VERSION ""

NS_ :

BS_:

BU_: BCMB_AUXM FCIM MRCMA_RSCM SCMJ BCMB_ALCM SCMB_PSM SCMD SCMC HVAC_RCCM MRCMB MRCMA DASM GFM_FTRM BCMB_CAPM DCMH SFMB SFMA SOBDMD_AHCM_FOH TRM GWM _delete BCMB_ABM SODL SCMF RTM RHVAC PDM DCMG DCMF DCME SCMH SCMG HSWM RSM SODR DDM RBM RGTM DSM SCME GENERIC TSTR
VAL_TABLE_ PersCtaSplitView_D_Rq 3 "EnabledFull" 2 "Enabled_180SwitchOnly" 1 "Disabled" 0 "Null" ;
VAL_TABLE_ HvacMde_D_ET 7 "NotUsed_4" 6 "NotUsed_3" 5 "NotUsed_2" 4 "NotUsed_1" 3 "Auto" 2 "MaxDefrost" 1 "MaxAc" 0 "Null" ;
VAL_TABLE_ SeatTe_D_ET 15 "NotUsed_7" 14 "NotUsed_6" 13 "NotUsed_5" 12 "NotUsed_4" 11 "NotUsed_3" 10 "NotUsed_2" 9 "NotUsed_1" 8 "Auto" 7 "Cooled3" 6 "Cooled2" 5 "Cooled1" 4 "Heated3" 3 "Heated2" 2 "Heated1" 1 "Off" 0 "Null" ;
VAL_TABLE_ Null_Off_On_Auto 3 "Auto" 2 "On" 1 "Off" 0 "Null" ;
VAL_TABLE_ NotDetClosedAjarDisabled 5 "NotUsed_2" 4 "NotUsed_1" 3 "Disabled" 2 "Ajar" 1 "Closed" 0 "NotDetermined" 7 "Faulty" 6 "NotUsed_3" ;
VAL_TABLE_ TwoStatePressedNotPressed 3 "NotDetermined" 2 "SwitchState2" 1 "SwitchState1" 0 "NotPressed" ;
VAL_TABLE_ Rear_Temp 15 "NotUsed_6" 14 "NotUsed_5" 13 "NotUsed_4" 12 "NotUsed_3" 11 "NotUsed_2" 10 "NotUsed_1" 9 "Max_Heating" 8 "Level_3_Heating" 7 "Level_2_Heating" 6 "Level_1_Heating" 5 "No_Heating_Cooling" 4 "Level_1_Cooling" 3 "Level_2_Cooling" 2 "Level_3_Cooling" 1 "Max_Cooling" 0 "No_Request" ;
VAL_TABLE_ DrHandle_D_Stat 7 "NotUsed" 6 "Transition" 5 "FlushFault" 4 "DeployFault2" 3 "DeployFault1" 2 "Flush" 1 "Deploy" 0 "None" ;
VAL_TABLE_ HvacCmprLim_D_Stat 7 "NotUsed_2" 6 "NotUsed_1" 5 "CompressorHeadPressure" 4 "AvailableTorque" 3 "PedalPosition" 2 "RPM" 1 "ECT" 0 "NoLimit" ;
VAL_TABLE_ VehOnSrc_D_Stat 15 "NotUsed_11" 14 "NotUsed_10" 13 "NotUsed_9" 12 "NotUsed_8" 11 "NotUsed_7" 10 "NotUsed_6" 9 "EsclRssd" 8 "AutonomousVehicle" 7 "SecureIdle" 6 "FleetVehicleInhibit" 5 "StolenVehicleInhibit" 4 "OverTheAir" 3 "RemoteParkAssist" 2 "RemoteStart" 1 "Manual" 0 "Off" ;
VAL_TABLE_ NoMessage_Msg1_63 31 "Message31" 30 "Message30" 29 "Message29" 28 "Message28" 27 "Message27" 26 "Message26" 25 "Message25" 24 "Message24" 23 "Message23" 22 "Message22" 21 "Message21" 20 "Message20" 19 "Message19" 18 "Message18" 17 "Message17" 16 "Message16" 15 "Message15" 14 "Message14" 13 "Message13" 12 "Message12" 11 "Message11" 10 "Message10" 9 "Message9" 8 "Message8" 7 "Message7" 6 "Message6" 5 "Message5" 4 "Message4" 3 "Message3" 2 "Message2" 1 "Message1" 0 "NoMessage" 63 "Message63" 47 "Message47" ;
VAL_TABLE_ TrlrRvrseEnbl_D2_Stat 7 "NotUsed" 6 "TbaActiveExpertActive" 5 "TbaActiveExpertAvail" 4 "TbaOffTrgActive" 3 "TbaOffTrgSetup" 2 "TbaSetup" 1 "TbaActive" 0 "Inactive" ;
VAL_TABLE_ SwitchNotActive_Active 1 "Switch_Active" 0 "Switch_Not_Active" ;
VAL_TABLE_ LcwaLeft_D_Stat 7 "Faulty" 6 "NotUsed_3" 5 "NotUsed_2" 4 "NotUsed_1" 3 "Disabled" 2 "TemporaryUnavailable" 1 "SensorBlocked" 0 "Available" ;
VAL_TABLE_ SeatMasgDrvRr_D_Stat 15 "NotUsed_10" 14 "NotUsed_9" 13 "NotUsed_8" 12 "NotUsed_7" 11 "NotUsed_6" 10 "Pattern10" 9 "Pattern9" 8 "Pattern8" 7 "Pattern7" 6 "Pattern6" 5 "Pattern5" 4 "Pattern4" 3 "Pattern3" 2 "Pattern2" 1 "Pattern1" 0 "Null" ;
VAL_TABLE_ CamraRearOn_D2_Stat2 7 "Faulty" 6 "NotUsed_3" 5 "NotUsed_2" 4 "NotUsed_1" 3 "Decommission" 2 "Activate" 1 "Deactivate" 0 "Null" ;
VAL_TABLE_ OffNormalSoft 3 "NotUsed" 2 "Soft" 1 "Normal" 0 "Off" ;
VAL_TABLE_ OffOnDisabledInhibited 3 "Inhibited" 2 "Disabled" 1 "On" 0 "Off" ;
VAL_TABLE_ SldrrMsgTxt_D2_Rq 7 "NotUsed_3" 6 "NotUsed_2" 5 "NotUsed_1" 4 "SlidingDrCalibNeeded2" 3 "SlidingDrOpenCltchReleased" 2 "SlidingDrCalibNeeded" 1 "SlidingDrClutchReleased" 0 "Null" ;
VAL_TABLE_ SeatPsngrMem_D_Cmd 15 "NotUsed_7" 14 "NotUsed_6" 13 "NotUsed_5" 12 "NotUsed_4" 11 "NotUsed_3" 10 "NotUsed_2" 9 "NotUsed_1" 8 "RECALL_4" 7 "RECALL_3" 6 "RECALL_2" 5 "RECALL_1" 4 "STORE_4" 3 "STORE_3" 2 "STORE_2" 1 "STORE_1" 0 "Null" ;
VAL_TABLE_ Null_NoFault_Fault 3 "NotUsed" 2 "Fault" 1 "NoFault" 0 "Null" ;
VAL_TABLE_ PrkAsstSlotId_D_Stat 7 "Faulty" 6 "Slot6" 5 "Slot5" 4 "Slot4" 3 "Slot3" 2 "Slot2" 1 "Slot1" 0 "NoSlotFound" ;
VAL_TABLE_ SodSlotLeft_D_Stat 7 "Faulty" 6 "Slot6" 5 "Slot5" 4 "Slot4" 3 "Slot3" 2 "Slot2" 1 "Slot1" 0 "NoSlotFound" ;
VAL_TABLE_ PwStepLeft_D_Rq 1 "Deploy" 0 "Null" 3 "NotUsed" 2 "Stow" ;
VAL_TABLE_ SldrlUnlckSwtch_D_Stat 3 "InnerHandle" 2 "RearInteriorSwitch" 1 "IpSwitch" 0 "Null" ;
VAL_TABLE_ SldrlChime_D_Rq 7 "NotUsed3" 6 "NotUsed2" 5 "NotUsed1" 4 "Warning" 3 "WarningRepeated" 2 "Programming" 1 "Operation" 0 "Off" ;
VAL_TABLE_ Sldrl_D_Stat 3 "NotCalibrated" 2 "Closing" 1 "Opening" 0 "NotMoving" ;
VAL_TABLE_ BalrInnrLeft_D_Stat 3 "Reporting" 2 "NotReporting" 1 "SystemStandby" 0 "Initialization" ;
VAL_TABLE_ Zero_1_2_4 3 "Four" 2 "Two" 1 "One" 0 "Zero" ;
VAL_TABLE_ NoReq_AutoUp_Stop 3 "NotUsed" 2 "Stop" 1 "AutoUp" 0 "NoRequest" ;
VAL_TABLE_ BalrSnsLeft_D_Falt 3 "Invalid" 2 "SystemFailure" 1 "Blocked" 0 "Clear" ;
VAL_TABLE_ Null_Low_Med_High 3 "High" 2 "Medium" 1 "Low" 0 "Null" ;
VAL_TABLE_ Null_NotPressed_Pressed 3 "NotUsed" 2 "Pressed" 1 "NotPressed" 0 "Null" ;
VAL_TABLE_ Low_Med_High 3 "NotUsed" 2 "High" 1 "Medium" 0 "Low" ;
VAL_TABLE_ TailLghtLoadMde_D_Stat 7 "Faulty" 6 "NotUsed_2" 5 "NotUsed_1" 4 "TailLightModeOverride" 3 "FalrModeActive" 2 "HitchLoadModeActive" 1 "PayloadModeActive" 0 "NoTailLightActive" ;
VAL_TABLE_ Set_Temp_Dig2 15 "Blank2" 14 "Blank1" 13 "I" 12 "H" 11 "O" 10 "L" 9 "_9" 8 "_8" 7 "_7" 6 "_6" 5 "_5" 4 "_4" 3 "_3" 2 "_2" 1 "_1" 0 "_0" ;
VAL_TABLE_ Manual_Temp_Setting 31 "Full_Heat" 30 "Setting_30" 29 "Setting_29" 28 "Setting_28" 27 "Setting_27" 26 "Setting_26" 25 "Setting_25" 24 "Setting_24" 23 "Setting_23" 22 "Setting_22" 21 "Setting_21" 20 "Setting_20" 19 "Setting_19" 18 "Setting_18" 17 "Setting_17" 16 "Setting_16" 15 "Setting_15" 14 "Setting_14" 13 "Setting_13" 12 "Setting_12" 11 "Setting_11" 10 "Setting_10" 9 "Setting_9" 8 "Setting_8" 7 "Setting_7" 6 "Setting_6" 5 "Setting_5" 4 "Setting_4" 3 "Setting_3" 2 "Setting_2" 1 "Full_Cool" 0 "Off" ;
VAL_TABLE_ Low_Med_High_Faulty 3 "Faulty" 2 "High" 1 "Medium" 0 "Low" ;
VAL_TABLE_ PulledAtRest 1 "Pulled" 0 "AtRest" ;
VAL_TABLE_ TrlrAidMsgTxt_D2_Rq 63 "Message63" 62 "Message62" 61 "Message61" 60 "Message60" 55 "Message55" 50 "Message50" 45 "Message45" 40 "Message40" 35 "Message35" 31 "Message31" 30 "Message30" 29 "Message29" 28 "Message28" 27 "Message27" 26 "Message26" 25 "Message25" 24 "Message24" 23 "Message23" 22 "Message22" 21 "Message21" 20 "Message20" 19 "Message19" 18 "Message18" 17 "Message17" 16 "Message16" 15 "Message15" 14 "Message14" 13 "Message13" 12 "Message12" 11 "Message11" 10 "Message10" 9 "Message9" 8 "Message8" 7 "Message7" 6 "Message6" 5 "Message5" 4 "Message4" 3 "Message3" 2 "Message2" 1 "Message1" 0 "NoMessage" ;
VAL_TABLE_ TrlrAidEnbl_D2_Stat 7 "NotUsed_1" 6 "TbaActiveExpertActive" 5 "TbaActiveExpertAvail" 4 "TbaOffTrgActive" 3 "TbaOffTrgSetup" 2 "TbaSetup" 1 "TbaActive" 0 "Inactive" ;
VAL_TABLE_ RbaCta_D_Stat 7 "Faulty" 6 "NotUsed_2" 5 "NotUsed_1" 4 "Invalid" 3 "Disabled" 2 "On" 1 "Trailer_Tow_Off" 0 "Off" ;
VAL_TABLE_ SeatFnChng2 15 "Faulty" 14 "NotUsed9" 13 "NotUsed8" 12 "NotUsed7" 11 "NotUsed6" 10 "High_2" 9 "Med_2" 8 "Low_2" 7 "Off_2" 6 "High" 5 "Low" 4 "Off" 3 "Decrease" 2 "Increase" 1 "NotUsed1" 0 "Inactive" ;
VAL_TABLE_ OffOnDisabledNotUsed 3 "NotUsed" 2 "Disabled" 1 "On" 0 "Off" ;
VAL_TABLE_ Off_On_NotUsed 3 "NotUsed_2" 2 "NotUsed_1" 1 "On" 0 "Off" ;
VAL_TABLE_ RbaSys_D_Stat 3 "Faulty" 2 "Available" 1 "Suspended" 0 "Disabled" ;
VAL_TABLE_ SeatLmbr_D_Rq 15 "NotUsed_7" 14 "NotUsed_6" 13 "NotUsed_5" 12 "NotUsed_4" 11 "NotUsed_3" 10 "NotUsed_2" 9 "NotUsed_1" 8 "PassengerDown" 7 "PassengerUp" 6 "PassengerAft" 5 "PassengerFore" 4 "DriverDown" 3 "DriverUp" 2 "DriverAft" 1 "DriverFore" 0 "Null" ;
VAL_TABLE_ Inactive_Enable_Disable 0 "Inactive" 2 "Disable" 1 "Enable" ;
VAL_TABLE_ PmSnsCabn_D_Stat 7 "NotUsed_1" 6 "IntermittentInhibit" 5 "NoIssue" 4 "BlankField" 3 "ReplaceSensor" 2 "CleanSensor" 1 "Unsupported" 0 "Initializing" ;
VAL_TABLE_ Null_Off_LowMedHigh 7 "NotUsed_3" 6 "NotUsed_2" 5 "NotUsed_1" 4 "High" 3 "Medium" 2 "Low" 1 "Off" 0 "Null" ;
VAL_TABLE_ SeatMasgDrv_D_Stat 15 "NotUsed_10" 14 "NotUsed_9" 13 "NotUsed_8" 12 "NotUsed_7" 11 "NotUsed_6" 10 "Pattern10" 9 "Pattern9" 8 "Pattern8" 7 "Pattern7" 6 "Pattern6" 5 "Pattern5" 4 "Pattern4" 3 "Pattern3" 2 "Pattern2" 1 "Pattern1" 0 "Null" ;
VAL_TABLE_ ClimtSeat_D_Rq 128 "H3_High_Heat_MAX" 64 "H2_Medium_Heat" 32 "H1_Low_Heat" 16 "C3_High_Cool_MAX" 8 "C2_Medium_Cool" 4 "C1_Low_Cool" 2 "Off" ;
VAL_TABLE_ NoFault_Fault 1 "Fault" 0 "No_Fault" ;
VAL_TABLE_ ClimtRearView_D_Stat 3 "ThirdRow" 2 "SecondRow" 1 "Both" 0 "NotDisplayed" ;
VAL_TABLE_ NoInhibit_Inhibit 1 "Inhibit" 0 "NoInhibit" ;
VAL_TABLE_ PersRecallSrc_D_Actl 7 "NotUsed_3" 6 "NotUsed_2" 5 "NotUsed_1" 4 "MemorySwitch" 3 "RemoteStart" 2 "KeyFob" 1 "CenterStack" 0 "Null" ;
VAL_TABLE_ TrnkFrontRleas_D_Src 7 "NotUsed_3" 6 "NotUsed_2" 5 "NotUsed_1" 4 "Cpp" 3 "Sync" 2 "Keypad" 1 "Remote" 0 "Null" ;
VAL_TABLE_ Frt_Btn_Status_1st 4 "Floor_Ws_Pressed" 5 "AC_Pressed" 6 "Dual_Pressed" 7 "LHS_Temp_Inc_Pressed" 0 "None_Pressed" 1 "Panel_Pressed" 2 "Panel_Floor_Pressed" 3 "Floor_Pressed" 8 "LHS_Temp_Dec_Pressed" 9 "RHS_Temp_Inc_Pressed" 10 "RHS_Temp_Dec_Pressed" 11 "Blwr_Inc_Pressed" 12 "Blwr_Dec_Pressed" 13 "AUTO_Pressed" 14 "Max_AC_Pressed" 15 "Recirc_Pressed" 16 "Outside_Pressed" 17 "Auto_Recirc_Pressed" 18 "Htd_Frt_Wsh_Pressed" 19 "Windscreen_Pressed" 20 "Pnl_Ws_Pressed" 21 "Pnl_Flr_Ws_Pressed" 22 "Rear_Defrost_Pressed" 23 "Front_Power_Pressed" 24 "My_Temp_Pressed" 25 "Max_Defrost_Pressed" 26 "LHS_Htd_Seat_Pressed" 27 "RHS_Htd_Seat_Pressed" 28 "LHS_Cld_Seat_Pressed" 29 "RHS_Cld_Seat_Pressed" 30 "Htg_Strg_Whl_Pressed" 31 "Defrost_Pressed" 37 "DrvrFcsdMde_PRessed" 38 "LHS_Seat_Off_Pressed" 39 "LHS_Htd_Seat1_Pressed" 40 "LHS_Htd_Seat2_Pressed" 41 "LHS_Htd_Seat3_Pressed" 42 "LHS_Auto_Seat_Pressed" 43 "RHS_Seat_Off_Pressed" 44 "RHS_Htd_Seat1_Pressed" 45 "RHS_Htd_Seat2_Pressed" 46 "RHS_Htd_Seat3_Pressed" 47 "RHS_Auto_Seat_Pressed" 48 "LHS_Cld_Seat1_Pressed" 49 "LHS_Cld_Seat2_Pressed" 50 "LHS_Cld_Seat3_Pressed" 51 "RHS_Cld_Seat1_Pressed" 52 "RHS_Cld_Seat2_Pressed" 53 "RHS_Cld_Seat3_Pressed" 54 "AUTO_Lo_Pressed" 55 "AUTO_Med_Pressed" 56 "AUTO_Hi_Pressed" 57 "AUTO_Inc_Pressed" 58 "AUTO_Dec_Pressed" 59 "NotUsed_6" 60 "NotUsed_7" 61 "NotUsed_8" 62 "NotUsed_9" 63 "NotUsed_10" 32 "FrontMnu_Pressed" 33 "RearMnu_Pressed" 34 "Heat_Pressed" 35 "AAR_Pressed" 36 "MdeMnu_Pressed" ;
VAL_TABLE_ TrlrAlarmSpprt_D_Stat 3 "SupportedByBrakesAndLights" 2 "SupportedByLights" 1 "SupportedByBrakes" 0 "NotSupported" ;
VAL_TABLE_ Null_Extend_Retract 3 "NotUsed" 2 "Retract" 1 "Extend" 0 "Null" ;
VAL_TABLE_ SeatSlprPosPsngr_D_Stat 3 "Faulty" 2 "Sleeper" 1 "Upright" 0 "Null" ;
VAL_TABLE_ Psngr_Set_Temp 31 "HI" 30 "_29_5" 29 "_29_0" 28 "_28_5" 27 "_28_0" 26 "_27_5" 25 "_27_0" 24 "_26_5" 23 "_26_0" 22 "_25_5" 21 "_25_0" 20 "_24_5" 19 "_24_0" 18 "_23_5" 17 "_23_0" 16 "_22_5" 15 "_22_0" 14 "_21_5" 13 "_21_0" 12 "_20_5" 11 "_20_0" 10 "_19_5" 9 "_19_0" 8 "_18_5" 7 "_18_0" 6 "_17_5" 5 "_17_0" 4 "_16_5" 3 "_16_0" 2 "_15_5" 1 "LO" 0 "No_Request" ;
VAL_TABLE_ Frt_Blower_Speed2 15 "NotUsed_6" 14 "NotUsed_5" 13 "NotUsed_4" 12 "NotUsed_3" 11 "NotUsed_2" 10 "Zero_Blower" 9 "Max_Blower" 8 "Min_Blower" 7 "Blower_Speed_7" 6 "Blower_Speed_6" 5 "Blower_Speed_5" 4 "Blower_Speed_4" 3 "Blower_Speed_3" 2 "Blower_Speed_2" 1 "Blower_Speed_1" 0 "No_Request" ;
VAL_TABLE_ KeyPadCodeDgt1_D_Stat 15 "NotUsed_4" 14 "NotUsed_3" 13 "NotUsed_2" 12 "NotUsed_1" 11 "Button7_8and9_0" 10 "Button0" 9 "Button9_0or9" 8 "Button8" 7 "Button7_8or7" 6 "Button6" 5 "Button5_6or5" 4 "Button4" 3 "Button3_4or3" 2 "Button2" 1 "Button1_2or1" 0 "EndofString" ;
VAL_TABLE_ E_Frt_Btn_Status_1st 63 "NotUsed_10" 62 "NotUsed_9" 61 "NotUsed_8" 60 "NotUsed_7" 59 "NotUsed_6" 58 "NotUsed_5" 57 "NotUsed_4" 56 "NotUsed_3" 55 "NotUsed_2" 54 "NotUsed_1" 53 "RHS_Cld_Seat3_Pressed" 52 "RHS_Cld_Seat2_Pressed" 51 "RHS_Cld_Seat1_Pressed" 50 "LHS_Cld_Seat3_Pressed" 49 "LHS_Cld_Seat2_Pressed" 48 "LHS_Cld_Seat1_Pressed" 47 "RHS_Auto_Seat_Pressed" 46 "RHS_Htd_Seat3_Pressed" 45 "RHS_Htd_Seat2_Pressed" 44 "RHS_Htd_Seat1_Pressed" 43 "RHS_Seat_Off_Pressed" 42 "LHS_Auto_Seat_Pressed" 41 "LHS_Htd_Seat3_Pressed" 40 "LHS_Htd_Seat2_Pressed" 39 "LHS_Htd_Seat1_Pressed" 38 "LHS_Seat_Off_Pressed" 37 "DrvrFcsdMde_Pressed" 36 "MdeMnu_Pressed" 35 "AAR_Pressed" 34 "Heat_Pressed" 33 "RearMnu_Pressed" 32 "FrontMnu_Pressed" 31 "Defrost_Pressed" 30 "Htg_Strg_Whl_Pressed" 29 "RHS_Cld_Seat_Pressed" 28 "LHS_Cld_Seat_Pressed" 27 "RHS_Htd_Seat_Pressed" 26 "LHS_Htd_Seat_Pressed" 25 "Max_Defrost_Pressed" 24 "My_Temp_Pressed" 23 "Front_Power_Pressed" 22 "Rear_Defrost_Pressed" 21 "Pnl_Flr_Ws_Pressed" 20 "Pnl_Ws_Pressed" 19 "Windscreen_Pressed" 18 "Htd_Frt_Wsh_Pressed" 17 "Auto_Recirc_Pressed" 16 "Outside_Pressed" 15 "Recirc_Pressed" 14 "Max_AC_Pressed" 13 "Auto_Pressed" 12 "Blwr_Dec_Pressed" 11 "Blwr_Inc_Pressed" 10 "RHS_Temp_Dec_Pressed" 9 "RHS_Temp_Inc_Pressed" 8 "LHS_Temp_Dec_Pressed" 7 "LHS_Temp_Inc_Pressed" 6 "Dual_Pressed" 5 "AC_Pressed" 4 "Floor_Ws_Pressed" 3 "Floor_Pressed" 2 "Panel_Floor_Pressed" 1 "Panel_Pressed" 0 "None_Pressed" ;
VAL_TABLE_ Null_Restricted_NotRestricted 3 "NotUsed" 2 "NotRestricted" 1 "Restricted" 0 "Null" ;
VAL_TABLE_ UltraFreshCabn_D_Stat 7 "NotUsed_2" 6 "NotUsed_1" 5 "NotSupported" 4 "Interrupted" 3 "Complete" 2 "Active" 1 "Inactive" 0 "Null" ;
VAL_TABLE_ GearLvr_D_ActlDrv 15 "Fault" 14 "Unknown_Position" 13 "NotUsed_2" 12 "NotUsed_1" 11 "Range6" 10 "Range5" 9 "Range4" 8 "Range3_M3_L3" 7 "Range2_M2_L2" 6 "Range1_M1_L1" 5 "Low" 4 "Sport_DriveSport_Mposition" 3 "Drive" 2 "Neutral" 1 "Reverse" 0 "Park" ;
VAL_TABLE_ TrnPrkSys_D_Actl 15 "Faulty" 14 "NotUsed_5" 13 "NotUsed_4" 12 "NotUsed_3" 11 "NotUsed_2" 10 "NotUsed_1" 9 "FrequencyError" 8 "OutOfRangeHigh" 7 "OutOfRangeLow" 6 "Override" 5 "OutOfPark" 4 "TransitionCloseToOutOfPark" 3 "AtNoSpring" 2 "TransitionCloseToPark" 1 "Park" 0 "NotKnown" ;
VAL_TABLE_ OKLowUnknownInvalid 3 "Invalid" 2 "Unknown" 1 "Low" 0 "OK" ;
VAL_TABLE_ Dsp_RotAddrBtnEv_St 15 "NotUsed_1" 14 "Pos_7Steps" 13 "Pos_6Steps" 12 "Pos_5Steps" 11 "Pos_4Steps" 10 "Pos_3Steps" 9 "Pos_2Steps" 8 "Pos_1Step" 7 "NotPressed" 6 "Neg_1Steps" 5 "Neg_2Steps" 4 "Neg_3Steps" 3 "Neg_4Steps" 2 "Neg_5Steps" 1 "Neg_6Steps" 0 "Neg_7Steps" ;
VAL_TABLE_ Pers1Phone_D_Stat 7 "SevenPhoneAssociated" 6 "SixPhoneAssociated" 5 "FivePhoneAssociated" 4 "FourPhoneAssociated" 3 "ThreePhoneAssociated" 2 "TwoPhoneAssociated" 1 "OnePhoneAssociated" 0 "NoPhoneAssociated" ;
VAL_TABLE_ GasPrtc_D_RqDsply 7 "NotUsed_5" 6 "NotUsed_4" 5 "NotUsed_3" 4 "NotUsed_2" 3 "NotUsed_1" 2 "GpfOverLimit" 1 "GpfAtLimit" 0 "NormalOperation" ;
VAL_TABLE_ Memory_2_SwPsngr_Stat 1 "Pressed" 0 "Null" ;
VAL_TABLE_ Pers3Key_D_Stat 3 "NotUsed_1" 2 "KeyUnAssociated" 1 "KeyAssociated" 0 "Null" ;
VAL_TABLE_ WakeAlarm0_B_Typ 1 "CanAndEcuDriveCircuit" 0 "CanOnly" ;
VAL_TABLE_ EmPrflNo_D_Rq 7 "NotUsed_3" 6 "NotUsed_2" 5 "NotUsed_1" 4 "Pers4" 3 "Pers3" 2 "Pers2" 1 "Pers1" 0 "Null" ;
VAL_TABLE_ EmPrflKeyAssoc_D_Rq 7 "NotUsed_3" 6 "DisassociatePhone" 5 "EnterPhoneAssociation" 4 "OverwriteKey" 3 "DisassociateKey" 2 "ExitKeyAssociation" 1 "EnterKeyAssociation" 0 "Null" ;
VAL_TABLE_ EmButtn_D_Stat 7 "ButtonAssociationFailed" 6 "ButtonAssociationExited" 5 "ButtonAssociationEntered" 4 "Button4Pressed" 3 "Button3Pressed" 2 "Button2Pressed" 1 "Button1Pressed" 0 "Null" ;
VAL_TABLE_ EmPrflButtnAssoc_D_Rq 3 "NotUsed" 2 "ExitButtonAssociation" 1 "EnterButtonAssociation" 0 "Null" ;
VAL_TABLE_ EmPrflNo_D_Stat 7 "NotUsed_3" 6 "NotUsed_2" 5 "NotUsed_1" 4 "Pers4" 3 "Pers3" 2 "Pers2" 1 "Pers1" 0 "Null" ;
VAL_TABLE_ EmPrflKeyAssoc_D_Stat 7 "WrongDevice" 6 "KeyAssociateFailed" 5 "KeyAssociateSuccess" 4 "KeyAlreadyInUse" 3 "KeyDisassociated" 2 "KeyAssociationExited" 1 "KeyAssociationEntered" 0 "Null" ;
VAL_TABLE_ PersNo_D_Actl 7 "Unused_3" 6 "Unused_2" 5 "NotDetermined" 4 "Vehicle" 3 "PERS_4" 2 "PERS_3" 1 "PERS_2" 0 "PERS_1" ;
VAL_TABLE_ Closed_Open_Active_Denied 3 "Denied" 2 "Active" 1 "Open" 0 "Closed" ;
VAL_TABLE_ KeyOffMde_D_Actl 15 "NotUsed_11" 14 "NotUsed_10" 13 "NotUsed_9" 12 "NotUsed_8" 11 "NotUsed_7" 10 "NotUsed_6" 9 "NotUsed_5" 8 "NotUsed_4" 7 "NotUsed_3" 6 "NotUsed_2" 5 "NotUsed_1" 4 "CriticalBattery" 3 "Hibernate" 2 "Transport" 1 "Factory" 0 "Normal" ;
VAL_TABLE_ SelDrvMdeSwtch 3 "Faulty" 2 "SwitchState2" 1 "SwitchState1" 0 "NotPressed" ;
VAL_TABLE_ SelDrvMdePt_D_Rq 31 "Faulty" 30 "NotUsed15" 29 "NotUsed14" 28 "NotUsed13" 27 "NotUsed12" 26 "NotUsed11" 25 "NotUsed10" 24 "NotUsed9" 23 "NotUsed8" 22 "NotUsed7" 21 "CustomMode" 20 "TrackMode" 19 "OnePedalDrive" 18 "EvLaterChargerMode" 17 "EvNowMode" 16 "DragMode" 15 "HighSpeedDesertMode_Baja" 14 "SportAdaptiveMode" 13 "NotAvailable_13" 12 "NotAvailable_12" 11 "NotAvailable_11" 10 "NotAvailable_10" 9 "RockCrawlMode" 8 "MudRutsMode" 7 "SandMode" 6 "EconomyMode" 5 "GrassGravelSnow" 4 "NotAvailable_04" 3 "TowHaulMode" 2 "NotAvailable_02" 1 "SportMode" 0 "NormalMode" ;
VAL_TABLE_ OffLockUnlockFaulty 3 "Faulty" 2 "Unlock" 1 "Lock" 0 "Off" ;
VAL_TABLE_ PwStep_D_Stat 3 "PositionNotKnown" 2 "StepsNotStowed" 1 "StepsStowed" 0 "Off" ;
VAL_TABLE_ PwStep_D_DrvInhbt 3 "NotUsed" 2 "DriveInhibitMalfunction" 1 "DriveInhibited" 0 "DriveNotInhibited" ;
VAL_TABLE_ PwStepMsgTxt_D_Rq 1 "DriveInhibited" 0 "NoMessage" 3 "NotUsed" 2 "Malfunction" ;
VAL_TABLE_ OffLowMedHigh 3 "High" 2 "Medium" 1 "Low" 0 "Off" ;
VAL_TABLE_ ApaSteScanMde_D_Stat 3 "Steering" 2 "Scanning" 1 "NotScanning" 0 "Null" ;
VAL_TABLE_ Off_On_Unknown_Invalid 3 "Invalid" 2 "Unknown" 1 "On" 0 "Off" ;
VAL_TABLE_ HeadLghtOn_D_Rq 7 "NotUsed2" 6 "NotUsed1" 5 "DrlBoth" 4 "DrlRight" 3 "DrlLeft" 2 "High" 1 "Low" 0 "Off" ;
VAL_TABLE_ SeatPos_D_Stat 7 "NotUsed3" 6 "NotUsed2" 5 "Error" 4 "Drive" 3 "Moving" 2 "Pending" 1 "EasyEntry" 0 "Null" ;
VAL_TABLE_ CtaAlrt2_D_Stat 7 "NotUsed3" 6 "NotUsed2" 5 "NotUsed1" 4 "AlertZone4" 3 "AlertZone3" 2 "AlertZone2" 1 "AlertZone1" 0 "Off" ;
VAL_TABLE_ BttRightLeft_D_Stat 7 "NotUsed" 6 "Disabled" 5 "Off" 4 "OffTemp" 3 "NotConnected" 2 "Pending" 1 "Connected" 0 "NotDetermined" ;
VAL_TABLE_ Null_NoRequest_Request 3 "NotUsed" 2 "Request" 1 "NoRequest" 0 "Null" ;
VAL_TABLE_ LghtAmbIntns_D_Sns 3 "Faulty" 2 "High" 1 "Low" 0 "Null" ;
VAL_TABLE_ ACU_RadioSeekMode2_St 16 "ContAutoDown" 15 "ContAutoUp" 14 "PISeek" 13 "TpSeek" 12 "Autostore" 11 "PtySeekDown" 10 "PtySeekUp" 9 "ScanDown" 8 "ScanUp" 7 "ContManualDown" 6 "ContManualUp" 5 "ManSingleStepDown" 4 "ManSingleStepUp" 3 "AutoDown" 2 "AutoUp" 1 "SeekOff" 0 "Invalid" ;
VAL_TABLE_ ACU_CurrTUBand_St 10 "SAT2" 9 "SAT1" 8 "DAB2" 7 "DAB1" 6 "Fm3" 5 "AmAst" 4 "Am" 3 "FmAst" 2 "Fm2" 1 "Fm1" 0 "Invalid" 13 "reserved1" 15 "reserved_last" 12 "DAB3" 11 "SAT3" ;
VAL_TABLE_ SuspDrvMde_D_Rq 7 "Faulty" 6 "NotUsed2" 5 "NotUsed1" 4 "Drag" 3 "Track" 2 "Snow_Wet" 1 "Sport" 0 "Normal" ;
VAL_TABLE_ NotPressed_PressedNotUsed 3 "NotUsed2" 2 "NotUsed1" 1 "Pressed" 0 "Not_Pressed" ;
VAL_TABLE_ NotInstalled_Installed_Faulty 3 "Faulty" 2 "NotUsed" 1 "Installed" 0 "NotInstalled" ;
VAL_TABLE_ CnvtTopMsgTxt_D_Rq 3 "NotSecure" 2 "NotAvailable" 1 "RemoveCaps" 0 "NoWarning" ;
VAL_TABLE_ NoModeSelOffOnNotUsed 3 "NotUsed" 2 "On" 1 "Off" 0 "NoModeSelected" ;
VAL_TABLE_ LsmcBrkDecel_D_Stat 7 "NotUsed_3" 6 "NotUsed_2" 5 "NotUsed_1" 4 "Denied" 3 "FaultDegraded" 2 "FaultExt" 1 "On" 0 "Off" ;
VAL_TABLE_ OffOn_RampUpDown 3 "Ramp_Down" 2 "Ramp_Up" 1 "On" 0 "Off" ;
VAL_TABLE_ NoMessage_Msg1_7 7 "Message7" 6 "Message6" 5 "Message5" 4 "Message4" 3 "Message3" 2 "Message2" 1 "Message1" 0 "NoMessage" ;
VAL_TABLE_ LnchCtl 3 "NotUsed2" 2 "NotUsed1" 1 "LC_On" 0 "LC_Off" ;
VAL_TABLE_ LnchCtlSys_D_Stat 7 "NotUsed3" 6 "NotUsed2" 5 "NotUsed1" 4 "On_LC_Unavailable_TC_On" 3 "On_LC_Unavailable" 2 "On_LC_Available" 1 "On_LC_Active" 0 "LC_OFF" ;
VAL_TABLE_ NotPressed_Pressed_Faulty 3 "Faulty" 2 "NotUsed" 1 "Pressed" 0 "Not_Pressed" ;
VAL_TABLE_ IsaOffst_D_Stat 15 "Faulty" 14 "Null" 13 "Thirteen" 12 "Twelve" 11 "Eleven" 10 "Ten" 9 "Nine" 8 "Eight" 7 "Seven" 6 "Six" 5 "Five" 4 "Four" 3 "Three" 2 "Two" 1 "One" 0 "Zero" ;
VAL_TABLE_ SlMde_D_Rq 3 "IsaNotConfigured" 2 "Manual_Mode" 1 "Auto_Mode" 0 "Null" ;
VAL_TABLE_ OffOn_NotUsed_NoData 3 "No_Data_Present" 2 "NotUsed" 1 "On" 0 "Off" ;
VAL_TABLE_ Faulty_FF 255 "Faulty" ;
VAL_TABLE_ BrkDrvMde_D_Rq 7 "Faulty" 6 "RockCrawl" 5 "Baja" 4 "DragOrMudAndSand" 3 "Track" 2 "Snow_Wet" 1 "Sport" 0 "Normal" ;
VAL_TABLE_ Null_Off_On 3 "NotUsed" 2 "On" 1 "Off" 0 "Null" ;
VAL_TABLE_ Faulty_1FFF 8191 "Faulty" ;
VAL_TABLE_ VehStab_D_Stat 15 "Faulty" 14 "No_Data_Exists" 13 "NotUsed6" 12 "NotUsed5" 11 "NotUsed4" 10 "NotUsed3" 9 "NotUsed2" 8 "Combined_OS_and_US" 7 "High_SSRA_no_OS" 6 "Straight" 5 "Post_Oversteer" 4 "Post_Transition" 3 "Countersteer" 2 "Understeer" 1 "Oversteer" 0 "Linear" ;
VAL_TABLE_ CnvtTopTrgt_D_Rq 7 "NotUsed4" 6 "NotUsed3" 5 "NotUsed2" 4 "NotUsed1" 3 "OpenTarget" 2 "OpenPosition" 1 "ClosePosition" 0 "CloseTarget" ;
VAL_TABLE_ CnvtTopPos_D_Stat 15 "Faulty" 14 "NotUsed7" 13 "NotUsed6" 12 "NotUsed5" 11 "NotUsed4" 10 "NotUsed3" 9 "NotUsed2" 8 "NotUsed1" 7 "ShutdownComplete" 6 "NoNormalised" 5 "Moving" 4 "PositionIntermediate" 3 "PositionOpenTarget" 2 "PositionOpenPosition" 1 "PositionClosePosition" 0 "PositionCloseTarget" ;
VAL_TABLE_ CnvtTopPar_D_Rq 7 "NotUsed" 6 "ForceIncrease3" 5 "ForceIncrease2" 4 "ForceIncrease1" 3 "NoAdapt" 2 "Teach" 1 "NoPwmNoAp" 0 "Normal" ;
VAL_TABLE_ CnvtTopComplt_D_Stat 7 "DenormalizingReady" 6 "NormalizingReady" 5 "RunoutComplete" 4 "StopByPositioning" 3 "StopByFault" 2 "StopByPinch" 1 "StopByStall" 0 "StopByRequest" ;
VAL_TABLE_ Inactive_Active_NotUsed_Faulty 3 "Faulty" 2 "NotUsed" 1 "Active" 0 "Inactive" ;
VAL_TABLE_ CnvtTop_D_Rq 7 "NotUsed" 6 "ResetErrorFlags" 5 "DiscardNormalization" 4 "SetNormalization" 3 "DirectDriveClose" 2 "DirectDriveOpen" 1 "DirectPosition" 0 "Stop" ;
VAL_TABLE_ NoData_Faulty_1FF_1FE 511 "Faulty" 510 "NoDataExists" ;
VAL_TABLE_ FohEng_D_Rq 3 "AutoEnable_ParkEnable" 2 "AutoDisable_ParkEnable" 1 "AutoEnable_ParkDisable" 0 "Disable_Stop" ;
VAL_TABLE_ Null_Hi_NotUsed_Low 3 "Low" 2 "Not_Used" 1 "High" 0 "Null" ;
VAL_TABLE_ Current_Color 15 "NotUsed7" 14 "NotUsed6" 13 "NotUsed5" 12 "NotUsed4" 11 "NotUsed3" 10 "NotUsed2" 9 "NotUsed1" 8 "Null" 7 "Color7" 6 "Color6" 5 "Color5" 4 "Color4" 3 "Color3" 2 "Color2" 1 "Color1" 0 "Off" ;
VAL_TABLE_ Blended_Color 15 "NotUsed10" 14 "NotUsed9" 13 "NotUsed8" 12 "NotUsed7" 11 "NotUsed6" 10 "NotUsed5" 9 "NotUsed4" 8 "NotUsed3" 7 "NotUsed2" 6 "NotUsed1" 5 "_5" 4 "_4" 3 "_3" 2 "_2" 1 "_1" 0 "Null" ;
VAL_TABLE_ OffOn_Null_NotUsed 3 "NotUsed" 2 "Null" 1 "On" 0 "Off" ;
VAL_TABLE_ Null_Pers1_4_Vehicle 7 "Unused_2" 6 "Unused_1" 5 "Vehicle" 4 "PERS_4" 3 "PERS_3" 2 "PERS_2" 1 "PERS_1" 0 "Null" ;
VAL_TABLE_ VehKeyActv_D_Stat 15 "NotUsed7" 14 "NotUsed6" 13 "NotUsed5" 12 "NotUsed4" 11 "NotUsed3" 10 "NotUsed2" 9 "NotUsed1" 8 "Key8Active" 7 "Key7Active" 6 "Key6Active" 5 "Key5Active" 4 "Key4Active" 3 "Key3Active" 2 "Key2Active" 1 "Key1Active" 0 "NoKeyActive" ;
VAL_TABLE_ VehLckInd_D_Rq 3 "NotUsed" 2 "On_Day" 1 "On_Night" 0 "Off" ;
VAL_TABLE_ TowBarMsgTxt_D_Rq 7 "NotUsed3" 6 "NotUsed2" 5 "NotUsed1" 4 "TowBar_Ext_No_Trlr" 3 "Error_Dealer_Fix" 2 "Start_Engine_Swivel" 1 "Check_Tow_Bar" 0 "Null" ;
VAL_TABLE_ SeatFnChng 15 "Faulty" 14 "NotUsed9" 13 "NotUsed8" 12 "NotUsed7" 11 "NotUsed6" 10 "NotUsed5" 9 "NotUsed4" 8 "NotUsed3" 7 "NotUsed2" 6 "High" 5 "Low" 4 "Off" 3 "Decrease" 2 "Increase" 1 "NotUsed1" 0 "Inactive" ;
VAL_TABLE_ NoData_Faulty_3E_3F 63 "Faulty" 62 "NoDataExists" ;
VAL_TABLE_ InactiveIncrementDecrement 3 "NotUsed" 2 "Decrement" 1 "Increment" 0 "Inactive" ;
VAL_TABLE_ Faulty_1FF 511 "Faulty" ;
VAL_TABLE_ Null_Off_On_Faulty 3 "Faulty" 2 "On" 1 "Off" 0 "Null" ;
VAL_TABLE_ Faulty_3FF 1023 "Faulty" ;
VAL_TABLE_ DynoMde_B_Cmd 1 "DynomometerMode" 0 "NormalOperation" ;
VAL_TABLE_ HvacPrecondRecirc_D_Rq 3 "Last_User_Setting" 2 "Auto" 1 "Recirc" 0 "Outside" ;
VAL_TABLE_ HvacPrecondAC_D_Rq 3 "Last_User_Setting" 2 "Auto" 1 "On" 0 "Off" ;
VAL_TABLE_ HybMdeStat_D_Dsply 7 "NotUsed2" 6 "EV_Charge" 5 "EV_Override" 4 "Forced_EV_Mode" 3 "Forced_Charge_Sustain_Mode" 2 "Auto_Charge_Sustain_Mode" 1 "Auto_Charge_Deplete_Mode" 0 "Null_State" ;
VAL_TABLE_ NoData_Faulty_FFFE_FFFF 65535 "Faulty" 65534 "NoDataExists" ;
VAL_TABLE_ NoData_Faulty_FFE_FFF 4095 "Faulty" 4094 "NoDataExists" ;
VAL_TABLE_ PepsKeyActv_D_Stat 15 "NotUsed11" 14 "NotUsed10" 13 "NotUsed9" 12 "NotUsed8" 11 "NotUsed7" 10 "NotUsed6" 9 "NotUsed5" 8 "Key4Active" 7 "NotUsed4" 6 "NotUsed3" 5 "NotUsed2" 4 "Key3Active" 3 "NotUsed1" 2 "Key2Active" 1 "Key1Active" 0 "NoKeyActive" ;
VAL_TABLE_ CellLock_D_Rq_Rsm 7 "NotUsed3" 6 "NotUsed2" 5 "NotUsed1" 4 "TrunkRelPopGlassLgCargo" 3 "LockAllDoorsandTailgate" 2 "UnlockDriversDoor" 1 "UnlockAllDoorsandTailgate" 0 "NoRequest" ;
VAL_TABLE_ RmtCtl_D_Stat 15 "Faulty" 14 "NotUsed_5" 13 "NotUsed_4" 12 "NotUsed_3" 11 "NotUsed_2" 10 "NotUsed_1" 9 "Shutdown" 8 "ManeuverFinished" 7 "ReadyForResume" 6 "Pause" 5 "Maneuvering" 4 "ReadyForManeuvering" 3 "Activation" 2 "Initialize" 1 "Preparation" 0 "Disabled" ;
VAL_TABLE_ PwRnngBoardT_D_Rq 3 "NotUsed" 2 "Timer2" 1 "Timer1" 0 "Inactive" ;
VAL_TABLE_ PwRnngBoardT_D_Stat 3 "NotUsed" 2 "Timer2" 1 "Timer1" 0 "Inactive" ;
VAL_TABLE_ NotDeterminedNotPresentFaulty 3 "Faulty" 2 "Present" 1 "NotPresent" 0 "NotDetermined" ;
VAL_TABLE_ PwRnngBoardPoll_D_Stat 3 "NotUsed" 2 "PkPresent" 1 "PkNotPresent" 0 "NotPolling" ;
VAL_TABLE_ InactiveOffOutAuto 0 "Inactive" 1 "Off" 2 "Out" 3 "Auto" ;
VAL_TABLE_ PwRnngBoardSwtch_D_Rq 3 "NotUsed" 2 "DeployUnlocked" 1 "AlwaysActive" 0 "Inactive" ;
VAL_TABLE_ Null_NotAccepted_Accepted 3 "NotUsed" 2 "Accepted" 1 "NotAccepted" 0 "Null" ;
VAL_TABLE_ PoliceDmngLvl_D_Stat 7 "NotUsed" 6 "Off_Night" 5 "Off_Day" 4 "Low1Night" 3 "Low1Day" 2 "Inactive" 1 "Decommissioned" 0 "Null" ;
VAL_TABLE_ VehWlcmFrwl_D_Stat 3 "RunStart" 2 "Farewell" 1 "Welcome" 0 "Null" ;
VAL_TABLE_ VehWlcmFrwlMde_D_Stat 7 "IlluminatedExit" 6 "CourtesyLightingDelayExt" 5 "CourtesyLightingExtended" 4 "CourtesyLightingDelayAll" 3 "CourtesyLightingAll" 2 "IlluminatedEntry" 1 "Approach" 0 "Null" ;
VAL_TABLE_ MemStoreMsgTxt_D_Rq 10 "NotUsed_2" 9 "NotUsed_1" 8 "Mem4Saved_ShowLinkMsg" 7 "Mem3Saved_ShowLinkMsg" 6 "Mem2Saved_ShowLinkMsg" 5 "Mem1Saved_ShowLinkMsg" 4 "Mem4Saved_DoNotShowLinkMsg" 3 "Mem3Saved_DoNotShowLinkMsg" 2 "Mem2Saved_DoNotShowLinkMsg" 1 "Mem1Saved_DoNotShowLinkMsg" 0 "Null" ;
VAL_TABLE_ MemSetButtnMsgTxt_D_Rq 3 "NotUsed" 2 "Press1or2or3" 1 "Press1or2" 0 "Null" ;
VAL_TABLE_ DrTgateChime2_D_Rq 7 "NotUsed3" 6 "NotUsed2" 5 "NotUsed1" 4 "Long_Repeated" 3 "Fast" 2 "Short" 1 "Long" 0 "Off" ;
VAL_TABLE_ StopStrtDrvMde_D_Indic 3 "NotUsed" 2 "StartStop_IndirectDeselect" 1 "StopStart_Deselected" 0 "StopStart_Selected" ;
VAL_TABLE_ StopStrtStdby_D_Indic 6 "Telltale_On_Grey" 5 "Telltale_Struck_Out" 4 "Telltale_Flashing_Amber" 3 "Telltale_On_Amber" 2 "Telltale_Flashing_Green" 1 "Telltale_On_Green" 0 "Telltale_Off" 7 "NotUsed3" ;
VAL_TABLE_ Quality_Faulty 3 "OK" 2 "Degraded" 1 "No_Data_Exists" 0 "Faulty" ;
VAL_TABLE_ CtaInnr_D_Stat 3 "Reporting" 2 "Not_Reporting" 1 "System_Standby" 0 "Initialization" ;
VAL_TABLE_ FohMsgTxt_D_Rq 4 "BatteryNotFullyCharged" 3 "Exceed7DaysFromLastEngRun" 2 "AmbientTemperatureTooHigh" 1 "LowFuel" 0 "NoMessage" ;
VAL_TABLE_ FohStrtDay_T_Rq 7 "Sunday" 6 "Saturday" 5 "Friday" 4 "Thursday" 3 "Wednesday" 2 "Tuesday" 1 "Monday" 0 "NotUsed" ;
VAL_TABLE_ DisableEnableNotUsedUnknown 3 "Unknown" 2 "NotUsed" 1 "Enable" 0 "Disable" ;
VAL_TABLE_ NoRequest_Request 1 "Request" 0 "NoRequest" ;
VAL_TABLE_ Foh_D_Stat 7 "Unused3" 6 "Unused2" 5 "Unused1" 4 "Stopping" 3 "Running" 2 "Starting" 1 "Prestart" 0 "Off" ;
VAL_TABLE_ ActiveStoragePassenger 7 "Unused3" 6 "Unused2" 5 "Unused1" 4 "StoreDipMemoryButton4" 3 "StoreDipMemoryButton3" 2 "StoreDipMemoryButton2" 1 "StoreDipMemoryButton1" 0 "Off" ;
VAL_TABLE_ DipMirror 1 "Dipped" 0 "Off" ;
VAL_TABLE_ WindowCmd 7 "Unused2" 6 "Unused1" 5 "NotDefined" 4 "Audo_Down" 3 "Manual_Down" 2 "Auto_Up" 1 "Manual_Up" 0 "Idle" ;
VAL_TABLE_ MirrorCmd 7 "Unused" 6 "Unfold" 5 "Fold" 4 "Right" 3 "Left" 2 "Down" 1 "Up" 0 "Idle" ;
VAL_TABLE_ WindowPosition 7 "Unused2" 6 "Unused1" 5 "Fully_Open" 4 "Bet60Percent_FullyOpen" 3 "Bet10Percent_60Percent" 2 "BetFully_10PercentOpen" 1 "Fully_Closed" 0 "Undefined" ;
VAL_TABLE_ OffOnNoDataUnused 3 "Unused" 2 "NoDataExists" 1 "On" 0 "Off" ;
VAL_TABLE_ FohFalt_D_Stat 15 "NotUsed4" 14 "NotUsed3" 13 "NotUsed2" 12 "NotUsed1" 11 "FuelTypeDoesNotMatchFOH" 10 "Lifecycle_ModeNotSet" 9 "AuxElectricCoolantPumpInop" 8 "TimeDelayAvoidExcessCycl" 7 "Fuel_Level_OutofRange" 6 "External_Fault" 5 "Internal_Fault" 4 "Voltage_limitation" 3 "Impact_Event" 2 "CoolantTemp_OutofRange" 1 "AmbientTemp_OutofRange" 0 "No_Disable" ;
VAL_TABLE_ FohRqRun_B_Rq 1 "SubmitRequest_toRun" 0 "DoesNotSubmitRequest_toRun" ;
VAL_TABLE_ SteWhlHeat 15 "NotUsed6" 14 "NotUsed5" 13 "NotUsed4" 12 "NotUsed3" 11 "NotUsed2" 10 "NotUsed1" 9 "Reserved_3" 8 "Reserved_2" 7 "Reserved_1" 6 "Level_3_Heating" 5 "Level_3_Heating_LS" 4 "Level_2_Heating" 3 "Level_2_Heating_LS" 2 "Level_1_Heating" 1 "Level_1_Heating_LS" 0 "Off" ;
VAL_TABLE_ OffOnUnusedFault 3 "Fault" 2 "Unused" 1 "On" 0 "Off" ;
VAL_TABLE_ NoMessage_DisplayMessage 1 "DisplayMessage" 0 "NoMessage" ;
VAL_TABLE_ EngineBrakeOff_Active 1 "Engine_Braking_Activated" 0 "Engine_Braking_Off" ;
VAL_TABLE_ Allowed_Denied 1 "Denied" 0 "Allowed" ;
VAL_TABLE_ PrkAidSns_D_Stat 15 "Zone_15" 14 "Zone_14" 13 "Zone_13" 12 "Zone_12" 11 "Zone_11" 10 "Zone_10" 9 "Zone_9" 8 "Zone_8" 7 "Zone_7" 6 "Zone_6" 5 "Zone_5" 4 "Zone_4" 3 "Zone_3" 2 "Zone_2" 1 "Zone_1" 0 "Off" ;
VAL_TABLE_ PrkAid_D_Falt 7 "NotUsed2" 6 "NotUsed1" 5 "Failure_Front_PSM_Sensors" 4 "No_Data_Exists" 3 "Failure_Rear_Sensors" 2 "Speaker_Fault" 1 "ECU_Fault" 0 "No_Fault" ;
VAL_TABLE_ ApaMde_D_Stat 7 "NotUsed" 6 "RePA" 5 "ParkIn" 4 "POA" 3 "PPA" 2 "SAPP" 1 "Off" 0 "Null" ;
VAL_TABLE_ _7F_Null 127 "Null" ;
VAL_TABLE_ SeatFnDrv_D_Rq 7 "CushionMassage" 6 "LumbarMassage" 5 "UpperBolster" 4 "LowerBolster" 3 "UpperLumbar" 2 "MiddleLumbar" 1 "LowerLumbar" 0 "Inactive" ;
VAL_TABLE_ Inactive_IncreaseDecrease 2 "Decrease" 1 "Increase" 0 "Inactive" ;
VAL_TABLE_ MemFeedback 8 "Recall_4" 7 "Recall_3" 6 "Recall_2" 5 "Recall_1" 4 "Store_4" 3 "Store_3" 2 "Store_2" 1 "Store_1" 0 "Inactive" ;
VAL_TABLE_ Null_Off_LowHigh 3 "High" 2 "Low" 1 "Off" 0 "Null" ;
VAL_TABLE_ NotUpdate_Update 1 "Updating" 0 "NotUpdating" ;
VAL_TABLE_ SeatFnDrv_D_Stat 7 "CushionMassage" 6 "LumbarMassage" 5 "UpperBolster" 4 "LowerBolster" 3 "UpperLumbar" 2 "MiddleLumbar" 1 "LowerLumbar" 0 "Null" ;
VAL_TABLE_ GearRvrse_D_Actl 7 "Fault" 6 "NotUsed_3" 5 "NotUsed_2" 4 "NotUsed_1" 3 "Active_confirmed" 2 "Active_not_confirmed" 1 "Inactive_confirmed" 0 "Inactive_not_confirmed" ;
VAL_TABLE_ SideDetect_SnStat_Invalid 3 "Invalid" 2 "System_Failure" 1 "Blocked" 0 "Clear" ;
VAL_TABLE_ SideDetect_OpStat 7 "NotUsed_3" 6 "NotUsed_2" 5 "NotUsed_1" 4 "Invalid" 3 "Disabled" 2 "On" 1 "Trailer_Tow_Off" 0 "Off" ;
VAL_TABLE_ SideDetect_Present 4 "Sensor_Blocked" 3 "Sensor_Fault" 2 "Flash_On" 1 "Alert_On" 0 "AlertOff_FlashOff_SensrClr" ;
VAL_TABLE_ Off_On_Flash_BulbProveout 3 "Bulb_Proveout" 2 "Flash" 1 "On" 0 "Off" ;
VAL_TABLE_ SideDetect_BLIS_Off_On 2 "BLIS_On_Second_Warning_ON" 1 "BLIS_On_Second_Warning_OFF" 0 "Off" ;
VAL_TABLE_ SideDetect_report 3 "Reporting" 2 "Not_Reporting" 1 "System_Standby" 0 "Initialization" ;
VAL_TABLE_ DrTGate_D_Rq 3 "NotUsed" 2 "Closing" 1 "Opening" 0 "Not_Moving" ;
VAL_TABLE_ WndwSide_D_Stat 3 "BothWindow_Operating" 2 "RearWindow_Operating" 1 "FrontWindow_Operating" 0 "NoWindows_Operating" ;
VAL_TABLE_ False_True 1 "True" 0 "False" ;
VAL_TABLE_ Null_Up_Down 3 "Unused" 2 "Down" 1 "Up" 0 "Null" ;
VAL_TABLE_ Null_Fwd_Rwd 3 "Unused" 2 "Rearward" 1 "Forward" 0 "Null" ;
VAL_TABLE_ Null_Ack_Nack_NotUsed 3 "Not_Used" 2 "Nack" 1 "Ack" 0 "Null" ;
VAL_TABLE_ HvacBlwrFront_D_Stat 31 "Not_Used" 20 "Full_On" 19 "95_Percent" 18 "90_Percent" 17 "85_Percent" 16 "80_Percent" 15 "75_Percent" 14 "70_Percent" 13 "65_Percent" 12 "60_Percent" 11 "55_Percent" 10 "50_Percent" 9 "45_Percent" 8 "40_Percent" 7 "35_Percent" 6 "30_Percent" 5 "25_Percent" 4 "20_Percent" 3 "15_Percent" 2 "10_Percent" 1 "5_Percent" 0 "Off" ;
VAL_TABLE_ ACU_ARAudioSource_Rsp 15 "iPod" 14 "USB" 13 "BTAudio" 0 "AmfmRadio" 1 "FrontDisc" 2 "SDARS_DAB" 3 "InDashCdChanger" 4 "VoiceRecogniser" 5 "TelematicUnit" 6 "BluetoothPhone" 7 "RearDisc" 8 "APIM" 9 "FrontAuxInput" 10 "Navigation" 11 "RearAux" 12 "NotReq" ;
VAL_TABLE_ ACU_AROperationType_Rsp 0 "Inactive" 1 "Requestaudioresource" 2 "Releaseaudioresource" 3 "Releaseallaudioresouces" 4 "Getresourceupdate" 5 "Getallresourceupdates" ;
VAL_TABLE_ ACU_ARResponse_Rsp 0 "Inactive" 1 "RequestAccepted" 2 "RequestAcceptedWoCtrl" 3 "RequestDenied" 4 "RessourceUpdateStatus" ;
VAL_TABLE_ ACU_ARReqstrPriority_Rp 0 "EmergencyServ" 1 "TelService" 2 "AutoAnswer" 3 "Ta" 4 "PttMutevoice" 5 "NavUserVoiceCmd" 6 "NavSysVoiceCmd" 7 "Radio" 8 "Disc" 9 "Alarm" 10 "Ptynews" 11 "Aux_ExtSource" 12 "MobileNavAndTelMute" 13 "ManualAudioMute" 14 "NotReq" ;
VAL_TABLE_ ACU_RUAudioSource_St 15 "iPod" 14 "USB" 13 "BTAudio" 0 "AmfmRadio" 1 "FrontDisc" 2 "SDARS_DAB" 3 "InDashCdChanger" 4 "VoiceRecogniser" 5 "TelematicUnit" 6 "BluetoothPhone" 7 "RearDisc" 8 "APIM" 9 "FrontAuxInput" 10 "Navigation" 11 "RearAux" 12 "NotReq" ;
VAL_TABLE_ FrontRequest_RearRequest 0 "FrontRequester" 1 "RearRequester" ;
VAL_TABLE_ ACU_RUResReqstStatus_St 0 "NoResourceupdate" 1 "Deallocated" 2 "Allocated" 3 "Stacked" 4 "Granted" 5 "GrantedNoControlOfAudioSrc" ;
VAL_TABLE_ ACU_RUReqstrPriority_St 0 "EmergencyServ" 1 "TelService" 2 "AutoAnswer" 3 "Ta" 4 "PttMutevoice" 5 "NavUserVoiceCmd" 6 "NavSysVoiceCmd" 7 "Radio" 8 "Disc" 9 "Alarm" 10 "Ptynews" 11 "Aux_ExtSource" 12 "MobileNavAndTelMute" 13 "ManualAudioMute" 14 "NotReq" ;
VAL_TABLE_ EFP_Bezel_Diag_St 15 "Reserved" 3 "CalibrationPartNumber" 2 "HardwarePartNumber" 1 "SoftwarePartNumber" 0 "Inactive_NOP" ;
VAL_TABLE_ Invalid_SupportedNotSup 2 "Not_Supported" 1 "Supported" 0 "Invalid" ;
VAL_TABLE_ NoData_Faulty_7E_7F 127 "Faulty" 126 "NoDataExists" ;
VAL_TABLE_ Invalid_EnabledDisabled2 0 "Invalid" 2 "Disabled" 1 "Enabled" ;
VAL_TABLE_ Diagnostic_Operation_Rq 7 "SignalStrength" 6 "SDARSESNNumber" 5 "SpeakerWalkAround" 4 "CalibrationPartNumber" 15 "Reserved" 3 "HardwarePartNumber" 2 "SoftwarePartNumber" 1 "GetAllBackgroundDiagRq" 0 "Inactive" ;
VAL_TABLE_ Bezel_Diag_Module_Rq 15 "Reserved" 3 "EFP" 2 "DSP_AMP" 1 "AHU" 0 "Inactive" ;
VAL_TABLE_ HMI_HMIMode_St 7 "NotUsed2" 6 "NotUsed1" 5 "Load_Shed_Active" 0 "Invalid" 1 "OffMode" 2 "On" 3 "Phone" 4 "Climate" ;
VAL_TABLE_ PrmtrAlrmEvnt_D_Stat 15 "Diag_Tamper" 14 "Trailer" 13 "Shock_Sensor" 12 "Post_Crash" 11 "Panic" 10 "Intrusion" 9 "Inclination" 8 "Ign_Tamper" 7 "LG_Door" 6 "Decklid" 5 "Hood" 4 "PR_Door" 3 "PF_Door" 2 "DR_Door" 1 "DF_Door" 0 "Null" ;
VAL_TABLE_ PtcHtr_D_Cmd 3 "TurnOn" 2 "AutoMode" 1 "TurnOff" 0 "NoDecision_Initializing" ;
VAL_TABLE_ NoData_Fault_FFFE_FFFF 65535 "Fault" 65534 "NoDataExists" ;
VAL_TABLE_ TrlrBattChrg_D_Stat 3 "Reverse" 2 "Normal" 1 "Low" 0 "Null" ;
VAL_TABLE_ TrlrLampCtl_D_Stat 3 "NotUsed" 2 "TrlrLampCnnctDrvFailure" 1 "TrlrLampNotCnnctDrvFailure" 0 "Null" ;
VAL_TABLE_ ElPw_D_StatStrtStop 15 "NotUsed6" 14 "NotUsed5" 13 "NotUsed4" 12 "NotUsed3" 11 "NotUsed2" 10 "NotUsed1" 9 "Supported_Level_4" 8 "Supported_Level_3" 7 "Supported_Level_2" 6 "Supported_Level_1" 5 "Limited_Support" 4 "Fault_Limited" 3 "LV_Event_in_Progress" 2 "Not_Supported_Imminent" 1 "Supported_All" 0 "Not_Supported" ;
VAL_TABLE_ ImpactEvntFdbck_D_Stat 3 "NotUsed" 2 "EventComplete" 1 "EventInProgress" 0 "Normal" ;
VAL_TABLE_ NoData_Fault_3E_3F 63 "Fault" 62 "NoDataExists" ;
VAL_TABLE_ Null_Open 1 "Open" 0 "Null" ;
VAL_TABLE_ TempDegreesC_DegreesF 0 "Temperature_deg_c" 1 "Temperature_deg_f" ;
VAL_TABLE_ Temp_Detents 15 "Unused5" 14 "Unused4" 13 "Unused3" 12 "Unused2" 11 "Unused1" 10 "Display_Blank" 9 "_4_Heat_Bars" 8 "_3_Heat_Bars" 7 "_2_Heat_Bars" 6 "_1_Heat_Bar" 5 "Neutral_Bar_Only" 4 "_1_Cool_Bar" 3 "_2_Cool_Bars" 2 "_3_Cool_Bars" 1 "_4_Cool_Bars" 0 "No_Bars" ;
VAL_TABLE_ Set_Temp_Dig3 2 "_5" 1 "_0" 0 "Off" ;
VAL_TABLE_ Btn_Status 31 "NotUsed_7" 30 "NotUsed_6" 29 "NotUsed_5" 28 "NotUsed_4" 27 "NotUsed_3" 26 "NotUsed_2" 25 "NotUsed_1" 24 "Third_Sync_Pressed" 23 "Third_Rr_Pwr_Pressed" 22 "Third_Auto_Pressed" 21 "Third_Pnl_Flr_Pressed" 20 "Third_Floor_Pressed" 19 "Third_Panel_Pressed" 18 "Third_Blwr_Dec_Pressed" 17 "Third_Blwr_Inc_Pressed" 16 "Rear_Lock_Pressed" 15 "RHS_Cld_Seat_Pressed" 14 "LHS_Cld_Seat_Pressed" 13 "RHS_Htd_Seat_Pressed" 12 "LHS_Htd_Seat_Pressed" 11 "Rear_Power_Pressed" 10 "AUTO_Pressed" 9 "Blwr_Dec_Pressed" 8 "Blwr_Inc_Pressed" 7 "RHS_Temp_Dec_Pressed" 6 "RHS_Temp_Inc_Pressed" 5 "LHS_Temp_Dec_Pressed" 4 "LHS_Temp_Inc_Pressed" 3 "Floor_Pressed" 2 "Panel_Floor_Pressed" 1 "Panel_Pressed" 0 "None_Pressed" ;
VAL_TABLE_ Cond_Seat_Status 7 "Unused" 6 "Level_3_Heating" 5 "Level_2_Heating" 4 "Level_1_Heating" 3 "Level_3_Cooling" 2 "Level_2_Cooling" 1 "Level_1_Cooling" 0 "Off" ;
VAL_TABLE_ Htd_Strg_Whl_Status 3 "Level_3_Heating" 2 "Level_2_Heating" 1 "Level_1_Heating" 0 "Off" ;
VAL_TABLE_ Frt_Blower_Speed 3 "NotUsed" 2 "Max_Blower" 1 "Min_Blower" 0 "No_Request" ;
VAL_TABLE_ Blower_Indicate 15 "Display_Blank" 14 "14_Indicators_On" 13 "13_Indicators_On" 12 "12_Indicators_On" 11 "11_Indicators_On" 10 "10_Indicators_On" 9 "9_Indicators_On" 8 "8_Indicators_On" 7 "7_Indicators_On" 6 "6_Indicators_On" 5 "5_Indicators_On" 4 "4_Indicators_On" 3 "3_Indicators_On" 2 "2_Indicators_On" 1 "1_Indicator_On" 0 "Indicators_Off" ;
VAL_TABLE_ Front_AUTO_Label 3 "Full" 2 "Mode" 1 "Blower" 0 "Off" ;
VAL_TABLE_ Drv_Set_Temp 31 "HI" 30 "29_5" 29 "29_0" 28 "28_5" 27 "28_0" 26 "27_5" 25 "27_0" 24 "26_5" 23 "26_0" 22 "25_5" 21 "25_0" 20 "24_5" 19 "24_0" 18 "23_5" 17 "23_0" 16 "22_5" 15 "22_0" 14 "21_5" 13 "21_0" 12 "20_5" 11 "20_0" 10 "19_5" 9 "19_0" 8 "18_5" 7 "18_0" 6 "17_5" 5 "17_0" 4 "16_5" 3 "16_0" 2 "15_5" 1 "LO" 0 "No_Request" ;
VAL_TABLE_ CC_Fr_Stat_User_Adj 7 "Unused4" 6 "RHS_AUTO_St_Selection" 5 "LHS_AUTO_St_Selection" 4 "DrvrFcsdMde_Selection" 3 "Fr_Blwr_Spd_Selection" 2 "FRHS_SetPt_Selection" 1 "FLHS_SetPt_Selection" 0 "None" ;
VAL_TABLE_ CC_Rr_Stat_User_Adj 15 "Unused9" 14 "Unused8" 13 "Unused7" 12 "Unused6" 11 "Unused5" 10 "Unused4" 9 "Unused3" 8 "Unused2" 7 "Unused1" 6 "Rr_Auto_Selection" 5 "Rr_Control_Selection" 4 "Rr_Power_Selection" 3 "Rr_Blwr_Spd_Selection" 2 "RRHS_SetPt_Selection" 1 "RLHS_SetPt_Selection" 0 "None" ;
VAL_TABLE_ CC_Fr_Btn_User_Adj 31 "Unused15" 30 "Unused14" 29 "Unused13" 28 "Unused12" 27 "Unused11" 26 "Unused10" 25 "Unused9" 24 "Unused8" 23 "Unused7" 22 "Unused6" 21 "RHS_Cld_St_Selection" 20 "LHS_Cld_St_Selection" 19 "UFC_Interrupted" 18 "UFC_Complete" 17 "UFC_Active" 16 "Htd_WS_Selection" 15 "RHS_Htd_St_Selection" 14 "LHS_Htd_St_Selection" 13 "HSW_Selection" 12 "Dual_Selection" 11 "Rear_Defrost_Selection" 10 "Max_Defrost_Selection" 9 "Defrost_Selection" 8 "Fr_Air_Dist_Selection" 7 "Max_AC_Selection" 6 "Fr_Power_Selection" 5 "Recirc_Selection" 4 "AC_Selection" 3 "Fr_Auto_Selection" 2 "Use_MyTemp_Selection" 1 "Save_MyTemp_Selection" 0 "None" ;
VAL_TABLE_ HeadLghtHiFdbck_D_Stat 3 "NotUsed" 2 "Cancel" 1 "Hold" 0 "Allow_Change" ;
VAL_TABLE_ Backlit_LED_Status 15 "Unused3" 14 "Unused2" 13 "Unused1" 12 "Night_12" 11 "Night_11" 10 "Night_10" 9 "Night_9" 8 "Night_8" 7 "Night_7" 6 "Night_6" 5 "Night_5" 4 "Night_4" 3 "Night_3" 2 "Night_2" 1 "Night_1" 0 "Off" ;
VAL_TABLE_ Veh_Lock_Status 3 "UNLOCK_DRV" 2 "UNLOCK_ALL" 1 "LOCK_ALL" 0 "LOCK_DBL" ;
VAL_TABLE_ CrashEvnt_D_Stat 3 "Invalid" 2 "Fuel_Cutoff_Event" 1 "Deploy_Event" 0 "No_Event" ;
VAL_TABLE_ ReducedGuard_D_Stat 3 "NotUsed" 2 "Alarm_On" 1 "Alarm_Off_Previously_On" 0 "Alarm_Off" ;
VAL_TABLE_ HvacPrecondBlwr_D_Rq 15 "NotUsed6" 14 "NotUsed5" 13 "NotUsed4" 12 "NotUsed3" 11 "NotUsed2" 10 "NotUsed1" 9 "Last_User_Setting" 8 "Auto" 7 "Speed7" 6 "Speed6" 5 "Speed5" 4 "Speed4" 3 "Speed3" 2 "Speed2" 1 "Speed1" 0 "Off" ;
VAL_TABLE_ HvacPrecondMode_D_Rq 15 "NotUsed4" 14 "NotUsed3" 13 "NotUsed2" 12 "NotUsed1" 11 "Last_User_Settings" 10 "Auto" 9 "Max_Defrost" 8 "Windshield_Panel_Floor" 7 "Windshield_Panel" 6 "Windshield" 5 "Windshield_Floor" 4 "Floor" 3 "Panel_Floor" 2 "Panel" 1 "MAX_AC" 0 "Off" ;
VAL_TABLE_ Null_Pressed 1 "Pressed" 0 "Null" ;
VAL_TABLE_ FobComm_D_Stat 3 "NotUsed" 2 "RemEngStartOK" 1 "RemEngStartFail" 0 "Null" ;
VAL_TABLE_ PudLamp_D_Rq 3 "RAMP_DOWN" 2 "RAMP_UP" 1 "ON" 0 "OFF" ;
VAL_TABLE_ WndwGlbl_D_Cmd 7 "NotUsed3" 6 "NotUsed2" 5 "NotUsed1" 4 "GLEARN" 3 "GCLOSE" 2 "GOPEN" 1 "GSTOP" 0 "Null" ;
VAL_TABLE_ LockMsg 7 "MSG7" 6 "MSG6" 5 "MSG5" 4 "MSG4" 3 "MSG3" 2 "MSG2" 1 "MSG1" 0 "NO_WARNING" ;
VAL_TABLE_ ChildLockDisplay 3 "NOT_SUPPORTED" 2 "ERROR" 1 "CHILD_UNLOCK" 0 "CHILD_LOCK" ;
VAL_TABLE_ Null_Lock_Unlock 3 "NotUsed" 2 "Unlock" 1 "Lock" 0 "Null" ;
VAL_TABLE_ NotDown_Down 1 "Down" 0 "Not_Down" ;
VAL_TABLE_ NotUp_Up 1 "Up" 0 "Not_Up" ;
VAL_TABLE_ Wiper 15 "NO_DATA_EXISTS" 14 "STALLED" 13 "RESERVED" 12 "AUTO_ADJUST" 11 "COURTESYWIPE" 10 "AUTO_HIGH" 9 "AUTO_LOW" 8 "WASH" 7 "MIST_FLICK" 6 "MAN_HIGH" 5 "MAN_LOW" 4 "MAN_INT_ON" 3 "MAN_INT_OFF" 2 "OFF_MOVING" 1 "AUTO_OFF" 0 "OFF" ;
VAL_TABLE_ Turn_switch 3 "Unused_Treat_As_Off" 2 "Right" 1 "Left" 0 "Off" ;
VAL_TABLE_ PrkLght_D_Stat 3 "Park_Both" 2 "Park_Right" 1 "Park_Left" 0 "Off" ;
VAL_TABLE_ HeadLghtSwtch_D_Stat 3 "Autolamp" 2 "Headlamp" 1 "Parklamp" 0 "Off" ;
VAL_TABLE_ LifeCycMde_D_Actl 3 "Transport" 2 "NotUsed" 1 "Factory" 0 "Normal" ;
VAL_TABLE_ ClimtHeat_D_Rq 7 "NotUsed4" 6 "NotUsed3" 5 "HtrCoreClntFlwOnly" 4 "PtcHtrTestMde" 3 "Defrost_Defog" 2 "FastTempPullDownHeatingReq" 1 "OpportunisticHeatingReq" 0 "NoHeatingRequest" ;
VAL_TABLE_ NoData_Fault_3FE_3FF 1023 "Fault" 1022 "NoDataExists" ;
VAL_TABLE_ ClimtCool_D_Rq 7 "NotUsed4" 6 "NotUsed3" 5 "NotUsed2" 4 "ElACTestMde" 3 "Defrost_Defog" 2 "FastTempPullDownCoolReq" 1 "OpportunisticCoolingReq" 0 "NoCoolingRequest" ;
VAL_TABLE_ HvacRec_D_RqMxBatt 15 "NotUsed5" 14 "NotUsed4" 13 "NotUsed3" 12 "NotUsed2" 11 "NotUsed1" 10 "No_Override" 9 "90Percent_RecircMax" 8 "80Percent_RecircMax" 7 "70Percent_RecircMax" 6 "60Percent_RecircMax" 5 "50Percent_RecircMax" 4 "40Percent_RecircMax" 3 "30Percent_RecircMax" 2 "20Percent_RecircMax" 1 "10Percent_RecircMax" 0 "0Percent_RecircFullOpen" ;
VAL_TABLE_ PrkBrkStatus 7 "GeneralFault_MaintenceMode" 6 "ECD_by_Brake_ECU_Active" 5 "EPB_Limphome_Active" 4 "Rear_Caliper_Open" 3 "RWU_By_EPB_Active" 2 "Rear_Caliper_Transition" 1 "Rear_Caliper_Closed" 0 "Not_Supported" ;
VAL_TABLE_ Quality_Data 3 "OK" 2 "Not_Within_Specifications" 1 "Eval_In_Progress" 0 "Fault" ;
VAL_TABLE_ PwSrcULoFalt_D_Stat 3 "Fault_No_Output" 2 "Fault_Reduced_Output" 1 "Fault_NonSpecific" 0 "No_Fault" ;
VAL_TABLE_ Eng_D_Stat 3 "NotUsed" 2 "EngAutoStopped" 1 "EngOn" 0 "EngOff" ;
VAL_TABLE_ ElPw_D_Stat 7 "NotUsed_3" 6 "NotUsed_2" 5 "NotUsed_1" 4 "Fault_Limited" 3 "LV_Event_In_Progress" 2 "Not_Supported_Imminent" 1 "Supported" 0 "Not_Supported" ;
VAL_TABLE_ PwPckTq_D_Stat 3 "PwPckOn_TqAvailable" 2 "StartInPrgrss_TqNotAvail" 1 "PwPckOn_TqNotAvailable" 0 "PwPckOff_TqNotAvailable" ;
VAL_TABLE_ Fault_FF 255 "Fault" ;
VAL_TABLE_ ElCmprOverTe_D_Stat 3 "OverTempStop" 2 "OverTempWarning" 1 "Normal" 0 "Undefined" ;
VAL_TABLE_ ElCmpr_D_Stat 7 "Signal_Invalid" 6 "Comp_Off_ActlSpd_Abnormal" 5 "Comp_Off_TrgtSpd_OutRange" 4 "Comp_Shutdown" 3 "Comp_Stopped_Self_Protect" 2 "Comp_Degraded" 1 "Comp_On" 0 "Comp_Off" ;
VAL_TABLE_ Southern_Northern 3 "Fault" 2 "Northern" 1 "Southern" 0 "Invalid" ;
VAL_TABLE_ PsngrFrntDetct_D_Actl 3 "Unknown" 2 "Empty" 0 "Faulty" 1 "Occupied" ;
VAL_TABLE_ Fault_3FF 1023 "Fault" ;
VAL_TABLE_ Fault_F 15 "Fault" ;
VAL_TABLE_ Fault_1F 31 "Fault" ;
VAL_TABLE_ LockInhibit 1 "Inhibit" 0 "No_Inhibit" ;
VAL_TABLE_ Temp_Units 2 "Fahrenheit" 1 "Celsius" 0 "Off" ;
VAL_TABLE_ Shed_Feature_Group_ID 16 "PtcHeater" 30 "NotUsed_7" 29 "NotUsed_6" 28 "NotUsed_5" 27 "NotUsed_4" 26 "NotUsed_3" 25 "NotUsed_2" 24 "NotUsed_1" 23 "Dcac" 22 "UpFitter_6" 21 "UpFitter_5" 20 "UpFitter_4" 19 "UpFitter_3" 18 "UpFitter_2" 17 "UpFitter_1" 14 "HtdMirr" 13 "HvacRearBlwr_Third" 12 "HvacRearBlwr_Second" 11 "HvacRearBlwr_First" 31 "All LSHED1 Features" 10 "Htd_Windscrn" 9 "SpltHtdBcklight_HtdMirr" 8 "HtdBcklight_HtdMirr" 7 "HtdCoolSeat_FrtDriver" 6 "HtdCoolSeat_FrtPass" 5 "HtdCoolSeat_RearPass" 4 "HtdCoolSeat_RearDriver" 3 "SmartTrlrTowBattCharge" 2 "Htd_StrWhl" 1 "Htd_Washer_Fluid" 0 "No_LSHED1_Features" 15 "Engine_Coolant_Fan" ;
VAL_TABLE_ CoolantFanStepAct 31 "Unused7" 30 "Unused6" 29 "Unused5" 28 "Unused4" 27 "Unused3" 26 "Unused2" 25 "Unused1" 23 "Step23" 22 "Step22" 21 "Step21" 20 "Step20" 19 "Step19" 18 "Step18" 17 "Step17" 16 "Step16" 15 "Step15" 14 "Step14" 13 "Step13" 12 "Step12" 11 "Step11" 10 "Step10" 9 "Step9" 8 "Step8" 7 "Step7" 6 "Step6" 5 "Step5" 4 "Step4" 3 "Step3" 2 "Step2" 1 "Step1" 24 "Max_Fan_Speed_Req" 0 "Fan_Cmd_Off" ;
VAL_TABLE_ Null_Cancel 1 "Cancel" 0 "Null" ;
VAL_TABLE_ Null_Drive_EasyEntry 2 "Easy_Entry" 1 "Drive" 0 "Null" ;
VAL_TABLE_ Veh_Lock_Requestor 31 "Walk_Away_Locking" 30 "Remote_Park_Assist" 29 "DoorsOffToOn_Smart_Unlock" 28 "Rgtm_Shutlock_Switch" 27 "Boundary_Alert" 26 "Transit_Vehicle_Relock" 25 "Transit_Cargo_Relock" 24 "Transit_Ajar_Lock" 23 "Diagnostics" 22 "Console_Lock" 21 "Child_Lock" 20 "Double_Lock" 19 "Passive_Pasenger" 18 "Passive_Driver" 17 "Slam_Lock_Protect" 16 "SYNC" 15 "Passport" 14 "Passive_Smart_Unlock" 13 "Autorelock" 12 "RemoteStart" 0 "Null" 1 "Autolock" 11 "Smart_Unlock" 10 "Sliding_Door" 9 "Passive" 8 "Remote" 7 "Programming" 6 "Powerslide" 5 "Keypad" 4 "Key_Cylinder" 3 "Interior" 2 "Auto_Unlock" ;
VAL_TABLE_ Perimeter_Alarm_Mode 3 "Activated" 2 "Armed" 1 "Prearmed" 0 "Disarmed" ;
VAL_TABLE_ Invalid_FFFF 65535 "Invalid" ;
VAL_TABLE_ GearEngag_D_Actl 7 "Undefined" 6 "Fwd_Clutch_Fully_Engaged" 5 "Neutral_Idle" 4 "Disengaged_to_Neutral_Idle" 3 "Disengaged_to_Neutral_Park" 2 "Engagement_in_Progress" 1 "InitializeFwdClutchEngagmt" 0 "Park_Neutral" ;
VAL_TABLE_ Shed_Level_Req 7 "SHED3" 6 "Loads_On" 5 "SHED_ENG_OFF" 4 "SOON_ENG_OFF" 3 "SHED2_CONTIN" 2 "SHED2_TRANS" 1 "SHED1" 0 "NO_SHED" ;
VAL_TABLE_ Eastern_Western 0 "Invalid" 1 "Eastern" 2 "Western" 3 "Fault" ;
VAL_TABLE_ EATC_Temp_Digit3 2 "_5" 1 "_0" 0 "OFF" ;
VAL_TABLE_ EATC_Units 2 "Fahrenheit" 1 "Celsius" 0 "Off" ;
VAL_TABLE_ RKE_Filter_Ctrl 3 "Streaming" 2 "Filter" 1 "Not_Used" 0 "Null" ;
VAL_TABLE_ RstrnImpactEvntStatus 7 "Invalid" 6 "Not_Used_4" 5 "Threshold_2_Exceeded" 4 "Not_Used_3" 3 "Threshold_1_Exceeded" 2 "Not_Used_2" 1 "Not_Used_1" 0 "Normal" ;
VAL_TABLE_ Closed_Ajar 1 "Ajar" 0 "Closed" ;
VAL_TABLE_ Quality_Factor 3 "OK" 2 "Not_Within_Specifications" 1 "No_Data_Exists" 0 "Faulty" ;
VAL_TABLE_ Null_Day_Night 3 "NotUsed" 2 "Night" 1 "Day" 0 "Null" ;
VAL_TABLE_ GearPos_D_Actl 15 "Unknown" 14 "Reverse" 13 "Undefined_5" 12 "Undefined_4" 11 "Undefined_3" 10 "Tenth" 9 "Ninth" 8 "Eighth" 7 "Seventh" 6 "Sixth" 5 "Fifth" 4 "Fourth" 3 "Third" 2 "Second" 1 "First" 0 "Neutral" ;
VAL_TABLE_ WhlDir 3 "Faulty" 2 "NoDataExists" 1 "Backward" 0 "Forward" ;
VAL_TABLE_ Unknown_Fault_1FE_1FF 511 "Fault" 510 "Unknown" ;
VAL_TABLE_ Fault_NoFault 1 "Fault" 0 "No_Fault" ;
VAL_TABLE_ Unknown_Fault_FFFE_FFFF 65535 "Fault" 65534 "Unknown" ;
VAL_TABLE_ Invalid_FFFFFF 16777215 "Invalid" ;
VAL_TABLE_ GearLvrPos_D_Actl 15 "Fault" 14 "Unknown_Position" 13 "Undefined_Treat_as__Fault" 12 "Undefined_Treat_as_Fault" 11 "sixth" 10 "fifth" 9 "fourth" 8 "third" 7 "second" 6 "first" 5 "Low" 4 "Sport_DriveSport" 3 "Drive" 2 "Neutral" 1 "Reverse" 0 "Park" ;
VAL_TABLE_ CcStat_D_Actl 7 "Undefined_2" 6 "Undefined_1" 5 "Active" 4 "Active_Que_Assist" 3 "Standby" 2 "Standby_Denied" 1 "Denied" 0 "Off" ;
VAL_TABLE_ AslIconDsply_D_Rq 3 "On_Passive_Overridden" 2 "On_Active" 1 "On_Passive" 0 "Off" ;
VAL_TABLE_ Unknown_Fault_3E_3F 63 "Fault" 62 "Unknown" ;
VAL_TABLE_ NotPressed_Pressed 1 "Pressed" 0 "Not_Pressed" ;
VAL_TABLE_ NotQuiet_Quiet 1 "Quiet" 0 "Not_Quiet" ;
VAL_TABLE_ Remote_Device_Feedback 7 "Unused3" 6 "Unused2" 5 "Unused1" 4 "Shutdown" 3 "Running" 2 "Starting" 1 "Acknowledge" 0 "Null" ;
VAL_TABLE_ Remote_Start_Req 3 "Not_Used" 2 "Remote_Cancel" 1 "Remote_Start" 0 "No_Request" ;
VAL_TABLE_ Modulation_Ctrl 3 "Unused" 2 "FSK" 1 "ASK_FSK" 0 "ASK" ;
VAL_TABLE_ Unlock_Lock 1 "Locked" 0 "Unlock" ;
VAL_TABLE_ Unknown_Fault_FFE_FFF 4095 "Fault" 4094 "Unknown" ;
VAL_TABLE_ InhibitNoinhibit 1 "Inhibit" 0 "No_Inibit" ;
VAL_TABLE_ DisableEnable 1 "Enable" 0 "Disable" ;
VAL_TABLE_ Side_Detect_Sn_State 3 "Second_Warning_Audio" 2 "System_Failure" 1 "Blocked" 0 "Clear" ;
VAL_TABLE_ Litval_values 255 "Invalid" 254 "Unknown" 5 "Day" 4 "Twilight_4" 3 "Twilight_3" 2 "Twilight_2" 1 "Twilight_1" 0 "Night" ;
VAL_TABLE_ Dimming_Lvl 255 "Invalid" 254 "Unknown" 18 "Day_6" 17 "Day_5" 16 "Day_4" 15 "Day_3" 14 "Day_2" 13 "Day_1" 12 "Night_12" 11 "Night_11" 10 "Night_10" 9 "Night_9" 8 "Night_8" 7 "Night_7" 6 "Night_6" 5 "Night_5" 4 "Night_4" 3 "Night_3" 2 "Night_2" 1 "Night_1" 0 "Off" ;
VAL_TABLE_ Remote_Start_Status 3 "Invalid" 2 "Unknown" 1 "Remote" 0 "Null" ;
VAL_TABLE_ Enabled_Active_Disabled 3 "Unused" 2 "Disabled" 1 "Active" 0 "Enabled_Inactive" ;
VAL_TABLE_ Lock_Subld 15 "Unused7" 14 "Unused6" 13 "Unused5" 12 "Unused4" 11 "Unused3" 10 "Unused2" 9 "Unused1" 8 "Customer_8" 7 "Customer_7" 6 "Customer_6" 5 "Customer_5" 4 "Customer_4" 3 "Customer_3" 2 "Customer_2" 1 "Customer_1" 0 "Null" ;
VAL_TABLE_ Brake_Fluid 3 "Invalid" 2 "Unknown" 1 "Low" 0 "OK" ;
VAL_TABLE_ Unknown_Invalid_FE_FF 255 "Invalid" 254 "Unknown" ;
VAL_TABLE_ Invalid_FF 255 "Invalid" ;
VAL_TABLE_ NotLow_Low 1 "Low" 0 "Not_Low" ;
VAL_TABLE_ Key_In_Ignition_Status 1 "In" 0 "Out" ;
VAL_TABLE_ Ignition_Status 0 "Unknown" 1 "Off" 15 "Invalid" 8 "Start" 4 "Run" 2 "Accessory" ;
VAL_TABLE_ Disabled_Enabled_NoSupport 2 "Unused" 3 "Not_Supported" 1 "Enabled" 0 "Disabled" ;
VAL_TABLE_ Unknown_Fault_FE_FF 255 "Fault" 254 "Unknown" ;
VAL_TABLE_ Null_Unlock 1 "Unlock" 0 "Null" ;
VAL_TABLE_ Null_Active 1 "Active" 0 "Null" ;
VAL_TABLE_ MemoryCmd 7 "Recall_3" 4 "Store_4" 3 "Store_3" 6 "Recall_2" 5 "Recall_1" 2 "Store_2" 1 "Store_1" 0 "Null" 8 "Recall_4" ;
VAL_TABLE_ PassRstrnInd_Stat 7 "Invalid" 6 "Unused_2" 5 "Unused_1" 4 "Both_Indicators_Faulted" 3 "AirbagOff_Indicator_fault" 2 "AirbagOn_Indicator_fault" 1 "Normal" 0 "Not_Supported" ;
VAL_TABLE_ PassRstrnInd_Req 3 "ABOnNotIllum_OffNotIllum" 2 "AirbagOnNot_Illum_OffIllum" 1 "AirbagOn_Illum_OffNotIllum" 0 "AirbagOn_Illum_Off_Illum" ;
VAL_TABLE_ GPS_dimension 2 "_3D" 1 "_2D" 0 "No_Fix" ;
VAL_TABLE_ GPS_Compass_dirctn 7 "NorthWest" 6 "West" 5 "SouthWest" 4 "South" 3 "SouthEast" 2 "East" 1 "NorthEast" 0 "North" ;
VAL_TABLE_ GPS_Actual_Infer 1 "Inferred_Position" 0 "Actual_Postition" ;
VAL_TABLE_ Off_On 1 "On" 0 "Off" ;
VAL_TABLE_ InactiveActive 1 "Active" 0 "Inactive" ;
VAL_TABLE_ Fault_7F 127 "Fault" ;
VAL_TABLE_ Unknown_Invalid_1E_1F 31 "Invalid" 30 "Unknown" ;
VAL_TABLE_ Unknown_Invalid_3FFE_3FFF 16383 "Invalid" 16382 "Unknown" ;
VAL_TABLE_ NoYes 1 "Yes" 0 "No" ;
VAL_TABLE_ Unknown_Fault_3FE_3FF 1023 "Fault" 1022 "Unknown" ;
VAL_TABLE_ LockSwStat 3 "Invalid" 2 "Unlock" 1 "Lock" 0 "Null" ;
VAL_TABLE_ Null_Override 1 "Override" 0 "Null" ;
VAL_TABLE_ Off_On_Flash 3 "Not_Used" 2 "Flash" 1 "On" 0 "Off" ;
VAL_TABLE_ Update_Bit 1 "Fresh_data" 0 "Unchanged_data" ;
VAL_TABLE_ Tire_Pressure_Stat 4 "Alert" 15 "Not_Supported" 3 "Fault" 2 "Low" 1 "Normal" 0 "Unknown" ;
VAL_TABLE_ Tire_Pressure_System2 13 "Training_Complete" 12 "Train_InsideLeftRear_tire" 11 "Train_OutsideLeftRear_tire" 10 "Train_LeftRear_tire" 9 "Train_InsideRtRear_tire" 8 "Train_OutsideRtRear_tire" 7 "Train_RightRear_tire" 14 "Tires_not_trained" 6 "Train_RightFront_tire" 5 "Train_LeftFront_tire" 4 "Systm_Activ_Composite_Stat" 3 "Low_Composite_Stat" 2 "Sensr_Fault_Composite_Stat" 1 "Systm_Fault_Composite_Stat" 0 "Unknown_Composite_Stat" ;
VAL_TABLE_ Running_Board 3 "Unused" 2 "Manually_Deployed" 1 "All_Enabled" 0 "All_Disabled" ;
VAL_TABLE_ Clmt_Ctrl_Seat_Setting 128 "H3_High_Heat__MAX" 64 "H2_Medium_Heat" 32 "H1_Low_Heat" 16 "C3_High_Cool__MAX" 8 "C2_Medium_Cool" 4 "C1_Low_Cool" 2 "Off" ;
VAL_TABLE_ Turn_Seq 3 "Seq" 2 "On" 1 "Off" 0 "Null" ;
VAL_TABLE_ NotPark 1 "Park" 0 "Not_Park" ;
VAL_TABLE_ PersOptIn 1 "OPTED_IN" 0 "NOT_OPTED_IN" ;
VAL_TABLE_ PersonalSetUp 3 "Non_Moveable_Person" 2 "Moveable_Person" 1 "Vehicle" 0 "Factory" ;
VAL_TABLE_ Full_Limited 1 "Limited" 0 "Full" ;
VAL_TABLE_ NoConflict_Conflict 1 "Conflict" 0 "No_Conflict" ;
VAL_TABLE_ Assoc_Confirm 0 "None" 7 "Associate" 6 "Keycode_Rejected" 5 "Keycode_Accepted" 4 "In_Progress" 3 "Erase" 2 "Duplicate" 1 "Disassociate" ;
VAL_TABLE_ Complete_Inprogress 3 "Unused" 2 "Null" 1 "InProgress" 0 "Complete" ;
VAL_TABLE_ Null_Pers1_4 7 "Unused_3" 6 "Unused_2" 5 "Unused_1" 4 "PERS_4" 3 "PERS_3" 2 "PERS_2" 1 "PERS_1" 0 "Null" ;
VAL_TABLE_ Pers1_4 7 "Unused_3" 6 "Unused_2" 5 "Unused_1" 4 "Vehicle" 3 "PERS_4" 2 "PERS_3" 1 "PERS_2" 0 "PERS_1" ;
VAL_TABLE_ Null_Query 7 "Unused_2" 6 "Unused_1" 5 "Copy" 4 "Restore" 3 "Upload" 2 "Set" 1 "Query" 0 "Null" ;
VAL_TABLE_ Ign_Key_Device_Type 15 "Invalid" 14 "Unknown" 3 "Key_Not_Prgrm_Read_Failure" 2 "Key_In_Ign_My_Key" 1 "Key_In_Ign_Standard_Key" 0 "Key_Read_In_Progress" ;
VAL_TABLE_ Off_No_Eff_Unknown_Invalid 3 "Invalid" 2 "Unknown" 1 "No_Effect" 0 "Off" ;
VAL_TABLE_ Null_Out 1 "Out" 0 "Null" ;

BO_ 612 AUXM_Data: 8 BCMB_AUXM
 SG_ SelDrvMdeSwtch_D_Stat6 : 7|2@0+ (1,0) [0|3] "SED"  GWM

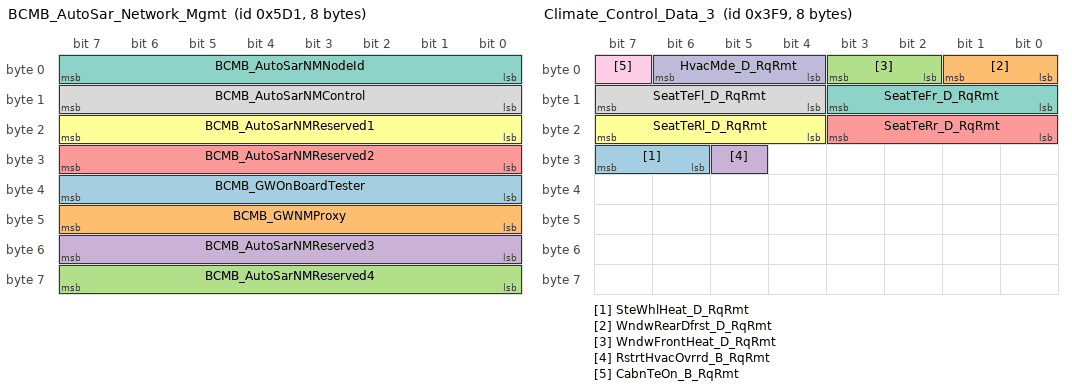
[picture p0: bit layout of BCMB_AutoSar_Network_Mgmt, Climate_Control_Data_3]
BO_ 1489 BCMB_AutoSar_Network_Mgmt: 8 BCMB_AUXM
 SG_ BCMB_GWOnBoardTester : 39|8@0+ (1,0) [0|255] "unitless" Vector__XXX
 SG_ BCMB_GWNMProxy : 47|8@0+ (1,0) [0|255] "unitless" Vector__XXX
 SG_ BCMB_AutoSarNMReserved4 : 63|8@0+ (1,0) [0|255] "unitless" Vector__XXX
 SG_ BCMB_AutoSarNMReserved3 : 55|8@0+ (1,0) [0|255] "unitless" Vector__XXX
 SG_ BCMB_AutoSarNMReserved2 : 31|8@0+ (1,0) [0|255] "unitless" Vector__XXX
 SG_ BCMB_AutoSarNMReserved1 : 23|8@0+ (1,0) [0|255] "unitless" Vector__XXX
 SG_ BCMB_AutoSarNMNodeId : 7|8@0+ (1,0) [0|255] "unitless" Vector__XXX
 SG_ BCMB_AutoSarNMControl : 15|8@0+ (1,0) [0|255] "unitless" Vector__XXX

BO_ 1017 Climate_Control_Data_3: 8 GWM
 SG_ SteWhlHeat_D_RqRmt : 31|2@0+ (1,0) [0|3] "SED"  HVAC_RCCM
 SG_ WndwRearDfrst_D_RqRmt : 1|2@0+ (1,0) [0|3] "SED"  HVAC_RCCM
 SG_ WndwFrontHeat_D_RqRmt : 3|2@0+ (1,0) [0|3] "SED"  HVAC_RCCM
 SG_ RstrtHvacOvrrd_B_RqRmt : 29|1@0+ (1,0) [0|1] "SED"  HVAC_RCCM
 SG_ SeatTeRr_D_RqRmt : 19|4@0+ (1,0) [0|15] "SED"  HVAC_RCCM
 SG_ SeatTeRl_D_RqRmt : 23|4@0+ (1,0) [0|15] "SED"  HVAC_RCCM
 SG_ SeatTeFr_D_RqRmt : 11|4@0+ (1,0) [0|15] "SED"  HVAC_RCCM
 SG_ SeatTeFl_D_RqRmt : 15|4@0+ (1,0) [0|15] "SED"  HVAC_RCCM
 SG_ CabnTeOn_B_RqRmt : 7|1@0+ (1,0) [0|1] "SED"  HVAC_RCCM
 SG_ HvacMde_D_RqRmt : 6|3@0+ (1,0) [0|7] "SED"  HVAC_RCCM

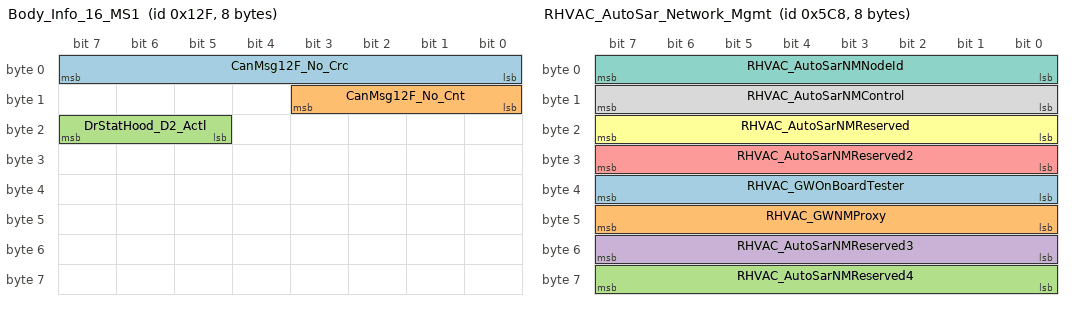
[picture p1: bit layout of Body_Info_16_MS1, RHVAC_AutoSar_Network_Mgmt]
BO_ 303 Body_Info_16_MS1: 8 GWM
 SG_ CanMsg12F_No_Crc : 7|8@0+ (1,0) [0|255] "Unitless"  GFM_FTRM
 SG_ CanMsg12F_No_Cnt : 11|4@0+ (1,0) [0|15] "Unitless"  GFM_FTRM
 SG_ DrStatHood_D2_Actl : 23|3@0+ (1,0) [0|7] "SED"  GFM_FTRM

BO_ 2611021016 PARSEDPhysGWM_ECGtoSCMJ: 8 GWM
 SG_ PARSEDPhysGWM_ECGtoSCMJ : 7|29@0+ (1,0) [0|536870911] "unitless"  SCMJ

BO_ 1480 RHVAC_AutoSar_Network_Mgmt: 8 RHVAC
 SG_ RHVAC_GWOnBoardTester : 39|8@0+ (1,0) [0|255] "unitless"  GWM
 SG_ RHVAC_GWNMProxy : 47|8@0+ (1,0) [0|255] "unitless"  GWM
 SG_ RHVAC_AutoSarNMReserved4 : 63|8@0+ (1,0) [0|255] "unitless"  GWM
 SG_ RHVAC_AutoSarNMReserved3 : 55|8@0+ (1,0) [0|255] "unitless"  GWM
 SG_ RHVAC_AutoSarNMReserved2 : 31|8@0+ (1,0) [0|255] "unitless"  GWM
 SG_ RHVAC_AutoSarNMReserved : 23|8@0+ (1,0) [0|255] "unitless"  GWM
 SG_ RHVAC_AutoSarNMNodeId : 7|8@0+ (1,0) [0|255] "unitless"  GWM
 SG_ RHVAC_AutoSarNMControl : 15|8@0+ (1,0) [0|255] "unitless"  GWM

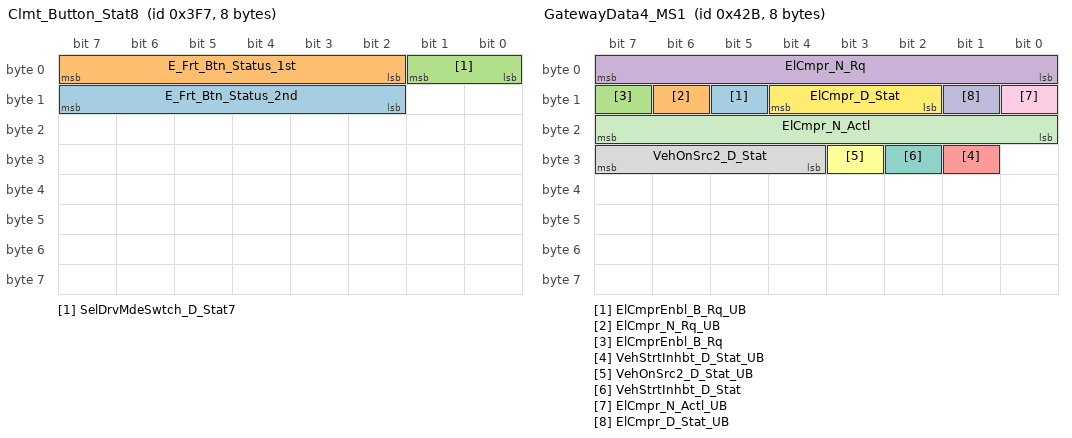
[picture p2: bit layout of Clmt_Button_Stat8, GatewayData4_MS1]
BO_ 1015 Clmt_Button_Stat8: 8 FCIM
 SG_ E_Frt_Btn_Status_2nd : 15|6@0+ (1,0) [0|63] "SED"  HVAC_RCCM,GWM
 SG_ E_Frt_Btn_Status_1st : 7|6@0+ (1,0) [0|63] "SED"  HVAC_RCCM,GWM
 SG_ SelDrvMdeSwtch_D_Stat7 : 1|2@0+ (1,0) [0|3] "SED"  GWM

BO_ 1067 GatewayData4_MS1: 8 GWM
 SG_ ElCmprEnbl_B_Rq_UB : 13|1@0+ (1,0) [0|1] "SED"  HVAC_RCCM
 SG_ ElCmpr_N_Rq_UB : 14|1@0+ (1,0) [0|1] "SED"  HVAC_RCCM
 SG_ ElCmprEnbl_B_Rq : 15|1@0+ (1,0) [0|1] "SED"  HVAC_RCCM
 SG_ ElCmpr_N_Rq : 7|8@0+ (50,0) [0|12750] "RPM"  HVAC_RCCM
 SG_ VehStrtInhbt_D_Stat_UB : 25|1@0+ (1,0) [0|1] "SED"  DSM,SCME,SCMF,SCMB_PSM,DDM,PDM,RGTM
 SG_ VehOnSrc2_D_Stat_UB : 27|1@0+ (1,0) [0|1] "SED"  SCME,SCMF,DSM,SCMB_PSM,DDM,PDM,RGTM
 SG_ VehStrtInhbt_D_Stat : 26|1@0+ (1,0) [0|1] "SED"  DSM,SCME,SCMF,SCMB_PSM,DDM,PDM,RGTM
 SG_ VehOnSrc2_D_Stat : 31|4@0+ (1,0) [0|15] "SED"  SCME,SCMF,DSM,SCMB_PSM,DDM,PDM,RGTM
 SG_ ElCmpr_N_Actl_UB : 8|1@0+ (1,0) [0|1] "SED"  HVAC_RCCM
 SG_ ElCmpr_D_Stat_UB : 9|1@0+ (1,0) [0|1] "SED"  HVAC_RCCM
 SG_ ElCmpr_N_Actl : 23|8@0+ (50,0) [0|12700] "RPM"  HVAC_RCCM
 SG_ ElCmpr_D_Stat : 12|3@0+ (1,0) [0|7] "SED"  HVAC_RCCM

BO_ 2612191448 PARSEDPushFcGWM_ECGtoMRCMA: 8 GWM
 SG_ PARSEDPushFcGWM_ECGtoMRCMA : 7|29@0+ (1,0) [0|536870911] "unitless"  MRCMA_RSCM

BO_ 2612224184 PARSEDPushMRCMAtoGWM_ECG: 8 MRCMA_RSCM
 SG_ PARSEDPushMRCMAtoGWM_ECG : 7|29@0+ (1,0) [0|536870911] "unitless"  GWM

BO_ 2611142872 PARSEDPhysGWM_ECGtoMRCMA: 8 GWM
 SG_ PARSEDPhysGWM_ECGtoMRCMA : 7|29@0+ (1,0) [0|536870911] "unitless"  MRCMA_RSCM

BO_ 2611175608 PARSEDPhysMRCMAtoGWM_ECG: 8 MRCMA_RSCM
 SG_ PARSEDPhysMRCMAtoGWM_ECG : 7|29@0+ (1,0) [0|536870911] "unitless"  GWM

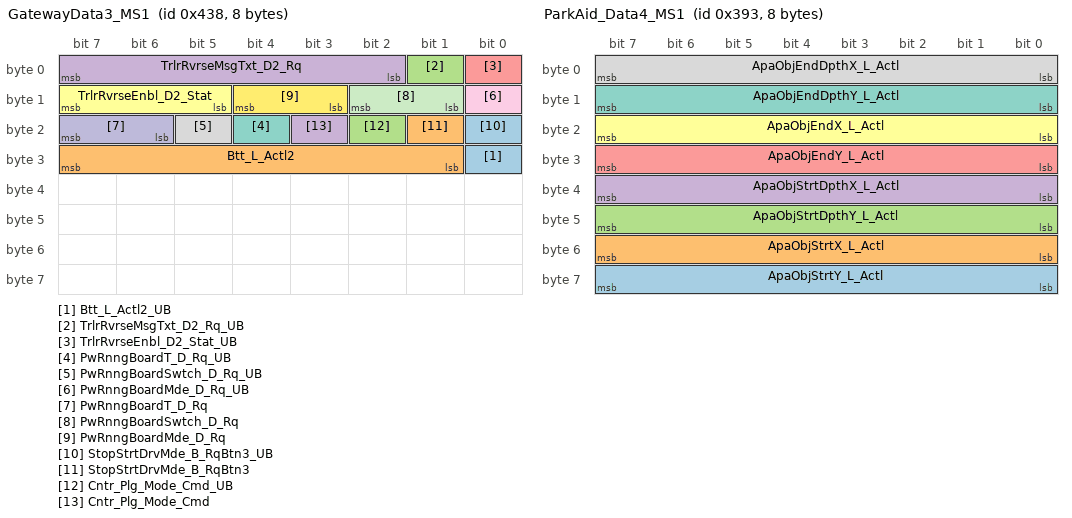
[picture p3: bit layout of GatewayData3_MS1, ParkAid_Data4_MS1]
BO_ 1080 GatewayData3_MS1: 8 GWM
 SG_ Btt_L_Actl2_UB : 24|1@0+ (1,0) [0|1] "SED"  SODL,SODR
 SG_ Btt_L_Actl2 : 31|7@0+ (0.1,0) [0|12.5] "meter"  SODL,SODR
 SG_ TrlrRvrseMsgTxt_D2_Rq_UB : 1|1@0+ (1,0) [0|1] "SED"  TRM
 SG_ TrlrRvrseMsgTxt_D2_Rq : 7|6@0+ (1,0) [0|63] "SED"  TRM
 SG_ TrlrRvrseEnbl_D2_Stat_UB : 0|1@0+ (1,0) [0|1] "SED"  TRM
 SG_ TrlrRvrseEnbl_D2_Stat : 15|3@0+ (1,0) [0|7] "SED"  TRM
 SG_ PwRnngBoardT_D_Rq_UB : 20|1@0+ (1,0) [0|1] "SED"  DSM
 SG_ PwRnngBoardSwtch_D_Rq_UB : 21|1@0+ (1,0) [0|1] "SED"  DSM
 SG_ PwRnngBoardMde_D_Rq_UB : 8|1@0+ (1,0) [0|1] "SED"  DSM
 SG_ PwRnngBoardT_D_Rq : 23|2@0+ (1,0) [0|3] "SED"  DSM
 SG_ PwRnngBoardSwtch_D_Rq : 10|2@0+ (1,0) [0|3] "SED"  DSM
 SG_ PwRnngBoardMde_D_Rq : 12|2@0+ (1,0) [0|3] "SED"  DSM
 SG_ StopStrtDrvMde_B_RqBtn3_UB : 16|1@0+ (1,0) [0|1] "SED"  HVAC_RCCM
 SG_ StopStrtDrvMde_B_RqBtn3 : 17|1@0+ (1,0) [0|1] "SED"  HVAC_RCCM
 SG_ Cntr_Plg_Mode_Cmd_UB : 18|1@0+ (1,0) [0|1] "SED"  RGTM
 SG_ Cntr_Plg_Mode_Cmd : 19|1@0+ (1,0) [0|1] "SED"  RGTM

BO_ 2610094296 OTAPhysGWM_ECGtoMRCMA: 8 GWM
 SG_ OTAPhysGWM_ECG_to_MRCMA : 7|29@0+ (1,0) [0|536870911] "unitless"  MRCMA_RSCM

BO_ 2610127032 OTAPhysMRCMAtoGWM_ECG: 8 MRCMA_RSCM
 SG_ OTAPhysMRCMAtoGWM_ECG : 7|29@0+ (1,0) [0|536870911] "unitless"  GWM

BO_ 1257 BoundaryAlert_10: 8 SODR
 SG_ BalrSysData4_No_Actl : 39|32@0+ (1,0) [0|4294967295] "unitless"  SODL
 SG_ BalrSysData3_No_Actl : 7|32@0+ (1,0) [0|4294967295] "unitless"  SODL

BO_ 1256 BoundaryAlert_9: 8 SODL
 SG_ BalrSysData2_No_Actl : 39|32@0+ (1,0) [0|4294967295] "unitless"  SODR
 SG_ BalrSysData1_No_Actl : 7|32@0+ (1,0) [0|4294967295] "unitless"  SODR

BO_ 2610085080 OTAPhysGWM_ECGtoRGTM: 8 GWM
 SG_ OTAPhysGWM_ECGtoRGTM : 7|29@0+ (1,0) [0|536870911] "unitless"  RGTM

BO_ 2611133656 PARSEDPhysGWM_ECGtoRGTM: 8 GWM
 SG_ PARSEDPhysGWM_ECGtoRGTM : 7|29@0+ (1,0) [0|536870911] "unitless"  RGTM

BO_ 2612182232 PARSEDPushFcGWM_ECGtoRGTM: 8 GWM
 SG_ PARSEDPushFcGWM_ECGtoRGTM : 7|29@0+ (1,0) [0|536870911] "unitless"  RGTM

BO_ 915 ParkAid_Data4_MS1: 8 GWM
 SG_ ApaObjStrtY_L_Actl : 63|8@0+ (0.12807301,-24) [-24|8.65861755] "meter"  SODR,SODL
 SG_ ApaObjStrtX_L_Actl : 55|8@0+ (0.12807301,-24) [-24|8.65861755] "meter"  SODR,SODL
 SG_ ApaObjStrtDpthY_L_Actl : 47|8@0+ (0.12807301,-24) [-24|8.65861755] "meter"  SODR,SODL
 SG_ ApaObjStrtDpthX_L_Actl : 39|8@0+ (0.12807301,-24) [-24|8.65861755] "meter"  SODR,SODL
 SG_ ApaObjEndY_L_Actl : 31|8@0+ (0.12807301,-24) [-24|8.65861755] "meter"  SODR,SODL
 SG_ ApaObjEndX_L_Actl : 23|8@0+ (0.12807301,-24) [-24|8.65861755] "meter"  SODR,SODL
 SG_ ApaObjEndDpthY_L_Actl : 15|8@0+ (0.12807301,-24) [-24|8.65861755] "meter"  SODR,SODL
 SG_ ApaObjEndDpthX_L_Actl : 7|8@0+ (0.12807301,-24) [-24|8.65861755] "meter"  SODR,SODL

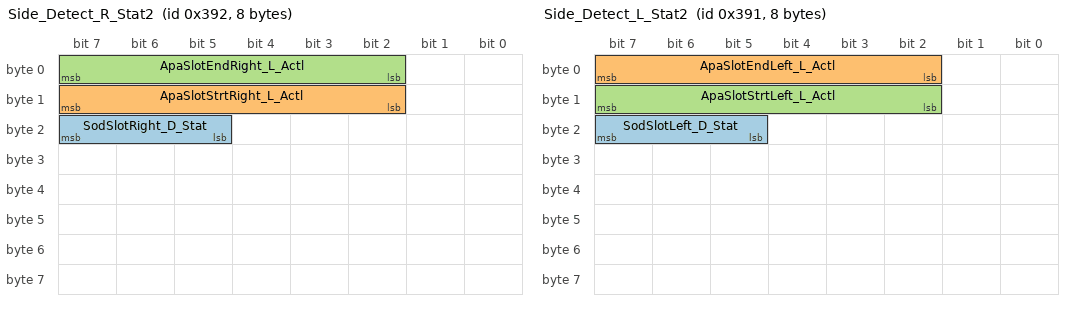
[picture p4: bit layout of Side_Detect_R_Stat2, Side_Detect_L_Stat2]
BO_ 914 Side_Detect_R_Stat2: 8 SODR
 SG_ SodSlotRight_D_Stat : 23|3@0+ (1,0) [0|7] "SED"  GWM
 SG_ ApaSlotStrtRight_L_Actl : 15|6@0+ (0.064,0) [0|4.032] "meter"  GWM
 SG_ ApaSlotEndRight_L_Actl : 7|6@0+ (0.064,0) [0|4.032] "meter"  GWM

BO_ 913 Side_Detect_L_Stat2: 8 SODL
 SG_ SodSlotLeft_D_Stat : 23|3@0+ (1,0) [0|7] "SED"  GWM
 SG_ ApaSlotEndLeft_L_Actl : 7|6@0+ (0.064,0) [0|4.032] "meter"  GWM
 SG_ ApaSlotStrtLeft_L_Actl : 15|6@0+ (0.064,0) [0|4.032] "meter"  GWM

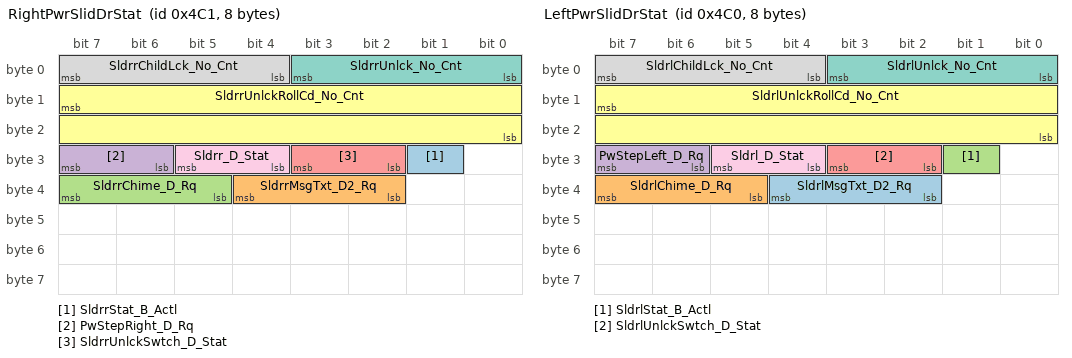
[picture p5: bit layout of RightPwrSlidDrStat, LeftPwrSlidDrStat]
BO_ 1217 RightPwrSlidDrStat: 8 Vector__XXX
 SG_ SldrrStat_B_Actl : 25|1@0+ (1,0) [0|1] "SED"  GWM
 SG_ SldrrMsgTxt_D2_Rq : 36|3@0+ (1,0) [0|7] "SED"  GWM
 SG_ SldrrChime_D_Rq : 39|3@0+ (1,0) [0|7] "SED"  GWM
 SG_ PwStepRight_D_Rq : 31|2@0+ (1,0) [0|3] "SED"  DSM,GWM,RBM
 SG_ SldrrUnlckSwtch_D_Stat : 27|2@0+ (1,0) [0|3] "SED"  GWM
 SG_ SldrrUnlckRollCd_No_Cnt : 15|16@0+ (1,0) [0|65535] "unitless"  GWM
 SG_ SldrrUnlck_No_Cnt : 3|4@0+ (1,0) [0|15] "unitless"  GWM
 SG_ SldrrChildLck_No_Cnt : 7|4@0+ (1,0) [0|15] "unitless"  GWM
 SG_ Sldrr_D_Stat : 29|2@0+ (1,0) [0|3] "SED"  GWM

BO_ 1216 LeftPwrSlidDrStat: 8 Vector__XXX
 SG_ SldrlMsgTxt_D2_Rq : 36|3@0+ (1,0) [0|7] "SED"  GWM
 SG_ SldrlChime_D_Rq : 39|3@0+ (1,0) [0|7] "SED"  GWM
 SG_ SldrlStat_B_Actl : 25|1@0+ (1,0) [0|1] "SED"  GWM
 SG_ PwStepLeft_D_Rq : 31|2@0+ (1,0) [0|3] "SED"  DSM,GWM,RBM
 SG_ SldrlUnlckSwtch_D_Stat : 27|2@0+ (1,0) [0|3] "SED"  GWM
 SG_ SldrlUnlckRollCd_No_Cnt : 15|16@0+ (1,0) [0|65535] "unitless"  GWM
 SG_ SldrlUnlck_No_Cnt : 3|4@0+ (1,0) [0|15] "unitless"  GWM
 SG_ SldrlChildLck_No_Cnt : 7|4@0+ (1,0) [0|15] "unitless"  GWM
 SG_ Sldrl_D_Stat : 29|2@0+ (1,0) [0|3] "SED"  GWM

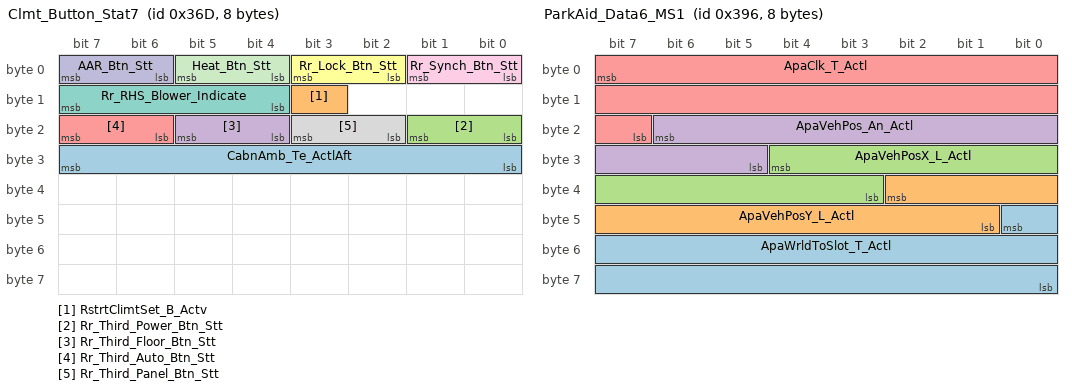
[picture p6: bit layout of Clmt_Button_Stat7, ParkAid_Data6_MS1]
BO_ 877 Clmt_Button_Stat7: 8 HVAC_RCCM
 SG_ CabnAmb_Te_ActlAft : 31|8@0+ (0.5,-57) [-57|70] "degC"  GWM
 SG_ RstrtClimtSet_B_Actv : 11|1@0+ (1,0) [0|1] "SED"  GWM
 SG_ Rr_Third_Power_Btn_Stt : 17|2@0+ (1,0) [0|3] "SED"  RHVAC,GWM
 SG_ Rr_Third_Floor_Btn_Stt : 21|2@0+ (1,0) [0|3] "SED"  RHVAC,GWM
 SG_ Rr_Third_Auto_Btn_Stt : 23|2@0+ (1,0) [0|3] "SED"  RHVAC,GWM
 SG_ Rr_Lock_Btn_Stt : 3|2@0+ (1,0) [0|3] "SED"  RHVAC,GWM
 SG_ Rr_RHS_Blower_Indicate : 15|4@0+ (1,0) [0|15] "SED"  RHVAC,GWM
 SG_ Rr_Third_Panel_Btn_Stt : 19|2@0+ (1,0) [0|3] "SED"  RHVAC,GWM
 SG_ Rr_Synch_Btn_Stt : 1|2@0+ (1,0) [0|3] "SED"  RHVAC,GWM
 SG_ AAR_Btn_Stt : 7|2@0+ (1,0) [0|3] "SED"  GWM
 SG_ Heat_Btn_Stt : 5|2@0+ (1,0) [0|3] "SED"  GWM

BO_ 918 ParkAid_Data6_MS1: 8 GWM
 SG_ ApaWrldToSlot_T_Actl : 40|17@0+ (0.000512,0) [0|67.108352] "second"  SODR,SODL
 SG_ ApaVehPosY_L_Actl : 34|10@0+ (64,-32768) [-32768|32704] "millimeter"  SODR,SODL
 SG_ ApaVehPosX_L_Actl : 28|10@0+ (64,-32768) [-32768|32704] "millimeter"  SODR,SODL
 SG_ ApaVehPos_An_Actl : 22|10@0+ (0.3515625,-180) [-180|179.6484375] "degrees"  SODR,SODL
 SG_ ApaClk_T_Actl : 7|17@0+ (0.000512,0) [0|67.108352] "second"  SODR,SODL

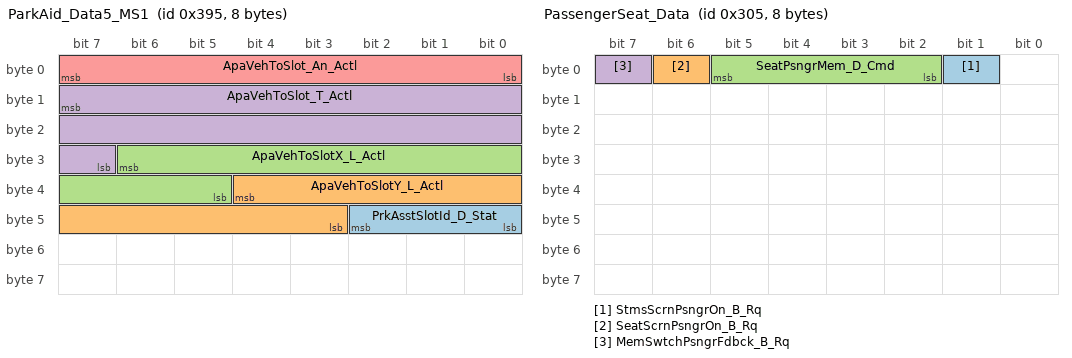
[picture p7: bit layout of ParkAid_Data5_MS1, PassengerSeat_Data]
BO_ 917 ParkAid_Data5_MS1: 8 GWM
 SG_ PrkAsstSlotId_D_Stat : 42|3@0+ (1,0) [0|7] "SED"  SODR,SODL
 SG_ ApaVehToSlotY_L_Actl : 36|10@0+ (64,-32768) [-32768|32704] "millimeter"  SODR,SODL
 SG_ ApaVehToSlotX_L_Actl : 30|10@0+ (64,-32768) [-32768|32704] "millimeter"  SODR,SODL
 SG_ ApaVehToSlot_T_Actl : 15|17@0+ (0.000512,0) [0|67.108352] "second"  SODR,SODL
 SG_ ApaVehToSlot_An_Actl : 7|8@0+ (1.4118,-180) [-180|180.009] "degrees"  SODR,SODL

BO_ 773 PassengerSeat_Data: 8 SCMB_PSM
 SG_ StmsScrnPsngrOn_B_Rq : 1|1@0+ (1,0) [0|1] "SED"  GWM
 SG_ SeatScrnPsngrOn_B_Rq : 6|1@0+ (1,0) [0|1] "SED"  GWM
 SG_ SeatPsngrMem_D_Cmd : 5|4@0+ (1,0) [0|15] "SED"  SCMH
 SG_ MemSwtchPsngrFdbck_B_Rq : 7|1@0+ (1,0) [0|1] "SED"  DSM

BO_ 878 Rear_Climate_Data2_MS1: 8 GWM
 SG_ ClimtSyncRear2_B_Stat : 58|1@0+ (1,0) [0|1] "SED"  FCIM,HVAC_RCCM
 SG_ ClimtStHeatRr2_B_Stat : 54|1@0+ (1,0) [0|1] "SED"  FCIM,HVAC_RCCM
 SG_ ClimtStHeatRl2_B_Stat : 55|1@0+ (1,0) [0|1] "SED"  FCIM,HVAC_RCCM
 SG_ ClimtStCoolRr2_B_Stat : 52|1@0+ (1,0) [0|1] "SED"  FCIM,HVAC_RCCM
 SG_ ClimtStCoolRl2_B_Stat : 53|1@0+ (1,0) [0|1] "SED"  FCIM,HVAC_RCCM
 SG_ ClimtSeatRr2_D_Rq : 39|8@0+ (1,0) [0|64] "SED"  FCIM,HVAC_RCCM
 SG_ ClimtSeatRl2_D_Rq : 47|8@0+ (1,0) [0|64] "SED"  FCIM,HVAC_RCCM
 SG_ ClimtRrTe3rd2_D_Stat : 51|2@0+ (1,0) [0|3] "SED"  FCIM,HVAC_RCCM
 SG_ ClimtRrPw3rd2_B_Stat : 59|1@0+ (1,0) [0|1] "SED"  FCIM,HVAC_RCCM
 SG_ ClimtRrPnl3rd2_B_Stat : 62|1@0+ (1,0) [0|1] "SED"  FCIM,HVAC_RCCM
 SG_ ClimtRrPf3rd2_B_Stat : 63|1@0+ (1,0) [0|1] "SED"  FCIM,HVAC_RCCM
 SG_ ClimtRrFlr3rd2_B_Stat : 61|1@0+ (1,0) [0|1] "SED"  FCIM,HVAC_RCCM
 SG_ ClimtRrBlwr3rd2_D_Stat : 49|2@0+ (1,0) [0|3] "SED"  FCIM,HVAC_RCCM
 SG_ ClimtRrAuto3rd2_B_Stat : 60|1@0+ (1,0) [0|1] "SED"  FCIM,HVAC_RCCM
 SG_ ClimtRearView2_D_Stat : 57|2@0+ (1,0) [0|3] "SED"  FCIM,HVAC_RCCM
 SG_ ClimtRearTe2_D_Stat : 11|2@0+ (1,0) [0|3] "SED"  FCIM,HVAC_RCCM
 SG_ ClimtRearTe2_An_Actl : 7|9@0+ (1,0) [0|510] "degrees"  FCIM,HVAC_RCCM
 SG_ ClimtRearPw2_B_Stat : 29|1@0+ (1,0) [0|1] "SED"  FCIM,HVAC_RCCM
 SG_ ClimtRearPnlFlr2_B_Stat : 13|1@0+ (1,0) [0|1] "SED"  FCIM,HVAC_RCCM
 SG_ ClimtRearPnl2_B_Stat : 14|1@0+ (1,0) [0|1] "SED"  FCIM,HVAC_RCCM
 SG_ ClimtRearFlr2_B_Stat : 12|1@0+ (1,0) [0|1] "SED"  FCIM,HVAC_RCCM
 SG_ ClimtRearBlwr2_D_Stat : 9|2@0+ (1,0) [0|3] "SED"  FCIM,HVAC_RCCM
 SG_ ClimtRearBlwr2_An_Actl : 23|9@0+ (1,0) [0|510] "degrees"  FCIM,HVAC_RCCM
 SG_ ClimtRearAuto2_B_Stat : 30|1@0+ (1,0) [0|1] "SED"  FCIM,HVAC_RCCM

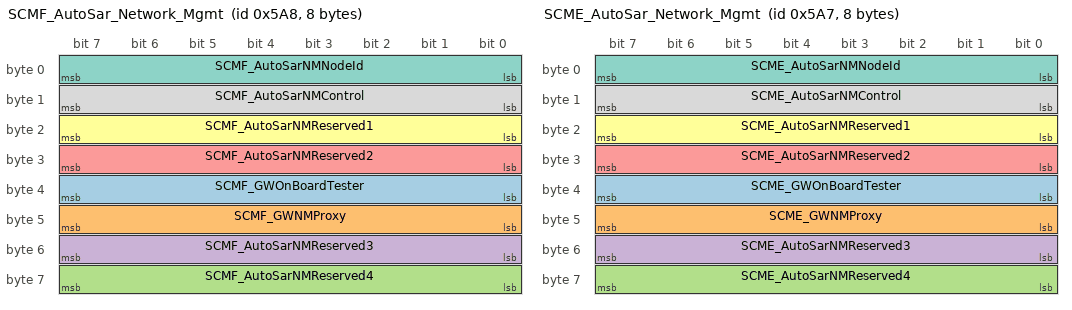
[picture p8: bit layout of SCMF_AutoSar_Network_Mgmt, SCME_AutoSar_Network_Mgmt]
BO_ 1448 SCMF_AutoSar_Network_Mgmt: 8 SCMF
 SG_ SCMF_GWOnBoardTester : 39|8@0+ (1,0) [0|255] "unitless"  GWM
 SG_ SCMF_GWNMProxy : 47|8@0+ (1,0) [0|255] "unitless"  GWM
 SG_ SCMF_AutoSarNMReserved4 : 63|8@0+ (1,0) [0|255] "unitless"  GWM
 SG_ SCMF_AutoSarNMReserved3 : 55|8@0+ (1,0) [0|255] "unitless"  GWM
 SG_ SCMF_AutoSarNMReserved2 : 31|8@0+ (1,0) [0|255] "unitless"  GWM
 SG_ SCMF_AutoSarNMReserved1 : 23|8@0+ (1,0) [0|255] "unitless"  GWM
 SG_ SCMF_AutoSarNMNodeId : 7|8@0+ (1,0) [0|255] "unitless"  GWM
 SG_ SCMF_AutoSarNMControl : 15|8@0+ (1,0) [0|255] "unitless"  GWM

BO_ 1447 SCME_AutoSar_Network_Mgmt: 8 SCME
 SG_ SCME_GWOnBoardTester : 39|8@0+ (1,0) [0|255] "unitless"  GWM
 SG_ SCME_GWNMProxy : 47|8@0+ (1,0) [0|255] "unitless"  GWM
 SG_ SCME_AutoSarNMReserved4 : 63|8@0+ (1,0) [0|255] "unitless"  GWM
 SG_ SCME_AutoSarNMReserved3 : 55|8@0+ (1,0) [0|255] "unitless"  GWM
 SG_ SCME_AutoSarNMReserved2 : 31|8@0+ (1,0) [0|255] "unitless"  GWM
 SG_ SCME_AutoSarNMReserved1 : 23|8@0+ (1,0) [0|255] "unitless"  GWM
 SG_ SCME_AutoSarNMNodeId : 7|8@0+ (1,0) [0|255] "unitless"  GWM
 SG_ SCME_AutoSarNMControl : 15|8@0+ (1,0) [0|255] "unitless"  GWM

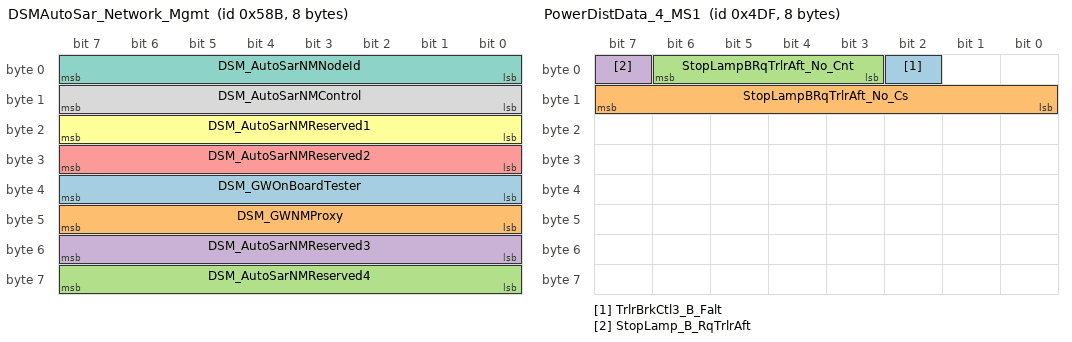
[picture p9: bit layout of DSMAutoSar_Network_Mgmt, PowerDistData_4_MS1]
BO_ 1419 DSMAutoSar_Network_Mgmt: 8 DSM
 SG_ DSM_GWOnBoardTester : 39|8@0+ (1,0) [0|255] "unitless"  GWM
 SG_ DSM_GWNMProxy : 47|8@0+ (1,0) [0|255] "unitless"  GWM
 SG_ DSM_AutoSarNMReserved4 : 63|8@0+ (1,0) [0|255] "unitless"  GWM
 SG_ DSM_AutoSarNMReserved3 : 55|8@0+ (1,0) [0|255] "unitless"  GWM
 SG_ DSM_AutoSarNMReserved2 : 31|8@0+ (1,0) [0|255] "unitless"  GWM
 SG_ DSM_AutoSarNMReserved1 : 23|8@0+ (1,0) [0|255] "unitless"  GWM
 SG_ DSM_AutoSarNMNodeId : 7|8@0+ (1,0) [0|255] "unitless"  GWM
 SG_ DSM_AutoSarNMControl : 15|8@0+ (1,0) [0|255] "unitless"  GWM

BO_ 1247 PowerDistData_4_MS1: 8 GWM
 SG_ TrlrBrkCtl3_B_Falt : 2|1@0+ (1,0) [0|1] "SED"  TRM
 SG_ StopLampBRqTrlrAft_No_Cs : 15|8@0+ (1,0) [0|255] "Unitless"  TRM
 SG_ StopLampBRqTrlrAft_No_Cnt : 6|4@0+ (1,0) [0|15] "Unitless"  TRM
 SG_ StopLamp_B_RqTrlrAft : 7|1@0+ (1,0) [0|1] "SED"  TRM

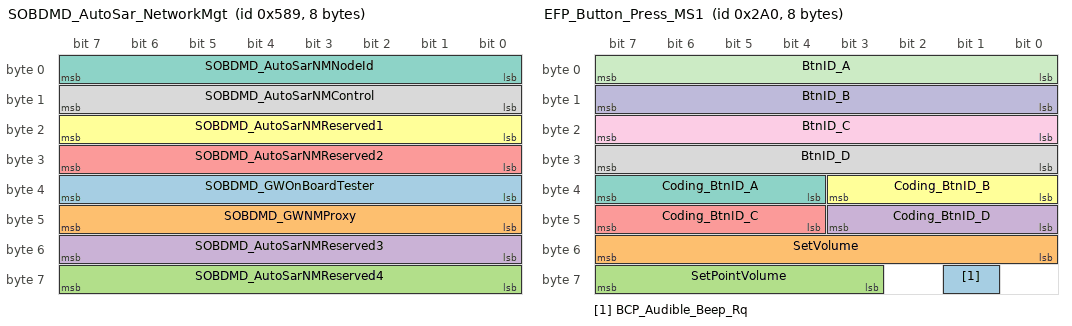
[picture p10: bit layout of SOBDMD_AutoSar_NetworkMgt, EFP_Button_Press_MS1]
BO_ 1417 SOBDMD_AutoSar_NetworkMgt: 8 SOBDMD_AHCM_FOH
 SG_ SOBDMD_GWOnBoardTester : 39|8@0+ (1,0) [0|255] "unitless"  GWM
 SG_ SOBDMD_GWNMProxy : 47|8@0+ (1,0) [0|255] "unitless"  GWM
 SG_ SOBDMD_AutoSarNMReserved4 : 63|8@0+ (1,0) [0|255] "unitless"  GWM
 SG_ SOBDMD_AutoSarNMReserved3 : 55|8@0+ (1,0) [0|255] "unitless"  GWM
 SG_ SOBDMD_AutoSarNMReserved2 : 31|8@0+ (1,0) [0|255] "unitless"  GWM
 SG_ SOBDMD_AutoSarNMReserved1 : 23|8@0+ (1,0) [0|255] "unitless"  GWM
 SG_ SOBDMD_AutoSarNMNodeId : 7|8@0+ (1,0) [0|255] "unitless"  GWM
 SG_ SOBDMD_AutoSarNMControl : 15|8@0+ (1,0) [0|255] "unitless"  GWM

BO_ 672 EFP_Button_Press_MS1: 8 FCIM
 SG_ BCP_Audible_Beep_Rq : 57|1@0+ (1,0) [0|1] "SED"  GWM
 SG_ SetVolume : 55|8@0+ (1,-30) [-30|30] "unitless"  GWM
 SG_ SetPointVolume : 63|5@0+ (1,0) [0|31] "unitless"  GWM
 SG_ Coding_BtnID_D : 43|4@0+ (1,0) [0|15] "SED"  GWM
 SG_ Coding_BtnID_C : 47|4@0+ (1,0) [0|15] "SED"  GWM
 SG_ Coding_BtnID_B : 35|4@0+ (1,0) [0|15] "SED"  GWM
 SG_ Coding_BtnID_A : 39|4@0+ (1,0) [0|15] "SED"  GWM
 SG_ BtnID_D : 31|8@0+ (1,0) [0|255] "unitless"  GWM
 SG_ BtnID_C : 23|8@0+ (1,0) [0|255] "unitless"  GWM
 SG_ BtnID_B : 15|8@0+ (1,0) [0|255] "unitless"  GWM
 SG_ BtnID_A : 7|8@0+ (1,0) [0|255] "unitless"  GWM

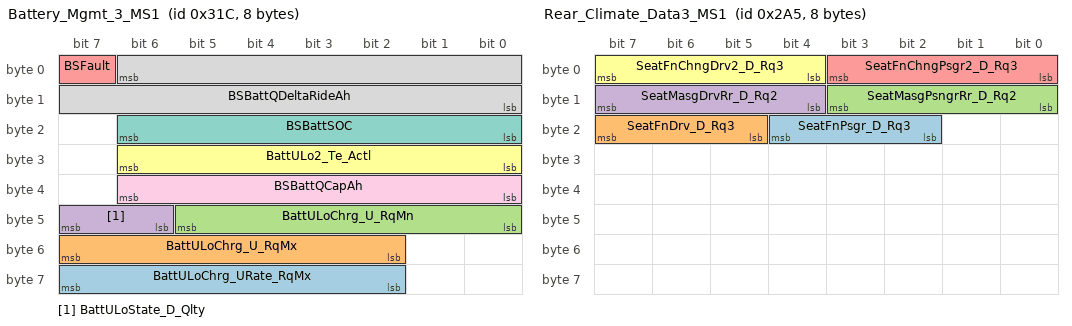
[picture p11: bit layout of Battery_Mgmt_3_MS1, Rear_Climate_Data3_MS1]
BO_ 796 Battery_Mgmt_3_MS1: 8 GWM
 SG_ BattULoChrg_URate_RqMx : 63|6@0+ (0.1,0) [0|6.3] "volts/second"  GWM
 SG_ BattULoChrg_U_RqMx : 55|6@0+ (0.1,10.6) [10.6|16.9] "volt"  GWM
 SG_ BattULoChrg_U_RqMn : 45|6@0+ (0.1,10.6) [10.6|16.9] "volt"  GWM
 SG_ BattULoState_D_Qlty : 47|2@0+ (1,0) [0|3] "SED"  FCIM,SOBDMD_AHCM_FOH,HVAC_RCCM
 SG_ BSFault : 7|1@0+ (1,0) [0|1] "SED"  FCIM,HVAC_RCCM
 SG_ BattULo2_Te_Actl : 30|7@0+ (1,-40) [-40|86] "degC"  FCIM,HVAC_RCCM
 SG_ BSBattSOC : 22|7@0+ (1,0) [0|127] "%"  FCIM,SOBDMD_AHCM_FOH,HVAC_RCCM
 SG_ BSBattQDeltaRideAh : 6|15@0+ (0.0078125,-100) [-100|155.9921875] "ampere*hour"  GWM
 SG_ BSBattQCapAh : 38|7@0+ (1,0) [0|127] "ampere*hour"  GWM

BO_ 2610127023 OTAPhysRGTMtoGWM_ECG: 8 RGTM
 SG_ OTAPhysRGTMtoGWM_ECG : 7|29@0+ (1,0) [0|536870911] "unitless"  GWM

BO_ 2612077784 PARSEDPushFcGWM_ECGtoRSM: 8 GWM
 SG_ PARSEDPushFcGWM_ECGtoRSM : 7|29@0+ (1,0) [0|536870911] "unitless"  RSM

BO_ 2611175497 PARSEDPhysRSMtoGWM_ECG: 8 RSM
 SG_ PARSEDPhysRSMtoGWM_ECG : 7|29@0+ (1,0) [0|536870911] "unitless"  GWM

BO_ 2611029208 PARSEDPhysGWM_ECGtoRSM: 8 GWM
 SG_ PARSEDPhysGWM_ECGtoRSM : 7|29@0+ (1,0) [0|536870911] "unitless"  RSM

BO_ 1364 TRM_Network_MgmtM: 8 TRM
 SG_ TRM_Network_Mgmt : 7|64@0+ (1,0) [0|1.84467440737096E+019] "unitless"  HVAC_RCCM,GENERIC

BO_ 2610126921 OTAPhysRSMtoGWM_ECG: 8 RSM
 SG_ OTAPhysRSMtoGWM_ECG : 7|29@0+ (1,0) [0|536870911] "unitless"  GWM

BO_ 2609980632 OTAPhysGWM_ECGtoRSM: 8 GWM
 SG_ OTAPhysGWM_ECGtoRSM : 7|29@0+ (1,0) [0|536870911] "unitless"  RSM

BO_ 677 Rear_Climate_Data3_MS1: 8 GWM
 SG_ SeatFnPsgr_D_Rq3 : 20|3@0+ (1,0) [0|7] "SED"  SCMD
 SG_ SeatFnDrv_D_Rq3 : 23|3@0+ (1,0) [0|7] "SED"  SCMC
 SG_ SeatMasgPsngrRr_D_Rq2 : 11|4@0+ (1,0) [0|15] "SED"  SCMD
 SG_ SeatMasgDrvRr_D_Rq2 : 15|4@0+ (1,0) [0|15] "SED"  SCMC
 SG_ SeatFnChngPsgr2_D_Rq3 : 3|4@0+ (1,0) [0|15] "SED"  SCMD
 SG_ SeatFnChngDrv2_D_Rq3 : 7|4@0+ (1,0) [0|15] "SED"  SCMC

BO_ 2612224073 PARSEDPushRSMtoGWM_ECG: 8 RSM
 SG_ PARSEDPushRSMtoGWM_ECG : 7|29@0+ (1,0) [0|536870911] "unitless"  GWM

BO_ 1320 SCMF_Network_MgmtM: 8 SCMF
 SG_ SCMF_Network_Mgmt : 7|64@0+ (1,0) [0|1.84467440737096E+019] "Unitless"  GENERIC

BO_ 1319 SCME_Network_MgmtM: 8 SCME
 SG_ SCME_Network_Mgmt : 7|64@0+ (1,0) [0|1.84467440737096E+019] "unitless"  GENERIC

BO_ 1368 SCMB_PSM_Network_MgmtM: 8 SCMB_PSM
 SG_ SCMB_PSM_Network_Mgmt : 7|8@0+ (1,0) [0|254] "unitless"  GENERIC

BO_ 1339 RTM_Network_MgmtM: 8 RTM
 SG_ RTM_Network_Mgmt : 7|64@0+ (1,0) [0|1.84467440737096E+019] "unitless"  TRM,HVAC_RCCM,GENERIC

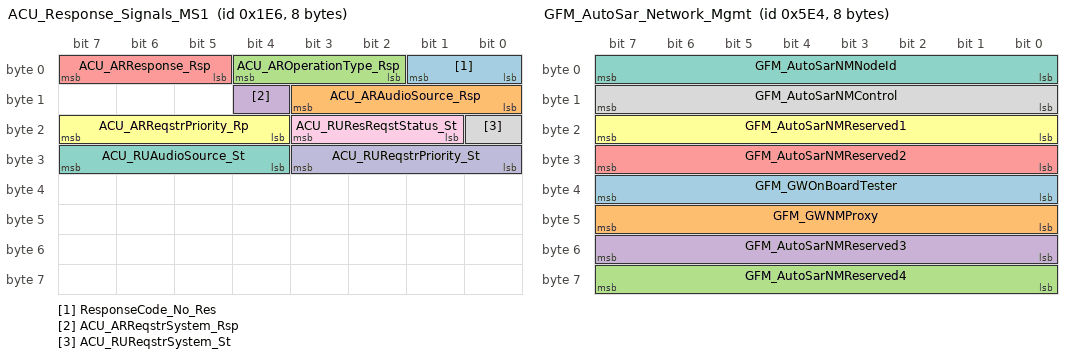
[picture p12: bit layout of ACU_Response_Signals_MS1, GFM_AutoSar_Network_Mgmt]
BO_ 486 ACU_Response_Signals_MS1: 8 GWM
 SG_ ResponseCode_No_Res : 1|2@0+ (1,0) [0|3] "SED" Vector__XXX
 SG_ ACU_ARAudioSource_Rsp : 11|4@0+ (1,0) [0|15] "SED"  FCIM
 SG_ ACU_AROperationType_Rsp : 4|3@0+ (1,0) [0|7] "SED"  FCIM
 SG_ ACU_ARReqstrSystem_Rsp : 12|1@0+ (1,0) [0|1] "SED"  FCIM
 SG_ ACU_ARResponse_Rsp : 7|3@0+ (1,0) [0|6] "SED"  FCIM
 SG_ ACU_ARReqstrPriority_Rp : 23|4@0+ (1,0) [0|15] "SED"  FCIM
 SG_ ACU_RUAudioSource_St : 31|4@0+ (1,0) [0|15] "SED"  FCIM
 SG_ ACU_RUReqstrSystem_St : 16|1@0+ (1,0) [0|1] "SED"  FCIM
 SG_ ACU_RUResReqstStatus_St : 19|3@0+ (1,0) [0|7] "SED"  FCIM
 SG_ ACU_RUReqstrPriority_St : 27|4@0+ (1,0) [0|15] "SED"  FCIM

BO_ 1383 RSM_Network_MgmtM: 8 RSM
 SG_ RSM_Network_Mgmt : 7|64@0+ (1,0) [0|1.84467440737096E+019] "unitless"  TRM,RTM,GENERIC

BO_ 2611175599 PARSEDPhysRGTMtoGWM_ECG: 8 RGTM
 SG_ PARSEDPhysRGTMtoGWM_ECG : 7|29@0+ (1,0) [0|536870911] "unitless"  GWM

BO_ 2612224175 PARSEDPushRGTMtoGWM_ECG: 8 RGTM
 SG_ PARSEDPushRGTMtoGWM_ECG : 7|29@0+ (1,0) [0|536870911] "unitless"  GWM

BO_ 1352 RHVAC_Network_MgmtM: 8 RHVAC
 SG_ RHVAC_Network_Mgmt : 7|64@0+ (1,0) [0|1.84467440737096E+019] "unitless"  GENERIC

BO_ 1318 RGTM_Network_MgmtM: 8 RGTM
 SG_ RGTM_Network_Mgmt : 7|8@0+ (1,0) [0|254] "unitless"  HVAC_RCCM,GENERIC

BO_ 2612224164 PARSEDPushPDMtoGWM_ECG: 8 PDM
 SG_ PARSEDPushPDMtoGWM_ECG : 7|29@0+ (1,0) [0|536870911] "unitless"  GWM

BO_ 2612170968 PARSEDPushFcGWM_ECGtoPDM: 8 GWM
 SG_ PARSEDPushFcGWM_ECGtoPDM : 7|29@0+ (1,0) [0|536870911] "unitless"  PDM

BO_ 2611122392 PARSEDPhysGWM_ECGtoPDM: 8 GWM
 SG_ PARSEDPhysGWM_ECGtoPDM : 7|29@0+ (1,0) [0|536870911] "unitless"  PDM

BO_ 2611118296 PARSEDPhysGWM_ECGtoDDM: 8 GWM
 SG_ PARSEDPhysGWM_ECGtoDDM : 7|29@0+ (1,0) [0|536870911] "unitless"  DDM

BO_ 2611175584 PARSEDPhysDDMtoGWM_ECG: 8 DDM
 SG_ PARSEDPhysDDMtoGWM_ECG : 7|29@0+ (1,0) [0|536870911] "unitless"  GWM

BO_ 2611175588 PARSEDPhysPDMtoGWM_ECG: 8 PDM
 SG_ PARSEDPhysPDMtoGWM_ECG : 7|29@0+ (1,0) [0|536870911] "Unitless"  GWM

BO_ 2610127012 OTAPhysPDMtoGWM_ECG: 8 PDM
 SG_ OTAPhysPDMtoGWM_ECG : 7|29@0+ (1,0) [0|536870911] "unitless"  GWM

BO_ 2610073816 OTAPhysGWM_ECGtoPDM: 8 GWM
 SG_ OTAPhysGWM_ECGtoPDM : 7|29@0+ (1,0) [0|536870911] "unitless"  PDM

BO_ 2610069720 OTAPhysGWM_ECGtoDDM: 8 GWM
 SG_ OTAPhysGWM_ECGtoDDM : 7|29@0+ (1,0) [0|536870911] "unitless"  DDM

BO_ 2610127008 OTAPhysDDMtoGWM_ECG: 8 DDM
 SG_ OTAPhysDDMtoGWM_ECG : 7|29@0+ (1,0) [0|536870911] "unitless"  GWM

BO_ 2612224160 PARSEDPushDDMtoGWM_ECG: 8 DDM
 SG_ PARSEDPushDDMtoGWM_ECG : 7|29@0+ (1,0) [0|536870911] "unitless"  GWM

BO_ 2612166872 PARSEDPushFcGWM_ECGtoDDM: 8 GWM
 SG_ PARSEDPushFcGWM_ECGtoDDM : 7|29@0+ (1,0) [0|536870911] "unitless"  DDM

BO_ 1508 GFM_AutoSar_Network_Mgmt: 8 GFM_FTRM
 SG_ GFM_GWOnBoardTester : 39|8@0+ (1,0) [0|255] "unitless"  GWM
 SG_ GFM_GWNMProxy : 47|8@0+ (1,0) [0|255] "unitless"  GWM
 SG_ GFM_AutoSarNMReserved4 : 63|8@0+ (1,0) [0|255] "unitless"  GWM
 SG_ GFM_AutoSarNMReserved3 : 55|8@0+ (1,0) [0|255] "unitless"  GWM
 SG_ GFM_AutoSarNMReserved2 : 31|8@0+ (1,0) [0|255] "unitless"  GWM
 SG_ GFM_AutoSarNMReserved1 : 23|8@0+ (1,0) [0|255] "unitless"  GWM
 SG_ GFM_AutoSarNMNodeId : 7|8@0+ (1,0) [0|255] "unitless"  GWM
 SG_ GFM_AutoSarNMControl : 15|8@0+ (1,0) [0|255] "unitless"  GWM

BO_ 930 Bndry_Alert_R_Data_MS1: 8 GWM
 SG_ BalrWndwRight_D_Confg : 18|2@0+ (1,0) [0|3] "SED"  GWM,SODL
 SG_ BalrWndwRight_B_Stat : 19|1@0+ (1,0) [0|1] "SED"  GWM
 SG_ BalrSnsRight_D_Falt : 21|2@0+ (1,0) [0|3] "SED"  GWM
 SG_ WndwPsngrRear_D_RqBalrr : 25|2@0+ (1,0) [0|3] "SED"  GWM,PDM
 SG_ WndwPsngr_D_RqBalrr : 27|2@0+ (1,0) [0|3] "SED"  GWM,PDM
 SG_ WndwDrvRear_D_RqBalrr : 29|2@0+ (1,0) [0|3] "SED"  GWM,PDM,DDM
 SG_ WndwDrv_D_RqBalrr : 31|2@0+ (1,0) [0|3] "SED"  GWM,PDM,DDM
 SG_ BalrRight_D_Stat : 10|2@0+ (1,0) [0|3] "SED"  GWM
 SG_ BalrMdeSelRight_B_Stat : 8|1@0+ (1,0) [0|1] "SED"  GWM,SODL
 SG_ BalrMdeRight_D_Stat : 23|2@0+ (1,0) [0|3] "SED"  GWM,SODL
 SG_ BalrLckRight_B_Stat : 11|1@0+ (1,0) [0|1] "SED"  GWM
 SG_ BalrLckRight_B_Confg : 0|1@0+ (1,0) [0|1] "SED"  GWM,SODL
 SG_ BalrInnrRight_D_Stat : 13|2@0+ (1,0) [0|3] "SED"  GWM,SODL
 SG_ BalrDfaltRight_D_Stat : 15|2@0+ (1,0) [0|3] "SED"  GWM,SODL
 SG_ BalrChimeRight_D_Rq : 2|2@0+ (1,0) [0|3] "SED"  GWM
 SG_ CamraRearOn_B_RqBalrr : 7|1@0+ (1,0) [0|1] "SED"  GWM
 SG_ DrLckCnt_No_ActlBalrr : 5|3@0+ (1,0) [0|7] "unitless"  GWM
 SG_ DrLckActv_B_RqBalrr : 6|1@0+ (1,0) [0|1] "SED"  GWM

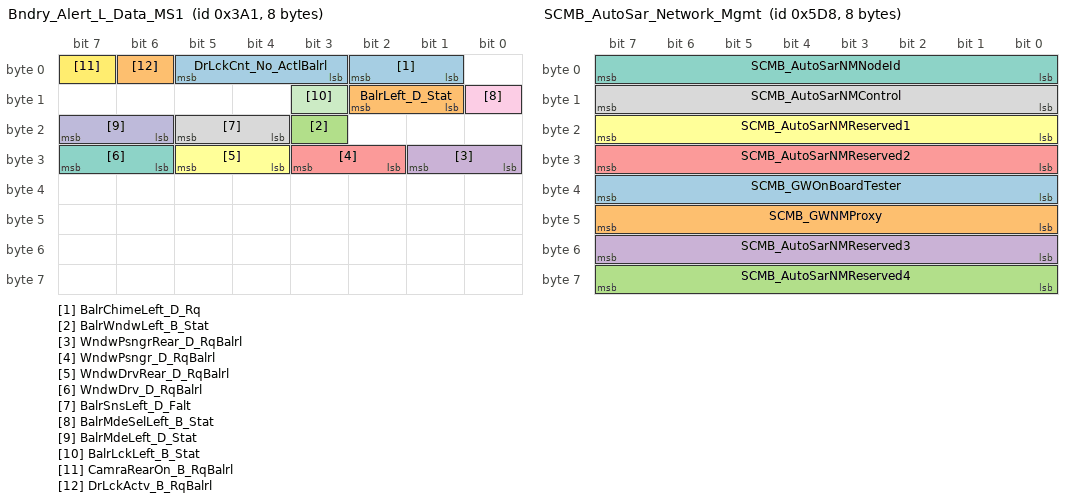
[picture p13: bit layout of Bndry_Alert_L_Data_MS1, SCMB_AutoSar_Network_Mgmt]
BO_ 929 Bndry_Alert_L_Data_MS1: 8 GWM
 SG_ BalrChimeLeft_D_Rq : 2|2@0+ (1,0) [0|3] "SED"  GWM
 SG_ BalrLeft_D_Stat : 10|2@0+ (1,0) [0|3] "SED"  GWM
 SG_ BalrWndwLeft_B_Stat : 19|1@0+ (1,0) [0|1] "SED"  GWM
 SG_ WndwPsngrRear_D_RqBalrl : 25|2@0+ (1,0) [0|3] "SED"  GWM,PDM
 SG_ WndwPsngr_D_RqBalrl : 27|2@0+ (1,0) [0|3] "SED"  GWM,PDM
 SG_ WndwDrvRear_D_RqBalrl : 29|2@0+ (1,0) [0|3] "SED"  GWM,DDM,PDM
 SG_ WndwDrv_D_RqBalrl : 31|2@0+ (1,0) [0|3] "SED"  GWM,DDM,PDM
 SG_ BalrSnsLeft_D_Falt : 21|2@0+ (1,0) [0|3] "SED"  GWM
 SG_ BalrMdeSelLeft_B_Stat : 8|1@0+ (1,0) [0|1] "SED"  GWM,SODR
 SG_ BalrMdeLeft_D_Stat : 23|2@0+ (1,0) [0|3] "SED"  GWM,SODR
 SG_ BalrLckLeft_B_Stat : 11|1@0+ (1,0) [0|1] "SED"  GWM
 SG_ CamraRearOn_B_RqBalrl : 7|1@0+ (1,0) [0|1] "SED"  GWM
 SG_ DrLckCnt_No_ActlBalrl : 5|3@0+ (1,0) [0|7] "unitless"  GWM
 SG_ DrLckActv_B_RqBalrl : 6|1@0+ (1,0) [0|1] "SED"  GWM

BO_ 1496 SCMB_AutoSar_Network_Mgmt: 8 SCMB_PSM
 SG_ SCMB_GWOnBoardTester : 39|8@0+ (1,0) [0|255] "unitless"  GWM
 SG_ SCMB_GWNMProxy : 47|8@0+ (1,0) [0|255] "unitless"  GWM
 SG_ SCMB_AutoSarNMReserved4 : 63|8@0+ (1,0) [0|255] "unitless"  GWM
 SG_ SCMB_AutoSarNMReserved3 : 55|8@0+ (1,0) [0|255] "unitless"  GWM
 SG_ SCMB_AutoSarNMReserved2 : 31|8@0+ (1,0) [0|255] "unitless"  GWM
 SG_ SCMB_AutoSarNMReserved1 : 23|8@0+ (1,0) [0|255] "unitless"  GWM
 SG_ SCMB_AutoSarNMNodeId : 7|8@0+ (1,0) [0|255] "unitless"  GWM
 SG_ SCMB_AutoSarNMControl : 15|8@0+ (1,0) [0|255] "unitless"  GWM

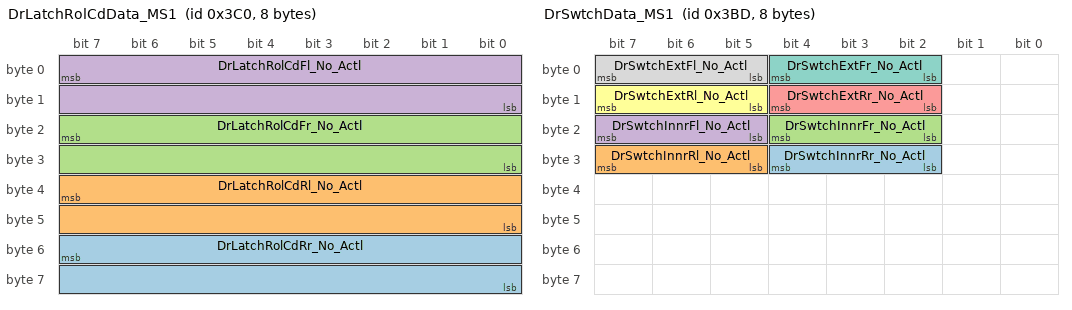
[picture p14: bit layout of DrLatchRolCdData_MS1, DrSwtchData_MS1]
BO_ 960 DrLatchRolCdData_MS1: 8 GWM
 SG_ DrLatchRolCdRr_No_Actl : 55|16@0+ (1,0) [0|65535] "unitless"  DCMH
 SG_ DrLatchRolCdRl_No_Actl : 39|16@0+ (1,0) [0|65535] "unitless"  DCMG
 SG_ DrLatchRolCdFr_No_Actl : 23|16@0+ (1,0) [0|65535] "unitless"  DCMF
 SG_ DrLatchRolCdFl_No_Actl : 7|16@0+ (1,0) [0|65535] "unitless"  DCME

BO_ 957 DrSwtchData_MS1: 8 GWM
 SG_ DrSwtchInnrRr_No_Actl : 28|3@0+ (1,0) [0|7] "unitless"  DCMH
 SG_ DrSwtchInnrRl_No_Actl : 31|3@0+ (1,0) [0|7] "unitless"  DCMG
 SG_ DrSwtchInnrFr_No_Actl : 20|3@0+ (1,0) [0|7] "unitless"  DCMF
 SG_ DrSwtchInnrFl_No_Actl : 23|3@0+ (1,0) [0|7] "unitless"  DCME
 SG_ DrSwtchExtRr_No_Actl : 12|3@0+ (1,0) [0|7] "unitless"  DCMH
 SG_ DrSwtchExtRl_No_Actl : 15|3@0+ (1,0) [0|7] "unitless"  DCMG
 SG_ DrSwtchExtFr_No_Actl : 4|3@0+ (1,0) [0|7] "unitless"  DCMF
 SG_ DrSwtchExtFl_No_Actl : 7|3@0+ (1,0) [0|7] "unitless"  DCME

BO_ 718 BEZEL_RDISP_WORD_Rx_MS1: 8 GWM
 SG_ BEZEL_RDISP_WORD_Rx : 7|64@0+ (1,0) [0|1.84467440737096E+019] "unitless"  FCIM,HVAC_RCCM

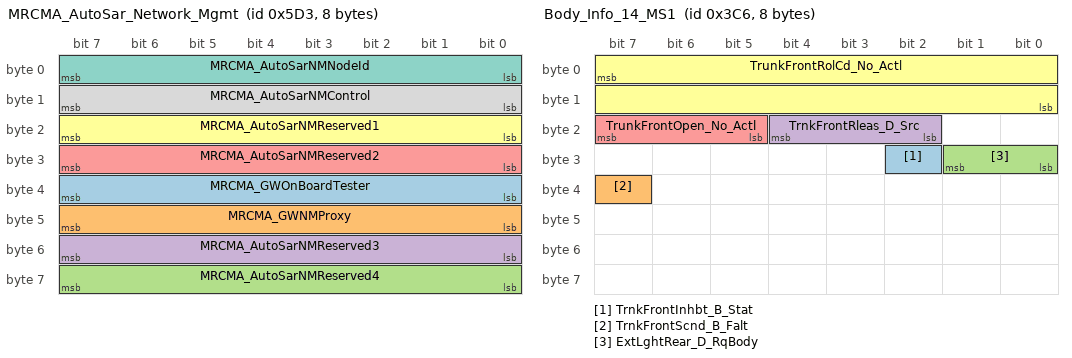
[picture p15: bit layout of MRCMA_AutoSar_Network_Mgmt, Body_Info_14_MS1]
BO_ 1491 MRCMA_AutoSar_Network_Mgmt: 8 MRCMA_RSCM
 SG_ MRCMA_GWOnBoardTester : 39|8@0+ (1,0) [0|255] "unitless"  GWM
 SG_ MRCMA_GWNMProxy : 47|8@0+ (1,0) [0|255] "unitless"  GWM
 SG_ MRCMA_AutoSarNMReserved4 : 63|8@0+ (1,0) [0|255] "unitless"  GWM
 SG_ MRCMA_AutoSarNMReserved3 : 55|8@0+ (1,0) [0|255] "unitless"  GWM
 SG_ MRCMA_AutoSarNMReserved2 : 31|8@0+ (1,0) [0|255] "unitless"  GWM
 SG_ MRCMA_AutoSarNMReserved1 : 23|8@0+ (1,0) [0|255] "unitless"  GWM
 SG_ MRCMA_AutoSarNMNodeId : 7|8@0+ (1,0) [0|255] "unitless"  GWM
 SG_ MRCMA_AutoSarNMControl : 15|8@0+ (1,0) [0|255] "unitless"  GWM

BO_ 847 PwrFoldSeats: 8 SCMJ
 SG_ FldngSeatPwOffOk_B_Stat : 7|1@0+ (1,0) [0|1] "SED"  GWM

BO_ 2609972440 OTAPhysGWM_ECGtoSCMJ: 8 GWM
 SG_ OTAPhysGWM_ECGtoSCMJ : 7|29@0+ (1,0) [0|536870911] "unitless"  SCMJ

BO_ 2612158680 PARSEDPushFcGWM_ECGtoHVAC: 8 GWM
 SG_ PARSEDPushFcGWM_ECGtoHVAC : 7|29@0+ (1,0) [0|536870911] "unitless"  HVAC_RCCM

BO_ 2612226264 PARSEDPushFcGWM_ECGtoRTM: 8 GWM
 SG_ PARSEDPushFcGWM_ECGtoRTM : 7|29@0+ (1,0) [0|536870911] "unitless"  RTM

BO_ 2612168920 PARSEDPushFcGWM_ECGtoDSM: 8 GWM
 SG_ PARSEDPushFcGWM_ECGtoDSM : 7|29@0+ (1,0) [0|536870911] "unitless"  DSM

BO_ 966 Body_Info_14_MS1: 8 GWM
 SG_ TrnkFrontInhbt_B_Stat : 26|1@0+ (1,0) [0|1] "SED"  GFM_FTRM
 SG_ TrnkFrontScnd_B_Falt : 39|1@0+ (1,0) [0|1] "SED"  GENERIC
 SG_ ExtLghtRear_D_RqBody : 25|2@0- (1,0) [0|3] "SED"  MRCMA_RSCM
 SG_ TrnkFrontRleas_D_Src : 20|3@0+ (1,0) [0|7] "SED"  GFM_FTRM
 SG_ TrunkFrontOpen_No_Actl : 23|3@0+ (1,0) [0|7] "unitless"  GFM_FTRM
 SG_ TrunkFrontRolCd_No_Actl : 7|16@0+ (1,0) [0|65535] "unitless"  GFM_FTRM

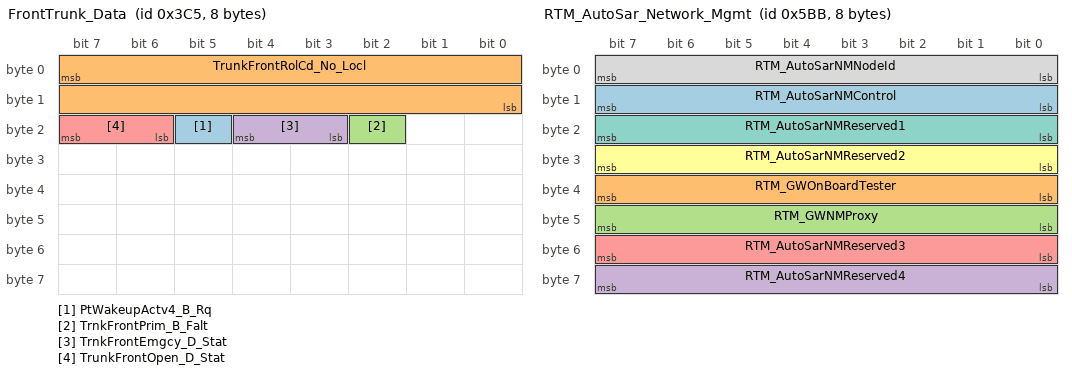
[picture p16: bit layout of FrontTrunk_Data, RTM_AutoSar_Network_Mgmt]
BO_ 965 FrontTrunk_Data: 8 GFM_FTRM
 SG_ PtWakeupActv4_B_Rq : 21|1@0+ (1,0) [0|1] "SED"  GWM
 SG_ TrunkFrontRolCd_No_Locl : 7|16@0+ (1,0) [0|65535] "unitless"  GWM
 SG_ TrnkFrontPrim_B_Falt : 18|1@0+ (1,0) [0|1] "SED"  GWM
 SG_ TrnkFrontEmgcy_D_Stat : 20|2@0+ (1,0) [0|0] "SED"  GWM
 SG_ TrunkFrontOpen_D_Stat : 23|2@0+ (1,0) [0|3] "SED"  GWM

BO_ 1467 RTM_AutoSar_Network_Mgmt: 8 RTM
 SG_ RTM_AutoSarNMControl : 15|8@0+ (1,0) [0|255] "unitless"  GENERIC
 SG_ RTM_GWOnBoardTester : 39|8@0+ (1,0) [0|255] "unitless"  GENERIC
 SG_ RTM_GWNMProxy : 47|8@0+ (1,0) [0|255] "unitless"  GENERIC
 SG_ RTM_AutoSarNMReserved4 : 63|8@0+ (1,0) [0|255] "unitless"  GENERIC
 SG_ RTM_AutoSarNMReserved3 : 55|8@0+ (1,0) [0|255] "unitless"  GENERIC
 SG_ RTM_AutoSarNMReserved2 : 31|8@0+ (1,0) [0|255] "unitless"  GENERIC
 SG_ RTM_AutoSarNMReserved1 : 23|8@0+ (1,0) [0|255] "unitless"  GENERIC
 SG_ RTM_AutoSarNMNodeId : 7|8@0+ (1,0) [0|255] "unitless"  GENERIC

BO_ 1869 TesterPhysicalResDASM: 8 DASM
 SG_ TesterPhysicalResDASM : 7|64@0+ (1,0) [0|1.84467E+019] "unitless"  TSTR

BO_TX_BU_ 672 : HVAC_RCCM,FCIM;

CM_ "FNV2 MS1 CAN";
CM_ BU_ BCMB_AUXM "Auxiliary Module";
CM_ BU_ FCIM "Front Control Interface Module";
CM_ BU_ MRCMA_RSCM "Roller Shutter Control Module";
CM_ BU_ SCMJ "New Power Folding Seat Module: MS1_SCMJ_PFSM";
CM_ BU_ BCMB_ALCM "ALCM (Auxiliary Lighting Control Module), lead 17P558";
CM_ BU_ SCMB_PSM "Passenger Seat Module (16U502)";
CM_ BU_ SCMD "Rear Passenger Multi-Contour Seat";
CM_ BU_ SCMC "Rear Driver Multi-Contour Seat";
CM_ BU_ HVAC_RCCM "Front Controls Interface Module (EFP: Electronic Finish Panel, Integrated HVAC)";
CM_ BU_ MRCMB "Convertible Top Slave";
CM_ BU_ MRCMA "Convertible Top Master";
CM_ BU_ DASM "Door Activation Switch Module";
CM_ BU_ GFM_FTRM "Front Trunk Release Module";
CM_ BU_ BCMB_CAPM "BCMB_CAPM(Column and Pedal Memory), lead D544";
CM_ BU_ DCMH "Door Control Module H (DLMRR: Door Latch Module - Right Rear)";
CM_ BU_ SFMB "Rear Passenger Multi Contour Seat Switch (RPCMSS)";
CM_ BU_ SFMA "Rear Driver Multi Contour Seat Switch (RDCMSS)";
CM_ BU_ SOBDMD_AHCM_FOH "MSCAN module Fuel Operated Heater";
CM_ BU_ TRM "Trailer Module";
CM_ BU_ GWM "Gateway Module CGEA1.3(Star Architecture)";
CM_ BU_ BCMB_ABM "ABM(Ancillary Body Module), lead S550";
CM_ BU_ SODL "Side Obstacle Detection Control Module - Left (Primary)";
CM_ BU_ SCMF "Passenger Climate Ctrl Seat Module (PCSM)";
CM_ BU_ RTM "Radio Transceiver Module(RFA,TPM)";
CM_ BU_ RHVAC "Rear HVAC Control Module (RCCM)";
CM_ BU_ PDM "Passenger Front Door Module ";
CM_ BU_ DCMG "Door Control Module G (DLMLR: Door Latch Module - Left Rear)";
CM_ BU_ DCMF "Door Control Module F (DLMRF: Door Latch Module - Right Front)";
CM_ BU_ DCME "Door Control Module E (DLMLF: Door Latch Module - Left Front)";
CM_ BU_ SCMH "Passenger Multi-Contour Seat (Massage)";
CM_ BU_ SCMG "Driver Multi-Contour Seat (Massage)";
CM_ BU_ HSWM "Heated Steering Wheel Module ";
CM_ BU_ RSM "Remote Start Module";
CM_ BU_ SODR "Side Obstacle Detection Control Module - Right

";
CM_ BU_ DDM "Driver Front Door Module, 2006 CD378 new module design";
CM_ BU_ RBM "Running Board Control Module, PRB (Power Running Board)";
CM_ BU_ RGTM "Rear Gate/Trunk Module, LTM (Lift-gate Trunk Module)";
CM_ BU_ DSM "SCMA (Driver Front Seat Module)";
CM_ BU_ SCME "Driver Climate Control Seat Module (DCSM)";
CM_ BU_ GENERIC "holding pattern ECU for developmental messages";
CM_ BU_ TSTR "Diagnostic Tester";
CM_ SG_ 612 SelDrvMdeSwtch_D_Stat6 "ECM_HEV does not support or Transmit signal.";
CM_ SG_ 773 MemSwtchPsngrFdbck_B_Rq "Updated to 1 bit for CGEA, Not backwards compatible";
CM_ SG_ 1417 SOBDMD_AutoSarNMReserved4 "Signal not transmitted on gas and diesel variants.";
CM_ SG_ 1417 SOBDMD_AutoSarNMReserved3 "Signal not transmitted on gas and diesel variants.";
CM_ SG_ 1417 SOBDMD_AutoSarNMReserved2 "Signal not transmitted on gas and diesel variants.";
CM_ SG_ 1417 SOBDMD_AutoSarNMReserved1 "Signal not transmitted on gas and diesel variants.";
CM_ SG_ 1417 SOBDMD_AutoSarNMNodeId "Signal not transmitted on gas and diesel variants.";
CM_ SG_ 1417 SOBDMD_AutoSarNMControl "Signal not transmitted on gas and diesel variants.";
CM_ SG_ 672 BCP_Audible_Beep_Rq "Object.AlertMethod.BCP_Audible_Beep";
CM_ SG_ 672 SetVolume "$0: -30Steps
$1: -29Steps
$2: -28Steps
$1D: -1Step
$1E: NotPressed_Inactive
$1F: +1Step
$20: +2Steps
$21: +3Steps
$3C: +30Steps";
CM_ SG_ 672 SetPointVolume "Method: EFP_Button_Press
0x0:Inactive
$0: Inactive
$1: No_Volume
$2: Volume_Step1
$3: Vol_Step2
$1F: Vol_Step30";
CM_ SG_ 672 Coding_BtnID_D "Object InputControlInterface ICI ButtonCoding_D
Object InputControlInterface ICI ButtonID_D";
CM_ SG_ 672 Coding_BtnID_C "Object InputControlInterface.ICI ButtonCoding_C
Object InputControlInterface.ICI ButtonID_C";
CM_ SG_ 672 Coding_BtnID_B "Object InputControlInterface ICI ButtonCoding_B
Object InputControlInterface.ICI ButtonID_B";
CM_ SG_ 672 Coding_BtnID_A "Object InputControlInterface ICI ButtonCoding_A
Object InputControlInterface.ICI ButtonID A";
CM_ SG_ 672 BtnID_D "Object InputControlInterface ICI ButtonID_D... 0xFF: Inactive";
CM_ SG_ 672 BtnID_C "Object InputControlInterface ICI ButtonID_D... 0xFF: Inactive";
CM_ SG_ 672 BtnID_B "Object InputControlInterface ICI ButtonID_D... 0xFF: Inactive";
CM_ SG_ 672 BtnID_A "Object InputControlInterface ICI ButtonID_D... 0xFF: Inactive";
CM_ BO_ 486 "ACM Tx";
CM_ SG_ 486 ACU_ARAudioSource_Rsp "Object Audio Management AudioClient.AudioRequest.Requested Audio Source";
CM_ SG_ 486 ACU_AROperationType_Rsp "Object Audio Management AudioClient.AudioRequest.Operation Type";
CM_ SG_ 486 ACU_ARReqstrSystem_Rsp "Object Audio Management AudioClient.AudioRequest.Requester System";
CM_ SG_ 486 ACU_ARResponse_Rsp "Object Audio Management AudioClient.AudioRequest.Response";
CM_ SG_ 486 ACU_ARReqstrPriority_Rp "AR = Audio Request (this signal belongs to the logical signal AudioRequest.Rsp)
Object = AudioClient
Logical Signal = AudioRequest
Parameter = Requester Priority

Disc shall be used for both CD and MC";
CM_ SG_ 486 ACU_RUAudioSource_St "Object Audio Management Audio Client.ResourceUpdate.Requested Audio Source
";
CM_ SG_ 486 ACU_RUReqstrSystem_St "Object Audio Management Audio Client.ResourceUpdate.Requester System";
CM_ SG_ 486 ACU_RUResReqstStatus_St "Object Audio Management Audio Client.ResourceUpdate.Resource Request Status";
CM_ SG_ 486 ACU_RUReqstrPriority_St "Object Audio Management Audio Client.ResourceUpdate.Requester Priority";
BA_DEF_ BO_  "FrameRouting" STRING ;
BA_DEF_ BO_  "FrameGatewayNetwork" STRING ;
BA_DEF_ BO_  "NetworkInitialization" ENUM  "No","Yes";
BA_DEF_ BO_  "FrameGatewayId" HEX 0 1407;
BA_DEF_ BO_  "EventRateOfChange" INT 10 10000;
BA_DEF_ BO_  "GenMsgStartDelayTime" INT 0 10000;
BA_DEF_ BO_  "GenMsgNrOfRepetition" INT 0 100;
BA_DEF_ BO_  "GenMsgDelayTime" INT 0 1000;
BA_DEF_ BO_  "GenMsgCycleTime" INT 0 100000;
BA_DEF_ BO_  "GenMsgSendType" ENUM  "FixedPeriodic","Event","EnabledPeriodic","NotUsed","NotUsed","EventPeriodic","NotUsed","NotUsed","NoMsgSendType";
BA_DEF_ SG_  "U_CD764_MY2022_Tx" ENUM  "No","Yes";
BA_DEF_ SG_  "U_U55X_MY2022_Tx" ENUM  "No","Yes";
BA_DEF_ SG_  "U_CD542_MY2021_Tx" ENUM  "No","Yes";
BA_DEF_ SG_  "ECGUsedTxSignal" ENUM  "No","Yes";
BA_DEF_ SG_  "U_T6_MCA_MY2020_Tx" ENUM  "No","Yes";
BA_DEF_ SG_  "U_P702_MY2021_Tx" ENUM  "No","Yes";
BA_DEF_ SG_  "U_CX727_MY2021_Tx" ENUM  "No","Yes";
BA_DEF_ SG_  "U_CD764_MY2022_Rx" ENUM  "No","Yes";
BA_DEF_ SG_  "U_U55X_MY2022_Rx" ENUM  "No","Yes";
BA_DEF_ SG_  "U_CD542_MY2021_Rx" ENUM  "No","Yes";
BA_DEF_ SG_  "ECGUsedRxSignal" ENUM  "No","Yes";
BA_DEF_ SG_  "U_T6_MCA_MY2020_Rx" ENUM  "No","Yes";
BA_DEF_ SG_  "U_P702_MY2021_Rx" ENUM  "No","Yes";
BA_DEF_ SG_  "U_CX727_MY2021_Rx" ENUM  "No","Yes";
BA_DEF_ SG_  "GenSigStartValue" HEX 0 268435455;
BA_DEF_ SG_  "MetaData" ENUM  "No","Yes";
BA_DEF_ SG_  "ContentDependant" ENUM  "No","Yes";
BA_DEF_ SG_  "GenSigStartValueInteger" INT 0 1000000000;
BA_DEF_ SG_  "UsedOnPgmDBC" ENUM  "No","Yes";
BA_DEF_ SG_  "WakeupSignal" ENUM  "No","Yes";
BA_DEF_ SG_  "GenSigInactiveValue" INT 0 100000;
BA_DEF_ SG_  "GenSigSendType" ENUM  "Cyclic","OnWrite","vector_leerstring","OnChange","vector_leerstring","IfActive","vector_leerstring","NoSigSendType";
BA_DEF_ BO_  "OvtpPushApplication" ENUM  "FALSE","TRUE";
BA_DEF_ BO_  "SCP_FreshnessValueLength" INT 0 512;
BA_DEF_ BO_  "SCP_FreshnessValueTxLength" INT 0 512;
BA_DEF_ BO_  "SCP_AuthInfoTxLength" INT 0 512;
BA_DEF_ BO_  "GenMsgRoutingTimeoutTime" INT 0 5000;
BA_DEF_ BO_  "MessageGateway" ENUM  "No","Yes";
BA_DEF_ BO_  "NmAsrMessage" ENUM  "No","Yes";
BA_DEF_ BO_  "DiagState" ENUM  "No","Yes";
BA_DEF_ BO_  "TpTxIndex" INT 0 536870911;
BA_DEF_ BO_  "DiagRequest" ENUM  "No","Yes";
BA_DEF_ BO_  "DiagResponse" ENUM  "No","Yes";
BA_DEF_ BO_  "NmMessage" ENUM  "No","Yes";
BA_DEF_ BO_  "GenMsgILSupport" ENUM  "No","Yes";
BA_DEF_ BU_  "OvtpOperationMode" ENUM  "SERVER","CLIENT";
BA_DEF_ BU_  "OvtpEcuAddress" INT 0 1022;
BA_DEF_ BU_  "ILUsed" ENUM  "No","Yes";
BA_DEF_ BU_  "Terminator" ENUM  "No","Yes";
BA_DEF_ BU_  "NodeWakeUpTime" INT 0 10000;
BA_DEF_ BU_  "NodeStartUpTime" INT 0 10000;
BA_DEF_ BU_  "NmAsrNodeIdentifier" HEX 0 255;
BA_DEF_ BU_  "NmAsrNode" ENUM  "No","Yes";
BA_DEF_ BU_  "PowerType" ENUM  "Switched","Latched","Sleep","vector_leerstring","vector_leerstring";
BA_DEF_ BU_  "DiagNode" ENUM  "GGDS","GDS","NONE";
BA_DEF_ BU_  "EOL_SB_Flash" ENUM  "GGDS","GDS","NONE","vector_leerstring";
BA_DEF_ BU_  "NmNode" ENUM  "No","Yes";
BA_DEF_ BU_  "NmStationAddress" INT 0 255;
BA_DEF_ BU_  "NosPackage" ENUM  "None","I3_1","I3_2","1.0.1","RP","EuCD","Volcano","I3_3","FNOS_Autosar";
BA_DEF_ BU_  "PackageID" STRING ;
BA_DEF_ BU_  "GatewayECU" ENUM  "No","Yes";
BA_DEF_  "NetworkSpeed" ENUM  "500kBits/s","125kBit/s";
BA_DEF_  "VersionNumber" INT 0 10000;
BA_DEF_  "StarNetworkGwType" ENUM  "0=NotDefined","1=HS1","2=HS2","3=HS3","4=HS4","5=HS5","6=MS1","7=HS6","8=HS7","9=MS2","10=FD1","11=FD2","12=FD3","13=FD4","14=FD5","15=FD6","16=FD7","17=FD8";
BA_DEF_  "CMDB_Version" STRING ;
BA_DEF_  "NmType" STRING ;
BA_DEF_  "NmAsrMessageCount" INT 128 256;
BA_DEF_  "NmAsrBaseAddress" HEX 1280 1408;
BA_DEF_  "DBName" STRING ;
BA_DEF_  "VersionDay" INT 1 31;
BA_DEF_  "Manufacturer" STRING ;
BA_DEF_  "VersionMonth" INT 1 12;
BA_DEF_  "VersionYear" INT 2000 3000;
BA_DEF_  "NmBaseAddress" HEX 1280 1280;
BA_DEF_  "NmMessageCount" INT 0 128;
BA_DEF_DEF_  "FrameRouting" "";
BA_DEF_DEF_  "FrameGatewayNetwork" "NONE";
BA_DEF_DEF_  "NetworkInitialization" "Yes";
BA_DEF_DEF_  "FrameGatewayId" 0;
BA_DEF_DEF_  "EventRateOfChange" 10000;
BA_DEF_DEF_  "GenMsgStartDelayTime" 0;
BA_DEF_DEF_  "GenMsgNrOfRepetition" 1;
BA_DEF_DEF_  "GenMsgDelayTime" 20;
BA_DEF_DEF_  "GenMsgCycleTime" 0;
BA_DEF_DEF_  "GenMsgSendType" "NoMsgSendType";
BA_DEF_DEF_  "U_CD764_MY2022_Tx" "No";
BA_DEF_DEF_  "U_U55X_MY2022_Tx" "No";
BA_DEF_DEF_  "U_CD542_MY2021_Tx" "No";
BA_DEF_DEF_  "ECGUsedTxSignal" "No";
BA_DEF_DEF_  "U_T6_MCA_MY2020_Tx" "No";
BA_DEF_DEF_  "U_P702_MY2021_Tx" "No";
BA_DEF_DEF_  "U_CX727_MY2021_Tx" "No";
BA_DEF_DEF_  "U_CD764_MY2022_Rx" "No";
BA_DEF_DEF_  "U_U55X_MY2022_Rx" "No";
BA_DEF_DEF_  "U_CD542_MY2021_Rx" "No";
BA_DEF_DEF_  "ECGUsedRxSignal" "No";
BA_DEF_DEF_  "U_T6_MCA_MY2020_Rx" "No";
BA_DEF_DEF_  "U_P702_MY2021_Rx" "No";
BA_DEF_DEF_  "U_CX727_MY2021_Rx" "No";
BA_DEF_DEF_  "GenSigStartValue" 0;
BA_DEF_DEF_  "MetaData" "No";
BA_DEF_DEF_  "ContentDependant" "No";
BA_DEF_DEF_  "GenSigStartValueInteger" 0;
BA_DEF_DEF_  "UsedOnPgmDBC" "Yes";
BA_DEF_DEF_  "WakeupSignal" "No";
BA_DEF_DEF_  "GenSigInactiveValue" 0;
BA_DEF_DEF_  "GenSigSendType" "NoSigSendType";
BA_DEF_DEF_  "OvtpPushApplication" "FALSE";
BA_DEF_DEF_  "SCP_FreshnessValueLength" 64;
BA_DEF_DEF_  "SCP_FreshnessValueTxLength" 11;
BA_DEF_DEF_  "SCP_AuthInfoTxLength" 53;
BA_DEF_DEF_  "GenMsgRoutingTimeoutTime" 0;
BA_DEF_DEF_  "MessageGateway" "No";
BA_DEF_DEF_  "NmAsrMessage" "No";
BA_DEF_DEF_  "DiagState" "No";
BA_DEF_DEF_  "TpTxIndex" 0;
BA_DEF_DEF_  "DiagRequest" "No";
BA_DEF_DEF_  "DiagResponse" "No";
BA_DEF_DEF_  "NmMessage" "No";
BA_DEF_DEF_  "GenMsgILSupport" "Yes";
BA_DEF_DEF_  "OvtpOperationMode" "SERVER";
BA_DEF_DEF_  "OvtpEcuAddress" 0;
BA_DEF_DEF_  "ILUsed" "Yes";
BA_DEF_DEF_  "Terminator" "No";
BA_DEF_DEF_  "NodeWakeUpTime" 100;
BA_DEF_DEF_  "NodeStartUpTime" 250;
BA_DEF_DEF_  "NmAsrNodeIdentifier" 128;
BA_DEF_DEF_  "NmAsrNode" "No";
BA_DEF_DEF_  "PowerType" "Switched";
BA_DEF_DEF_  "DiagNode" "GGDS";
BA_DEF_DEF_  "EOL_SB_Flash" "GGDS";
BA_DEF_DEF_  "NmNode" "No";
BA_DEF_DEF_  "NmStationAddress" 0;
BA_DEF_DEF_  "NosPackage" "I3_3";
BA_DEF_DEF_  "PackageID" "08.05.00.00.71.xx.xx.rr.00.00";
BA_DEF_DEF_  "GatewayECU" "No";
BA_DEF_DEF_  "NetworkSpeed" "500kBits/s";
BA_DEF_DEF_  "VersionNumber" 1;
BA_DEF_DEF_  "StarNetworkGwType" "0=NotDefined";
BA_DEF_DEF_  "CMDB_Version" "v11.01";
BA_DEF_DEF_  "NmType" "Ford-OSEK";
BA_DEF_DEF_  "NmAsrMessageCount" 128;
BA_DEF_DEF_  "NmAsrBaseAddress" 1408;
BA_DEF_DEF_  "DBName" "";
BA_DEF_DEF_  "VersionDay" 1;
BA_DEF_DEF_  "Manufacturer" "Ford";
BA_DEF_DEF_  "VersionMonth" 1;
BA_DEF_DEF_  "VersionYear" 2011;
BA_DEF_DEF_  "NmBaseAddress" 1280;
BA_DEF_DEF_  "NmMessageCount" 128;
BA_ "NetworkSpeed" 1;
BA_ "VersionNumber" 10;
BA_ "StarNetworkGwType" 6;
BA_ "CMDB_Version" "FNV2_v20.10";
BA_ "VersionDay" 11;
BA_ "VersionMonth" 9;
BA_ "VersionYear" 2020;
BA_ "DBName" "MS1_CAN";
BA_ "OvtpEcuAddress" BU_ BCMB_AUXM 83;
BA_ "NmAsrNodeIdentifier" BU_ BCMB_AUXM 209;
BA_ "NmAsrNode" BU_ BCMB_AUXM 1;
BA_ "PowerType" BU_ BCMB_AUXM 2;
BA_ "NmStationAddress" BU_ BCMB_AUXM 209;
BA_ "OvtpEcuAddress" BU_ FCIM 75;
BA_ "Terminator" BU_ FCIM 1;
BA_ "NmAsrNodeIdentifier" BU_ FCIM 221;
BA_ "NmAsrNode" BU_ FCIM 1;
BA_ "PowerType" BU_ FCIM 2;
BA_ "NmStationAddress" BU_ FCIM 93;
BA_ "OvtpEcuAddress" BU_ MRCMA_RSCM 184;
BA_ "NodeStartUpTime" BU_ MRCMA_RSCM 500;
BA_ "NmAsrNodeIdentifier" BU_ MRCMA_RSCM 211;
BA_ "NmAsrNode" BU_ MRCMA_RSCM 1;
BA_ "PowerType" BU_ MRCMA_RSCM 2;
BA_ "NmStationAddress" BU_ MRCMA_RSCM 83;
BA_ "OvtpEcuAddress" BU_ SCMJ 65;
BA_ "NodeWakeUpTime" BU_ SCMJ 250;
BA_ "NmAsrNodeIdentifier" BU_ SCMJ 234;
BA_ "NmAsrNode" BU_ SCMJ 1;
BA_ "PowerType" BU_ SCMJ 2;
BA_ "NmStationAddress" BU_ SCMJ 106;
BA_ "OvtpEcuAddress" BU_ BCMB_ALCM 83;
BA_ "NodeStartUpTime" BU_ BCMB_ALCM 1000;
BA_ "PowerType" BU_ BCMB_ALCM 2;
BA_ "NmNode" BU_ BCMB_ALCM 1;
BA_ "NmStationAddress" BU_ BCMB_ALCM 81;
BA_ "OvtpEcuAddress" BU_ SCMB_PSM 166;
BA_ "NodeWakeUpTime" BU_ SCMB_PSM 200;
BA_ "NodeStartUpTime" BU_ SCMB_PSM 200;
BA_ "PowerType" BU_ SCMB_PSM 2;
BA_ "NmNode" BU_ SCMB_PSM 1;
BA_ "NmStationAddress" BU_ SCMB_PSM 88;
BA_ "OvtpEcuAddress" BU_ SCMD 174;
BA_ "NodeStartUpTime" BU_ SCMD 1000;
BA_ "PowerType" BU_ SCMD 2;
BA_ "NmNode" BU_ SCMD 1;
BA_ "NmStationAddress" BU_ SCMD 105;
BA_ "OvtpEcuAddress" BU_ SCMC 170;
BA_ "NodeWakeUpTime" BU_ SCMC 20;
BA_ "NodeStartUpTime" BU_ SCMC 1000;
BA_ "PowerType" BU_ SCMC 2;
BA_ "NmNode" BU_ SCMC 1;
BA_ "NmStationAddress" BU_ SCMC 26;
BA_ "NosPackage" BU_ HVAC_RCCM 4;
BA_ "OvtpEcuAddress" BU_ HVAC_RCCM 152;
BA_ "Terminator" BU_ HVAC_RCCM 1;
BA_ "NmAsrNodeIdentifier" BU_ HVAC_RCCM 131;
BA_ "NmAsrNode" BU_ HVAC_RCCM 1;
BA_ "PowerType" BU_ HVAC_RCCM 2;
BA_ "NmStationAddress" BU_ HVAC_RCCM 3;
BA_ "OvtpEcuAddress" BU_ MRCMB 51;
BA_ "PowerType" BU_ MRCMB 2;
BA_ "NmNode" BU_ MRCMB 1;
BA_ "NmStationAddress" BU_ MRCMB 76;
BA_ "OvtpEcuAddress" BU_ MRCMA 184;
BA_ "PowerType" BU_ MRCMA 2;
BA_ "NmNode" BU_ MRCMA 1;
BA_ "NmStationAddress" BU_ MRCMA 83;
BA_ "OvtpEcuAddress" BU_ DASM 84;
BA_ "NmAsrNodeIdentifier" BU_ DASM 220;
BA_ "NmAsrNode" BU_ DASM 1;
BA_ "PowerType" BU_ DASM 2;
BA_ "NmStationAddress" BU_ DASM 92;
BA_ "OvtpEcuAddress" BU_ GFM_FTRM 37;
BA_ "NodeWakeUpTime" BU_ GFM_FTRM 150;
BA_ "NmAsrNodeIdentifier" BU_ GFM_FTRM 228;
BA_ "NmAsrNode" BU_ GFM_FTRM 1;
BA_ "PowerType" BU_ GFM_FTRM 2;
BA_ "NmStationAddress" BU_ GFM_FTRM 100;
BA_ "OvtpEcuAddress" BU_ BCMB_CAPM 83;
BA_ "PowerType" BU_ BCMB_CAPM 2;
BA_ "NmNode" BU_ BCMB_CAPM 1;
BA_ "NmStationAddress" BU_ BCMB_CAPM 81;
BA_ "OvtpEcuAddress" BU_ DCMH 60;
BA_ "NodeWakeUpTime" BU_ DCMH 30;
BA_ "NmAsrNodeIdentifier" BU_ DCMH 130;
BA_ "NmAsrNode" BU_ DCMH 1;
BA_ "PowerType" BU_ DCMH 2;
BA_ "NmStationAddress" BU_ DCMH 2;
BA_ "OvtpEcuAddress" BU_ SFMB 54;
BA_ "NmNode" BU_ SFMB 1;
BA_ "NmStationAddress" BU_ SFMB 114;
BA_ "OvtpEcuAddress" BU_ SFMA 53;
BA_ "NmNode" BU_ SFMA 1;
BA_ "NmStationAddress" BU_ SFMA 113;
BA_ "OvtpEcuAddress" BU_ SOBDMD_AHCM_FOH 15;
BA_ "NodeWakeUpTime" BU_ SOBDMD_AHCM_FOH 150;
BA_ "NodeStartUpTime" BU_ SOBDMD_AHCM_FOH 1000;
BA_ "NmAsrNodeIdentifier" BU_ SOBDMD_AHCM_FOH 137;
BA_ "NmAsrNode" BU_ SOBDMD_AHCM_FOH 1;
BA_ "PowerType" BU_ SOBDMD_AHCM_FOH 2;
BA_ "NmNode" BU_ SOBDMD_AHCM_FOH 1;
BA_ "NmStationAddress" BU_ SOBDMD_AHCM_FOH 9;
BA_ "OvtpEcuAddress" BU_ TRM 36;
BA_ "NodeWakeUpTime" BU_ TRM 35;
BA_ "NodeStartUpTime" BU_ TRM 1000;
BA_ "PowerType" BU_ TRM 2;
BA_ "NmNode" BU_ TRM 1;
BA_ "NmStationAddress" BU_ TRM 84;
BA_ "NosPackage" BU_ GWM 4;
BA_ "GatewayECU" BU_ GWM 1;
BA_ "OvtpOperationMode" BU_ GWM 1;
BA_ "OvtpEcuAddress" BU_ GWM 216;
BA_ "Terminator" BU_ GWM 1;
BA_ "NodeStartUpTime" BU_ GWM 100;
BA_ "NmAsrNodeIdentifier" BU_ GWM 158;
BA_ "NmAsrNode" BU_ GWM 1;
BA_ "PowerType" BU_ GWM 2;
BA_ "NmNode" BU_ GWM 1;
BA_ "NmStationAddress" BU_ GWM 30;
BA_ "OvtpEcuAddress" BU_ BCMB_ABM 83;
BA_ "NodeStartUpTime" BU_ BCMB_ABM 1000;
BA_ "PowerType" BU_ BCMB_ABM 2;
BA_ "NmNode" BU_ BCMB_ABM 1;
BA_ "NmStationAddress" BU_ BCMB_ABM 81;
BA_ "OvtpEcuAddress" BU_ SODL 98;
BA_ "NodeStartUpTime" BU_ SODL 620;
BA_ "NmStationAddress" BU_ SODL 106;
BA_ "OvtpEcuAddress" BU_ SCMF 157;
BA_ "NodeWakeUpTime" BU_ SCMF 200;
BA_ "NodeStartUpTime" BU_ SCMF 200;
BA_ "NmAsrNodeIdentifier" BU_ SCMF 168;
BA_ "NmAsrNode" BU_ SCMF 1;
BA_ "PowerType" BU_ SCMF 2;
BA_ "NmNode" BU_ SCMF 1;
BA_ "NmStationAddress" BU_ SCMF 40;
BA_ "OvtpEcuAddress" BU_ RTM 218;
BA_ "NodeWakeUpTime" BU_ RTM 25;
BA_ "NodeStartUpTime" BU_ RTM 1000;
BA_ "NmAsrNodeIdentifier" BU_ RTM 187;
BA_ "NmAsrNode" BU_ RTM 1;
BA_ "PowerType" BU_ RTM 2;
BA_ "NmStationAddress" BU_ RTM 59;
BA_ "OvtpEcuAddress" BU_ RHVAC 153;
BA_ "NmAsrNodeIdentifier" BU_ RHVAC 200;
BA_ "NmAsrNode" BU_ RHVAC 1;
BA_ "PowerType" BU_ RHVAC 2;
BA_ "NmNode" BU_ RHVAC 1;
BA_ "NmStationAddress" BU_ RHVAC 72;
BA_ "OvtpEcuAddress" BU_ PDM 164;
BA_ "NodeWakeUpTime" BU_ PDM 200;
BA_ "NodeStartUpTime" BU_ PDM 1000;
BA_ "NmAsrNodeIdentifier" BU_ PDM 133;
BA_ "NmAsrNode" BU_ PDM 1;
BA_ "PowerType" BU_ PDM 2;
BA_ "NmStationAddress" BU_ PDM 5;
BA_ "OvtpEcuAddress" BU_ DCMG 59;
BA_ "NodeWakeUpTime" BU_ DCMG 30;
BA_ "NmAsrNodeIdentifier" BU_ DCMG 217;
BA_ "NmAsrNode" BU_ DCMG 1;
BA_ "PowerType" BU_ DCMG 2;
BA_ "NmStationAddress" BU_ DCMG 89;
BA_ "OvtpEcuAddress" BU_ DCMF 57;
BA_ "NodeWakeUpTime" BU_ DCMF 30;
BA_ "NmAsrNodeIdentifier" BU_ DCMF 153;
BA_ "NmAsrNode" BU_ DCMF 1;
BA_ "PowerType" BU_ DCMF 2;
BA_ "NmStationAddress" BU_ DCMF 25;
BA_ "OvtpEcuAddress" BU_ DCME 55;
BA_ "NodeWakeUpTime" BU_ DCME 30;
BA_ "NmAsrNodeIdentifier" BU_ DCME 222;
BA_ "NmAsrNode" BU_ DCME 1;
BA_ "PowerType" BU_ DCME 2;
BA_ "NmStationAddress" BU_ DCME 94;
BA_ "OvtpEcuAddress" BU_ SCMH 159;
BA_ "NodeStartUpTime" BU_ SCMH 1000;
BA_ "NmStationAddress" BU_ SCMH 44;
BA_ "OvtpEcuAddress" BU_ SCMG 158;
BA_ "NodeStartUpTime" BU_ SCMG 1000;
BA_ "NmStationAddress" BU_ SCMG 43;
BA_ "OvtpEcuAddress" BU_ HSWM 23;
BA_ "NmStationAddress" BU_ HSWM 86;
BA_ "OvtpEcuAddress" BU_ RSM 73;
BA_ "NodeWakeUpTime" BU_ RSM 20;
BA_ "NodeStartUpTime" BU_ RSM 4500;
BA_ "PowerType" BU_ RSM 2;
BA_ "NmNode" BU_ RSM 1;
BA_ "NmStationAddress" BU_ RSM 103;
BA_ "OvtpEcuAddress" BU_ SODR 99;
BA_ "NodeStartUpTime" BU_ SODR 620;
BA_ "NmStationAddress" BU_ SODR 107;
BA_ "OvtpEcuAddress" BU_ DDM 160;
BA_ "NodeWakeUpTime" BU_ DDM 200;
BA_ "NodeStartUpTime" BU_ DDM 1000;
BA_ "NmAsrNodeIdentifier" BU_ DDM 132;
BA_ "NmAsrNode" BU_ DDM 1;
BA_ "PowerType" BU_ DDM 2;
BA_ "NmStationAddress" BU_ DDM 4;
BA_ "OvtpEcuAddress" BU_ RBM 186;
BA_ "NodeWakeUpTime" BU_ RBM 50;
BA_ "NodeStartUpTime" BU_ RBM 500;
BA_ "PowerType" BU_ RBM 2;
BA_ "NmNode" BU_ RBM 1;
BA_ "NmStationAddress" BU_ RBM 69;
BA_ "OvtpEcuAddress" BU_ RGTM 175;
BA_ "NodeStartUpTime" BU_ RGTM 500;
BA_ "NmAsrNodeIdentifier" BU_ RGTM 166;
BA_ "NmAsrNode" BU_ RGTM 1;
BA_ "PowerType" BU_ RGTM 2;
BA_ "NmNode" BU_ RGTM 1;
BA_ "NmStationAddress" BU_ RGTM 38;
BA_ "OvtpEcuAddress" BU_ DSM 162;
BA_ "NodeWakeUpTime" BU_ DSM 200;
BA_ "NodeStartUpTime" BU_ DSM 200;
BA_ "NmAsrNodeIdentifier" BU_ DSM 139;
BA_ "NmAsrNode" BU_ DSM 1;
BA_ "PowerType" BU_ DSM 2;
BA_ "NmStationAddress" BU_ DSM 11;
BA_ "OvtpEcuAddress" BU_ SCME 156;
BA_ "NodeWakeUpTime" BU_ SCME 200;
BA_ "NodeStartUpTime" BU_ SCME 200;
BA_ "NmAsrNodeIdentifier" BU_ SCME 167;
BA_ "NmAsrNode" BU_ SCME 1;
BA_ "PowerType" BU_ SCME 2;
BA_ "NmNode" BU_ SCME 1;
BA_ "NmStationAddress" BU_ SCME 39;
BA_ "NodeStartUpTime" BU_ GENERIC 1000;
BA_ "PowerType" BU_ GENERIC 2;
BA_ "NodeStartUpTime" BU_ TSTR 1000;
BA_ "PowerType" BU_ TSTR 2;
BA_ "GenMsgCycleTime" BO_ 612 1000;
BA_ "GenMsgSendType" BO_ 612 5;
BA_ "NetworkInitialization" BO_ 1489 0;
BA_ "GenMsgCycleTime" BO_ 1489 1000;
BA_ "GenMsgSendType" BO_ 1489 0;
BA_ "NmAsrMessage" BO_ 1489 1;
BA_ "GenMsgILSupport" BO_ 1489 0;
BA_ "GenMsgCycleTime" BO_ 1017 1000;
BA_ "GenMsgSendType" BO_ 1017 5;
BA_ "FrameRouting" BO_ 303 "HS1_CAN,0x12F;";
BA_ "FrameGatewayNetwork" BO_ 303 "HS1_CAN";
BA_ "FrameGatewayId" BO_ 303 303;
BA_ "GenMsgDelayTime" BO_ 2611021016 0;
BA_ "GenMsgSendType" BO_ 2611021016 1;
BA_ "TpTxIndex" BO_ 2611021016 463537368;
BA_ "GenMsgCycleTime" BO_ 1480 1000;
BA_ "GenMsgSendType" BO_ 1480 0;
BA_ "NmAsrMessage" BO_ 1480 1;
BA_ "GenMsgILSupport" BO_ 1480 0;
BA_ "GenMsgCycleTime" BO_ 1015 1000;
BA_ "GenMsgSendType" BO_ 1015 5;
BA_ "GenMsgCycleTime" BO_ 1067 250;
BA_ "GenMsgSendType" BO_ 1067 0;
BA_ "NetworkInitialization" BO_ 2612191448 0;
BA_ "GenMsgDelayTime" BO_ 2612191448 0;
BA_ "GenMsgSendType" BO_ 2612191448 1;
BA_ "OvtpPushApplication" BO_ 2612191448 1;
BA_ "TpTxIndex" BO_ 2612191448 464707800;
BA_ "NetworkInitialization" BO_ 2612224184 0;
BA_ "GenMsgDelayTime" BO_ 2612224184 0;
BA_ "GenMsgSendType" BO_ 2612224184 1;
BA_ "OvtpPushApplication" BO_ 2612224184 1;
BA_ "TpTxIndex" BO_ 2612224184 464707800;
BA_ "NetworkInitialization" BO_ 2611142872 0;
BA_ "GenMsgDelayTime" BO_ 2611142872 0;
BA_ "GenMsgSendType" BO_ 2611142872 1;
BA_ "TpTxIndex" BO_ 2611142872 463659224;
BA_ "NetworkInitialization" BO_ 2611175608 0;
BA_ "GenMsgDelayTime" BO_ 2611175608 0;
BA_ "GenMsgSendType" BO_ 2611175608 1;
BA_ "TpTxIndex" BO_ 2611175608 463659224;
BA_ "GenMsgCycleTime" BO_ 1080 1000;
BA_ "GenMsgSendType" BO_ 1080 5;
BA_ "NetworkInitialization" BO_ 2610094296 0;
BA_ "GenMsgDelayTime" BO_ 2610094296 0;
BA_ "GenMsgSendType" BO_ 2610094296 1;
BA_ "TpTxIndex" BO_ 2610094296 462610648;
BA_ "NetworkInitialization" BO_ 2610127032 0;
BA_ "GenMsgDelayTime" BO_ 2610127032 0;
BA_ "GenMsgSendType" BO_ 2610127032 1;
BA_ "TpTxIndex" BO_ 2610127032 462610648;
BA_ "GenMsgCycleTime" BO_ 1257 50;
BA_ "GenMsgSendType" BO_ 1257 0;
BA_ "GenMsgCycleTime" BO_ 1256 50;
BA_ "GenMsgSendType" BO_ 1256 0;
BA_ "NetworkInitialization" BO_ 2610085080 0;
BA_ "GenMsgDelayTime" BO_ 2610085080 0;
BA_ "GenMsgSendType" BO_ 2610085080 1;
BA_ "TpTxIndex" BO_ 2610085080 462601432;
BA_ "NetworkInitialization" BO_ 2611133656 0;
BA_ "GenMsgDelayTime" BO_ 2611133656 0;
BA_ "GenMsgSendType" BO_ 2611133656 1;
BA_ "TpTxIndex" BO_ 2611133656 463650008;
BA_ "NetworkInitialization" BO_ 2612182232 0;
BA_ "GenMsgDelayTime" BO_ 2612182232 0;
BA_ "GenMsgSendType" BO_ 2612182232 1;
BA_ "OvtpPushApplication" BO_ 2612182232 1;
BA_ "TpTxIndex" BO_ 2612182232 464698584;
BA_ "FrameRouting" BO_ 915 "FD1_CAN,0x393;";
BA_ "FrameGatewayNetwork" BO_ 915 "FD1_CAN";
BA_ "FrameGatewayId" BO_ 915 915;
BA_ "GenMsgCycleTime" BO_ 914 160;
BA_ "GenMsgSendType" BO_ 914 0;
BA_ "GenMsgCycleTime" BO_ 913 160;
BA_ "GenMsgSendType" BO_ 913 0;
BA_ "GenMsgCycleTime" BO_ 877 1000;
BA_ "GenMsgSendType" BO_ 877 5;
BA_ "FrameRouting" BO_ 918 "FD1_CAN,0x396;";
BA_ "FrameGatewayNetwork" BO_ 918 "FD1_CAN";
BA_ "FrameGatewayId" BO_ 918 918;
BA_ "FrameRouting" BO_ 917 "FD1_CAN,0x395;";
BA_ "FrameGatewayNetwork" BO_ 917 "FD1_CAN";
BA_ "FrameGatewayId" BO_ 917 917;
BA_ "GenMsgCycleTime" BO_ 773 1000;
BA_ "GenMsgSendType" BO_ 773 5;
BA_ "FrameRouting" BO_ 878 "HS3_CAN,0x36E;";
BA_ "FrameGatewayNetwork" BO_ 878 "HS3_CAN";
BA_ "FrameGatewayId" BO_ 878 878;
BA_ "NetworkInitialization" BO_ 1448 0;
BA_ "GenMsgCycleTime" BO_ 1448 1000;
BA_ "GenMsgSendType" BO_ 1448 0;
BA_ "NmAsrMessage" BO_ 1448 1;
BA_ "GenMsgILSupport" BO_ 1448 0;
BA_ "NetworkInitialization" BO_ 1447 0;
BA_ "GenMsgCycleTime" BO_ 1447 1000;
BA_ "GenMsgSendType" BO_ 1447 0;
BA_ "NmAsrMessage" BO_ 1447 1;
BA_ "GenMsgILSupport" BO_ 1447 0;
BA_ "NetworkInitialization" BO_ 1419 0;
BA_ "GenMsgCycleTime" BO_ 1419 1000;
BA_ "GenMsgSendType" BO_ 1419 0;
BA_ "NmAsrMessage" BO_ 1419 1;
BA_ "GenMsgILSupport" BO_ 1419 0;
BA_ "FrameRouting" BO_ 1247 "HS1_CAN,0x4DF;";
BA_ "FrameGatewayNetwork" BO_ 1247 "HS1_CAN";
BA_ "FrameGatewayId" BO_ 1247 1247;
BA_ "NetworkInitialization" BO_ 1417 0;
BA_ "GenMsgCycleTime" BO_ 1417 1000;
BA_ "GenMsgSendType" BO_ 1417 0;
BA_ "NmAsrMessage" BO_ 1417 1;
BA_ "GenMsgILSupport" BO_ 1417 0;
BA_ "GenMsgCycleTime" BO_ 672 1000;
BA_ "GenMsgSendType" BO_ 672 5;
BA_ "FrameRouting" BO_ 796 "HS1_CAN,0x43C;";
BA_ "FrameGatewayNetwork" BO_ 796 "HS1_CAN";
BA_ "FrameGatewayId" BO_ 796 1084;
BA_ "NetworkInitialization" BO_ 2610127023 0;
BA_ "GenMsgDelayTime" BO_ 2610127023 0;
BA_ "GenMsgSendType" BO_ 2610127023 1;
BA_ "TpTxIndex" BO_ 2610127023 462601432;
BA_ "NetworkInitialization" BO_ 2612077784 0;
BA_ "GenMsgDelayTime" BO_ 2612077784 0;
BA_ "GenMsgSendType" BO_ 2612077784 1;
BA_ "OvtpPushApplication" BO_ 2612077784 1;
BA_ "TpTxIndex" BO_ 2612077784 464594136;
BA_ "NetworkInitialization" BO_ 2611175497 0;
BA_ "GenMsgDelayTime" BO_ 2611175497 0;
BA_ "GenMsgSendType" BO_ 2611175497 1;
BA_ "TpTxIndex" BO_ 2611175497 463545560;
BA_ "NetworkInitialization" BO_ 2611029208 0;
BA_ "GenMsgDelayTime" BO_ 2611029208 0;
BA_ "GenMsgSendType" BO_ 2611029208 1;
BA_ "TpTxIndex" BO_ 2611029208 463545560;
BA_ "GenMsgSendType" BO_ 1364 1;
BA_ "NmMessage" BO_ 1364 1;
BA_ "GenMsgILSupport" BO_ 1364 0;
BA_ "NetworkInitialization" BO_ 2610126921 0;
BA_ "GenMsgDelayTime" BO_ 2610126921 0;
BA_ "GenMsgSendType" BO_ 2610126921 1;
BA_ "TpTxIndex" BO_ 2610126921 462496984;
BA_ "NetworkInitialization" BO_ 2609980632 0;
BA_ "GenMsgDelayTime" BO_ 2609980632 0;
BA_ "GenMsgSendType" BO_ 2609980632 1;
BA_ "TpTxIndex" BO_ 2609980632 462496984;
BA_ "FrameRouting" BO_ 677 "HS3_CAN,0x2A5;";
BA_ "FrameGatewayNetwork" BO_ 677 "HS3_CAN";
BA_ "FrameGatewayId" BO_ 677 677;
BA_ "NetworkInitialization" BO_ 2612224073 0;
BA_ "GenMsgDelayTime" BO_ 2612224073 0;
BA_ "GenMsgSendType" BO_ 2612224073 1;
BA_ "OvtpPushApplication" BO_ 2612224073 1;
BA_ "TpTxIndex" BO_ 2612224073 464594136;
BA_ "GenMsgSendType" BO_ 1320 1;
BA_ "NmMessage" BO_ 1320 1;
BA_ "GenMsgILSupport" BO_ 1320 0;
BA_ "GenMsgSendType" BO_ 1319 1;
BA_ "NmMessage" BO_ 1319 1;
BA_ "GenMsgILSupport" BO_ 1319 0;
BA_ "GenMsgDelayTime" BO_ 1368 0;
BA_ "GenMsgSendType" BO_ 1368 1;
BA_ "NmMessage" BO_ 1368 1;
BA_ "GenMsgILSupport" BO_ 1368 0;
BA_ "GenMsgSendType" BO_ 1339 1;
BA_ "NmMessage" BO_ 1339 1;
BA_ "GenMsgILSupport" BO_ 1339 0;
BA_ "FrameRouting" BO_ 486 "HS3_CAN,0x1E6;";
BA_ "FrameGatewayNetwork" BO_ 486 "HS3_CAN";
BA_ "FrameGatewayId" BO_ 486 486;
BA_ "GenMsgSendType" BO_ 1383 1;
BA_ "NmMessage" BO_ 1383 1;
BA_ "GenMsgILSupport" BO_ 1383 0;
BA_ "NetworkInitialization" BO_ 2611175599 0;
BA_ "GenMsgDelayTime" BO_ 2611175599 0;
BA_ "GenMsgSendType" BO_ 2611175599 1;
BA_ "TpTxIndex" BO_ 2611175599 463650008;
BA_ "NetworkInitialization" BO_ 2612224175 0;
BA_ "GenMsgDelayTime" BO_ 2612224175 0;
BA_ "GenMsgSendType" BO_ 2612224175 1;
BA_ "OvtpPushApplication" BO_ 2612224175 1;
BA_ "TpTxIndex" BO_ 2612224175 464698584;
BA_ "GenMsgSendType" BO_ 1352 1;
BA_ "NmMessage" BO_ 1352 1;
BA_ "GenMsgILSupport" BO_ 1352 0;
BA_ "GenMsgSendType" BO_ 1318 1;
BA_ "NmMessage" BO_ 1318 1;
BA_ "GenMsgILSupport" BO_ 1318 0;
BA_ "NetworkInitialization" BO_ 2612224164 0;
BA_ "GenMsgSendType" BO_ 2612224164 1;
BA_ "OvtpPushApplication" BO_ 2612224164 1;
BA_ "TpTxIndex" BO_ 2612224164 464687320;
BA_ "NetworkInitialization" BO_ 2612170968 0;
BA_ "GenMsgDelayTime" BO_ 2612170968 0;
BA_ "GenMsgSendType" BO_ 2612170968 1;
BA_ "OvtpPushApplication" BO_ 2612170968 1;
BA_ "TpTxIndex" BO_ 2612170968 464687320;
BA_ "NetworkInitialization" BO_ 2611122392 0;
BA_ "GenMsgDelayTime" BO_ 2611122392 0;
BA_ "GenMsgSendType" BO_ 2611122392 1;
BA_ "TpTxIndex" BO_ 2611122392 463638744;
BA_ "NetworkInitialization" BO_ 2611118296 0;
BA_ "GenMsgDelayTime" BO_ 2611118296 0;
BA_ "GenMsgSendType" BO_ 2611118296 1;
BA_ "TpTxIndex" BO_ 2611118296 463634648;
BA_ "NetworkInitialization" BO_ 2611175584 0;
BA_ "GenMsgDelayTime" BO_ 2611175584 0;
BA_ "GenMsgSendType" BO_ 2611175584 1;
BA_ "TpTxIndex" BO_ 2611175584 463634648;
BA_ "NetworkInitialization" BO_ 2611175588 0;
BA_ "GenMsgDelayTime" BO_ 2611175588 0;
BA_ "GenMsgSendType" BO_ 2611175588 1;
BA_ "TpTxIndex" BO_ 2611175588 463638744;
BA_ "NetworkInitialization" BO_ 2610127012 0;
BA_ "GenMsgDelayTime" BO_ 2610127012 0;
BA_ "GenMsgSendType" BO_ 2610127012 1;
BA_ "TpTxIndex" BO_ 2610127012 462590168;
BA_ "NetworkInitialization" BO_ 2610073816 0;
BA_ "GenMsgDelayTime" BO_ 2610073816 0;
BA_ "GenMsgSendType" BO_ 2610073816 1;
BA_ "TpTxIndex" BO_ 2610073816 462590168;
BA_ "NetworkInitialization" BO_ 2610069720 0;
BA_ "GenMsgDelayTime" BO_ 2610069720 0;
BA_ "GenMsgSendType" BO_ 2610069720 1;
BA_ "TpTxIndex" BO_ 2610069720 462586072;
BA_ "NetworkInitialization" BO_ 2610127008 0;
BA_ "GenMsgDelayTime" BO_ 2610127008 0;
BA_ "GenMsgSendType" BO_ 2610127008 1;
BA_ "TpTxIndex" BO_ 2610127008 462586072;
BA_ "NetworkInitialization" BO_ 2612224160 0;
BA_ "GenMsgDelayTime" BO_ 2612224160 0;
BA_ "GenMsgSendType" BO_ 2612224160 1;
BA_ "OvtpPushApplication" BO_ 2612224160 1;
BA_ "TpTxIndex" BO_ 2612224160 464683224;
BA_ "NetworkInitialization" BO_ 2612166872 0;
BA_ "GenMsgDelayTime" BO_ 2612166872 0;
BA_ "GenMsgSendType" BO_ 2612166872 1;
BA_ "OvtpPushApplication" BO_ 2612166872 1;
BA_ "TpTxIndex" BO_ 2612166872 464683224;
BA_ "NetworkInitialization" BO_ 1508 0;
BA_ "GenMsgCycleTime" BO_ 1508 1000;
BA_ "GenMsgSendType" BO_ 1508 0;
BA_ "NmAsrMessage" BO_ 1508 1;
BA_ "GenMsgILSupport" BO_ 1508 0;
BA_ "FrameRouting" BO_ 930 "FD1_CAN,0x3A2;";
BA_ "FrameGatewayNetwork" BO_ 930 "FD1_CAN";
BA_ "FrameGatewayId" BO_ 930 930;
BA_ "FrameRouting" BO_ 929 "FD1_CAN,0x3A1;";
BA_ "FrameGatewayNetwork" BO_ 929 "FD1_CAN";
BA_ "FrameGatewayId" BO_ 929 929;
BA_ "NetworkInitialization" BO_ 1496 0;
BA_ "GenMsgCycleTime" BO_ 1496 1000;
BA_ "GenMsgSendType" BO_ 1496 0;
BA_ "NmAsrMessage" BO_ 1496 1;
BA_ "GenMsgILSupport" BO_ 1496 0;
BA_ "FrameRouting" BO_ 960 "HS1_CAN,0x3C0;";
BA_ "FrameGatewayNetwork" BO_ 960 "HS1_CAN";
BA_ "FrameGatewayId" BO_ 960 960;
BA_ "FrameRouting" BO_ 957 "HS1_CAN,0x3BD;";
BA_ "FrameGatewayNetwork" BO_ 957 "HS1_CAN";
BA_ "FrameGatewayId" BO_ 957 957;
BA_ "FrameRouting" BO_ 718 "HS3_CAN,0x2CE;";
BA_ "FrameGatewayNetwork" BO_ 718 "HS3_CAN";
BA_ "FrameGatewayId" BO_ 718 718;
BA_ "TpTxIndex" BO_ 718 26;
BA_ "NetworkInitialization" BO_ 1491 0;
BA_ "GenMsgCycleTime" BO_ 1491 1000;
BA_ "GenMsgSendType" BO_ 1491 0;
BA_ "GenMsgCycleTime" BO_ 847 1000;
BA_ "GenMsgSendType" BO_ 847 5;
BA_ "GenMsgDelayTime" BO_ 2609972440 0;
BA_ "GenMsgSendType" BO_ 2609972440 1;
BA_ "TpTxIndex" BO_ 2609972440 462488792;
BA_ "NetworkInitialization" BO_ 2612158680 0;
BA_ "GenMsgDelayTime" BO_ 2612158680 0;
BA_ "GenMsgSendType" BO_ 2612158680 1;
BA_ "OvtpPushApplication" BO_ 2612158680 1;
BA_ "TpTxIndex" BO_ 2612158680 464675032;
BA_ "NetworkInitialization" BO_ 2612226264 0;
BA_ "GenMsgDelayTime" BO_ 2612226264 0;
BA_ "GenMsgSendType" BO_ 2612226264 1;
BA_ "OvtpPushApplication" BO_ 2612226264 1;
BA_ "TpTxIndex" BO_ 2612226264 464742616;
BA_ "NetworkInitialization" BO_ 2612168920 0;
BA_ "GenMsgDelayTime" BO_ 2612168920 0;
BA_ "GenMsgSendType" BO_ 2612168920 1;
BA_ "OvtpPushApplication" BO_ 2612168920 1;
BA_ "TpTxIndex" BO_ 2612168920 464685272;
BA_ "FrameRouting" BO_ 966 "HS1_CAN,0x3C6;";
BA_ "FrameGatewayNetwork" BO_ 966 "HS1_CAN";
BA_ "FrameGatewayId" BO_ 966 966;
BA_ "GenMsgDelayTime" BO_ 965 100;
BA_ "GenMsgCycleTime" BO_ 965 1000;
BA_ "GenMsgSendType" BO_ 965 5;
BA_ "NetworkInitialization" BO_ 1467 0;
BA_ "GenMsgCycleTime" BO_ 1467 1000;
BA_ "GenMsgSendType" BO_ 1467 0;
BA_ "NmAsrMessage" BO_ 1467 1;
BA_ "GenMsgILSupport" BO_ 1467 0;
BA_ "NetworkInitialization" BO_ 1869 0;
BA_ "GenMsgDelayTime" BO_ 1869 0;
BA_ "GenMsgSendType" BO_ 1869 1;
BA_ "DiagResponse" BO_ 1869 1;
BA_ "GenMsgILSupport" BO_ 1869 0;
BA_ "GenSigSendType" SG_ 612 SelDrvMdeSwtch_D_Stat6 3;
BA_ "ContentDependant" SG_ 612 SelDrvMdeSwtch_D_Stat6 1;
BA_ "GenSigStartValue" SG_ 1489 BCMB_GWOnBoardTester 255;
BA_ "ContentDependant" SG_ 1489 BCMB_GWOnBoardTester 1;
BA_ "GenSigStartValueInteger" SG_ 1489 BCMB_GWOnBoardTester 255;
BA_ "GenSigStartValue" SG_ 1489 BCMB_GWNMProxy 255;
BA_ "ContentDependant" SG_ 1489 BCMB_GWNMProxy 1;
BA_ "GenSigStartValueInteger" SG_ 1489 BCMB_GWNMProxy 255;
BA_ "GenSigStartValue" SG_ 1489 BCMB_AutoSarNMReserved4 255;
BA_ "ContentDependant" SG_ 1489 BCMB_AutoSarNMReserved4 1;
BA_ "GenSigStartValueInteger" SG_ 1489 BCMB_AutoSarNMReserved4 255;
BA_ "GenSigStartValue" SG_ 1489 BCMB_AutoSarNMReserved3 255;
BA_ "ContentDependant" SG_ 1489 BCMB_AutoSarNMReserved3 1;
BA_ "GenSigStartValueInteger" SG_ 1489 BCMB_AutoSarNMReserved3 255;
BA_ "GenSigStartValue" SG_ 1489 BCMB_AutoSarNMReserved2 255;
BA_ "ContentDependant" SG_ 1489 BCMB_AutoSarNMReserved2 1;
BA_ "GenSigStartValueInteger" SG_ 1489 BCMB_AutoSarNMReserved2 255;
BA_ "GenSigStartValue" SG_ 1489 BCMB_AutoSarNMReserved1 255;
BA_ "ContentDependant" SG_ 1489 BCMB_AutoSarNMReserved1 1;
BA_ "GenSigStartValueInteger" SG_ 1489 BCMB_AutoSarNMReserved1 255;
BA_ "GenSigStartValue" SG_ 1489 BCMB_AutoSarNMNodeId 209;
BA_ "ContentDependant" SG_ 1489 BCMB_AutoSarNMNodeId 1;
BA_ "GenSigStartValueInteger" SG_ 1489 BCMB_AutoSarNMNodeId 208;
BA_ "ContentDependant" SG_ 1489 BCMB_AutoSarNMControl 1;
BA_ "U_CD764_MY2022_Tx" SG_ 1017 SteWhlHeat_D_RqRmt 1;
BA_ "ECGUsedTxSignal" SG_ 1017 SteWhlHeat_D_RqRmt 1;
BA_ "U_CD764_MY2022_Rx" SG_ 1017 SteWhlHeat_D_RqRmt 1;
BA_ "GenSigSendType" SG_ 1017 SteWhlHeat_D_RqRmt 3;
BA_ "U_CD764_MY2022_Tx" SG_ 1017 WndwRearDfrst_D_RqRmt 1;
BA_ "ECGUsedTxSignal" SG_ 1017 WndwRearDfrst_D_RqRmt 1;
BA_ "U_CD764_MY2022_Rx" SG_ 1017 WndwRearDfrst_D_RqRmt 1;
BA_ "GenSigSendType" SG_ 1017 WndwRearDfrst_D_RqRmt 3;
BA_ "U_CD764_MY2022_Tx" SG_ 1017 WndwFrontHeat_D_RqRmt 1;
BA_ "ECGUsedTxSignal" SG_ 1017 WndwFrontHeat_D_RqRmt 1;
BA_ "U_CD764_MY2022_Rx" SG_ 1017 WndwFrontHeat_D_RqRmt 1;
BA_ "GenSigSendType" SG_ 1017 WndwFrontHeat_D_RqRmt 3;
BA_ "U_CD764_MY2022_Tx" SG_ 1017 RstrtHvacOvrrd_B_RqRmt 1;
BA_ "ECGUsedTxSignal" SG_ 1017 RstrtHvacOvrrd_B_RqRmt 1;
BA_ "U_CD764_MY2022_Rx" SG_ 1017 RstrtHvacOvrrd_B_RqRmt 1;
BA_ "GenSigSendType" SG_ 1017 RstrtHvacOvrrd_B_RqRmt 3;
BA_ "U_CD764_MY2022_Tx" SG_ 1017 SeatTeRr_D_RqRmt 1;
BA_ "ECGUsedTxSignal" SG_ 1017 SeatTeRr_D_RqRmt 1;
BA_ "U_CD764_MY2022_Rx" SG_ 1017 SeatTeRr_D_RqRmt 1;
BA_ "GenSigSendType" SG_ 1017 SeatTeRr_D_RqRmt 3;
BA_ "U_CD764_MY2022_Tx" SG_ 1017 SeatTeRl_D_RqRmt 1;
BA_ "ECGUsedTxSignal" SG_ 1017 SeatTeRl_D_RqRmt 1;
BA_ "U_CD764_MY2022_Rx" SG_ 1017 SeatTeRl_D_RqRmt 1;
BA_ "GenSigSendType" SG_ 1017 SeatTeRl_D_RqRmt 3;
BA_ "U_CD764_MY2022_Tx" SG_ 1017 SeatTeFr_D_RqRmt 1;
BA_ "ECGUsedTxSignal" SG_ 1017 SeatTeFr_D_RqRmt 1;
BA_ "U_CD764_MY2022_Rx" SG_ 1017 SeatTeFr_D_RqRmt 1;
BA_ "GenSigSendType" SG_ 1017 SeatTeFr_D_RqRmt 3;
BA_ "U_CD764_MY2022_Tx" SG_ 1017 SeatTeFl_D_RqRmt 1;
BA_ "ECGUsedTxSignal" SG_ 1017 SeatTeFl_D_RqRmt 1;
BA_ "U_CD764_MY2022_Rx" SG_ 1017 SeatTeFl_D_RqRmt 1;
BA_ "GenSigSendType" SG_ 1017 SeatTeFl_D_RqRmt 3;
BA_ "U_CD764_MY2022_Tx" SG_ 1017 CabnTeOn_B_RqRmt 1;
BA_ "ECGUsedTxSignal" SG_ 1017 CabnTeOn_B_RqRmt 1;
BA_ "U_CD764_MY2022_Rx" SG_ 1017 CabnTeOn_B_RqRmt 1;
BA_ "GenSigSendType" SG_ 1017 CabnTeOn_B_RqRmt 3;
BA_ "U_CD764_MY2022_Tx" SG_ 1017 HvacMde_D_RqRmt 1;
BA_ "ECGUsedTxSignal" SG_ 1017 HvacMde_D_RqRmt 1;
BA_ "U_CD764_MY2022_Rx" SG_ 1017 HvacMde_D_RqRmt 1;
BA_ "GenSigSendType" SG_ 1017 HvacMde_D_RqRmt 3;
BA_ "MetaData" SG_ 303 CanMsg12F_No_Crc 1;
BA_ "ContentDependant" SG_ 303 CanMsg12F_No_Crc 1;
BA_ "MetaData" SG_ 303 CanMsg12F_No_Cnt 1;
BA_ "ContentDependant" SG_ 303 CanMsg12F_No_Cnt 1;
BA_ "WakeupSignal" SG_ 303 DrStatHood_D2_Actl 1;
BA_ "ECGUsedTxSignal" SG_ 2611021016 PARSEDPhysGWM_ECGtoSCMJ 1;
BA_ "GenSigSendType" SG_ 2611021016 PARSEDPhysGWM_ECGtoSCMJ 3;
BA_ "U_CD764_MY2022_Rx" SG_ 1480 RHVAC_GWOnBoardTester 1;
BA_ "ECGUsedRxSignal" SG_ 1480 RHVAC_GWOnBoardTester 1;
BA_ "GenSigStartValue" SG_ 1480 RHVAC_GWOnBoardTester 255;
BA_ "ContentDependant" SG_ 1480 RHVAC_GWOnBoardTester 1;
BA_ "GenSigStartValueInteger" SG_ 1480 RHVAC_GWOnBoardTester 255;
BA_ "U_CD764_MY2022_Rx" SG_ 1480 RHVAC_GWNMProxy 1;
BA_ "ECGUsedRxSignal" SG_ 1480 RHVAC_GWNMProxy 1;
BA_ "GenSigStartValue" SG_ 1480 RHVAC_GWNMProxy 255;
BA_ "ContentDependant" SG_ 1480 RHVAC_GWNMProxy 1;
BA_ "GenSigStartValueInteger" SG_ 1480 RHVAC_GWNMProxy 255;
BA_ "U_CD764_MY2022_Rx" SG_ 1480 RHVAC_AutoSarNMReserved4 1;
BA_ "ECGUsedRxSignal" SG_ 1480 RHVAC_AutoSarNMReserved4 1;
BA_ "GenSigStartValue" SG_ 1480 RHVAC_AutoSarNMReserved4 255;
BA_ "ContentDependant" SG_ 1480 RHVAC_AutoSarNMReserved4 1;
BA_ "GenSigStartValueInteger" SG_ 1480 RHVAC_AutoSarNMReserved4 255;
BA_ "U_CD764_MY2022_Rx" SG_ 1480 RHVAC_AutoSarNMReserved3 1;
BA_ "ECGUsedRxSignal" SG_ 1480 RHVAC_AutoSarNMReserved3 1;
BA_ "GenSigStartValue" SG_ 1480 RHVAC_AutoSarNMReserved3 255;
BA_ "ContentDependant" SG_ 1480 RHVAC_AutoSarNMReserved3 1;
BA_ "GenSigStartValueInteger" SG_ 1480 RHVAC_AutoSarNMReserved3 255;
BA_ "U_CD764_MY2022_Rx" SG_ 1480 RHVAC_AutoSarNMReserved2 1;
BA_ "ECGUsedRxSignal" SG_ 1480 RHVAC_AutoSarNMReserved2 1;
BA_ "GenSigStartValue" SG_ 1480 RHVAC_AutoSarNMReserved2 255;
BA_ "ContentDependant" SG_ 1480 RHVAC_AutoSarNMReserved2 1;
BA_ "GenSigStartValueInteger" SG_ 1480 RHVAC_AutoSarNMReserved2 255;
BA_ "U_CD764_MY2022_Rx" SG_ 1480 RHVAC_AutoSarNMReserved 1;
BA_ "ECGUsedRxSignal" SG_ 1480 RHVAC_AutoSarNMReserved 1;
BA_ "GenSigStartValue" SG_ 1480 RHVAC_AutoSarNMReserved 255;
BA_ "ContentDependant" SG_ 1480 RHVAC_AutoSarNMReserved 1;
BA_ "GenSigStartValueInteger" SG_ 1480 RHVAC_AutoSarNMReserved 255;
BA_ "U_CD764_MY2022_Rx" SG_ 1480 RHVAC_AutoSarNMNodeId 1;
BA_ "ECGUsedRxSignal" SG_ 1480 RHVAC_AutoSarNMNodeId 1;
BA_ "GenSigStartValue" SG_ 1480 RHVAC_AutoSarNMNodeId 200;
BA_ "ContentDependant" SG_ 1480 RHVAC_AutoSarNMNodeId 1;
BA_ "U_CD764_MY2022_Rx" SG_ 1480 RHVAC_AutoSarNMControl 1;
BA_ "ECGUsedRxSignal" SG_ 1480 RHVAC_AutoSarNMControl 1;
BA_ "ContentDependant" SG_ 1480 RHVAC_AutoSarNMControl 1;
BA_ "U_CD764_MY2022_Rx" SG_ 1015 E_Frt_Btn_Status_2nd 1;
BA_ "GenSigSendType" SG_ 1015 E_Frt_Btn_Status_2nd 3;
BA_ "U_CD764_MY2022_Rx" SG_ 1015 E_Frt_Btn_Status_1st 1;
BA_ "GenSigSendType" SG_ 1015 E_Frt_Btn_Status_1st 3;
BA_ "GenSigSendType" SG_ 1015 SelDrvMdeSwtch_D_Stat7 3;
BA_ "U_CD764_MY2022_Rx" SG_ 1067 VehStrtInhbt_D_Stat_UB 1;
BA_ "U_U55X_MY2022_Rx" SG_ 1067 VehStrtInhbt_D_Stat_UB 1;
BA_ "U_CD764_MY2022_Rx" SG_ 1067 VehOnSrc2_D_Stat_UB 1;
BA_ "U_U55X_MY2022_Rx" SG_ 1067 VehOnSrc2_D_Stat_UB 1;
BA_ "U_CD764_MY2022_Rx" SG_ 1067 VehStrtInhbt_D_Stat 1;
BA_ "U_U55X_MY2022_Rx" SG_ 1067 VehStrtInhbt_D_Stat 1;
BA_ "U_CD764_MY2022_Rx" SG_ 1067 VehOnSrc2_D_Stat 1;
BA_ "U_U55X_MY2022_Rx" SG_ 1067 VehOnSrc2_D_Stat 1;
BA_ "U_CD764_MY2022_Rx" SG_ 1067 ElCmpr_N_Actl_UB 1;
BA_ "U_U55X_MY2022_Rx" SG_ 1067 ElCmpr_N_Actl_UB 1;
BA_ "U_CD542_MY2021_Rx" SG_ 1067 ElCmpr_N_Actl_UB 1;
BA_ "U_T6_MCA_MY2020_Rx" SG_ 1067 ElCmpr_N_Actl_UB 1;
BA_ "U_CD764_MY2022_Rx" SG_ 1067 ElCmpr_D_Stat_UB 1;
BA_ "U_U55X_MY2022_Rx" SG_ 1067 ElCmpr_D_Stat_UB 1;
BA_ "U_CD542_MY2021_Rx" SG_ 1067 ElCmpr_D_Stat_UB 1;
BA_ "U_T6_MCA_MY2020_Rx" SG_ 1067 ElCmpr_D_Stat_UB 1;
BA_ "U_CD764_MY2022_Rx" SG_ 1067 ElCmpr_N_Actl 1;
BA_ "U_U55X_MY2022_Rx" SG_ 1067 ElCmpr_N_Actl 1;
BA_ "U_CD542_MY2021_Rx" SG_ 1067 ElCmpr_N_Actl 1;
BA_ "U_T6_MCA_MY2020_Rx" SG_ 1067 ElCmpr_N_Actl 1;
BA_ "U_CD764_MY2022_Rx" SG_ 1067 ElCmpr_D_Stat 1;
BA_ "U_U55X_MY2022_Rx" SG_ 1067 ElCmpr_D_Stat 1;
BA_ "U_CD542_MY2021_Rx" SG_ 1067 ElCmpr_D_Stat 1;
BA_ "U_T6_MCA_MY2020_Rx" SG_ 1067 ElCmpr_D_Stat 1;
BA_ "U_CD542_MY2021_Tx" SG_ 2612191448 PARSEDPushFcGWM_ECGtoMRCMA 1;
BA_ "ECGUsedTxSignal" SG_ 2612191448 PARSEDPushFcGWM_ECGtoMRCMA 1;
BA_ "GenSigSendType" SG_ 2612191448 PARSEDPushFcGWM_ECGtoMRCMA 3;
BA_ "U_CD542_MY2021_Rx" SG_ 2612224184 PARSEDPushMRCMAtoGWM_ECG 1;
BA_ "ECGUsedRxSignal" SG_ 2612224184 PARSEDPushMRCMAtoGWM_ECG 1;
BA_ "GenSigSendType" SG_ 2612224184 PARSEDPushMRCMAtoGWM_ECG 3;
BA_ "U_CD542_MY2021_Tx" SG_ 2611142872 PARSEDPhysGWM_ECGtoMRCMA 1;
BA_ "ECGUsedTxSignal" SG_ 2611142872 PARSEDPhysGWM_ECGtoMRCMA 1;
BA_ "GenSigSendType" SG_ 2611142872 PARSEDPhysGWM_ECGtoMRCMA 3;
BA_ "U_CD542_MY2021_Rx" SG_ 2611175608 PARSEDPhysMRCMAtoGWM_ECG 1;
BA_ "ECGUsedRxSignal" SG_ 2611175608 PARSEDPhysMRCMAtoGWM_ECG 1;
BA_ "GenSigSendType" SG_ 2611175608 PARSEDPhysMRCMAtoGWM_ECG 3;
BA_ "GenSigStartValue" SG_ 1080 Btt_L_Actl2 126;
BA_ "GenSigStartValueInteger" SG_ 1080 Btt_L_Actl2 126;
BA_ "U_T6_MCA_MY2020_Rx" SG_ 1080 TrlrRvrseMsgTxt_D2_Rq_UB 1;
BA_ "U_T6_MCA_MY2020_Rx" SG_ 1080 TrlrRvrseMsgTxt_D2_Rq 1;
BA_ "GenSigSendType" SG_ 1080 TrlrRvrseMsgTxt_D2_Rq 3;
BA_ "U_T6_MCA_MY2020_Rx" SG_ 1080 TrlrRvrseEnbl_D2_Stat_UB 1;
BA_ "U_T6_MCA_MY2020_Rx" SG_ 1080 TrlrRvrseEnbl_D2_Stat 1;
BA_ "GenSigSendType" SG_ 1080 TrlrRvrseEnbl_D2_Stat 3;
BA_ "U_U55X_MY2022_Rx" SG_ 1080 PwRnngBoardT_D_Rq_UB 1;
BA_ "U_U55X_MY2022_Rx" SG_ 1080 PwRnngBoardSwtch_D_Rq_UB 1;
BA_ "U_U55X_MY2022_Rx" SG_ 1080 PwRnngBoardMde_D_Rq_UB 1;
BA_ "U_U55X_MY2022_Rx" SG_ 1080 PwRnngBoardT_D_Rq 1;
BA_ "GenSigSendType" SG_ 1080 PwRnngBoardT_D_Rq 3;
BA_ "U_U55X_MY2022_Rx" SG_ 1080 PwRnngBoardSwtch_D_Rq 1;
BA_ "GenSigSendType" SG_ 1080 PwRnngBoardSwtch_D_Rq 3;
BA_ "U_U55X_MY2022_Rx" SG_ 1080 PwRnngBoardMde_D_Rq 1;
BA_ "GenSigSendType" SG_ 1080 PwRnngBoardMde_D_Rq 3;
BA_ "GenSigSendType" SG_ 1080 StopStrtDrvMde_B_RqBtn3 3;
BA_ "U_CD542_MY2021_Rx" SG_ 1080 Cntr_Plg_Mode_Cmd_UB 1;
BA_ "U_T6_MCA_MY2020_Rx" SG_ 1080 Cntr_Plg_Mode_Cmd_UB 1;
BA_ "U_CD542_MY2021_Rx" SG_ 1080 Cntr_Plg_Mode_Cmd 1;
BA_ "U_T6_MCA_MY2020_Rx" SG_ 1080 Cntr_Plg_Mode_Cmd 1;
BA_ "GenSigSendType" SG_ 1080 Cntr_Plg_Mode_Cmd 3;
BA_ "WakeupSignal" SG_ 1080 Cntr_Plg_Mode_Cmd 1;
BA_ "U_CD542_MY2021_Tx" SG_ 2610094296 OTAPhysGWM_ECG_to_MRCMA 1;
BA_ "ECGUsedTxSignal" SG_ 2610094296 OTAPhysGWM_ECG_to_MRCMA 1;
BA_ "GenSigSendType" SG_ 2610094296 OTAPhysGWM_ECG_to_MRCMA 3;
BA_ "U_CD542_MY2021_Rx" SG_ 2610127032 OTAPhysMRCMAtoGWM_ECG 1;
BA_ "ECGUsedRxSignal" SG_ 2610127032 OTAPhysMRCMAtoGWM_ECG 1;
BA_ "GenSigSendType" SG_ 2610127032 OTAPhysMRCMAtoGWM_ECG 3;
BA_ "U_CD542_MY2021_Tx" SG_ 2610085080 OTAPhysGWM_ECGtoRGTM 1;
BA_ "ECGUsedTxSignal" SG_ 2610085080 OTAPhysGWM_ECGtoRGTM 1;
BA_ "GenSigSendType" SG_ 2610085080 OTAPhysGWM_ECGtoRGTM 3;
BA_ "U_CD542_MY2021_Tx" SG_ 2611133656 PARSEDPhysGWM_ECGtoRGTM 1;
BA_ "ECGUsedTxSignal" SG_ 2611133656 PARSEDPhysGWM_ECGtoRGTM 1;
BA_ "GenSigSendType" SG_ 2611133656 PARSEDPhysGWM_ECGtoRGTM 3;
BA_ "U_CD542_MY2021_Tx" SG_ 2612182232 PARSEDPushFcGWM_ECGtoRGTM 1;
BA_ "ECGUsedTxSignal" SG_ 2612182232 PARSEDPushFcGWM_ECGtoRGTM 1;
BA_ "GenSigSendType" SG_ 2612182232 PARSEDPushFcGWM_ECGtoRGTM 3;
BA_ "GenSigStartValueInteger" SG_ 915 ApaObjStrtY_L_Actl 187;
BA_ "GenSigStartValueInteger" SG_ 915 ApaObjStrtX_L_Actl 187;
BA_ "GenSigStartValueInteger" SG_ 915 ApaObjStrtDpthY_L_Actl 187;
BA_ "GenSigStartValueInteger" SG_ 915 ApaObjStrtDpthX_L_Actl 187;
BA_ "GenSigStartValueInteger" SG_ 915 ApaObjEndY_L_Actl 187;
BA_ "GenSigStartValueInteger" SG_ 915 ApaObjEndX_L_Actl 187;
BA_ "GenSigStartValueInteger" SG_ 915 ApaObjEndDpthY_L_Actl 187;
BA_ "GenSigStartValueInteger" SG_ 915 ApaObjEndDpthX_L_Actl 187;
BA_ "GenSigSendType" SG_ 1217 SldrrStat_B_Actl 3;
BA_ "GenSigSendType" SG_ 1217 SldrrMsgTxt_D2_Rq 3;
BA_ "WakeupSignal" SG_ 1217 SldrrMsgTxt_D2_Rq 1;
BA_ "GenSigSendType" SG_ 1217 SldrrChime_D_Rq 3;
BA_ "WakeupSignal" SG_ 1217 SldrrChime_D_Rq 1;
BA_ "U_U55X_MY2022_Rx" SG_ 1217 PwStepRight_D_Rq 1;
BA_ "GenSigSendType" SG_ 1217 PwStepRight_D_Rq 3;
BA_ "GenSigSendType" SG_ 1217 SldrrUnlckSwtch_D_Stat 3;
BA_ "GenSigSendType" SG_ 1217 SldrrUnlckRollCd_No_Cnt 3;
BA_ "GenSigSendType" SG_ 1217 SldrrUnlck_No_Cnt 3;
BA_ "WakeupSignal" SG_ 1217 SldrrUnlck_No_Cnt 1;
BA_ "GenSigSendType" SG_ 1217 SldrrChildLck_No_Cnt 3;
BA_ "WakeupSignal" SG_ 1217 SldrrChildLck_No_Cnt 1;
BA_ "GenSigSendType" SG_ 1217 Sldrr_D_Stat 3;
BA_ "WakeupSignal" SG_ 1217 Sldrr_D_Stat 1;
BA_ "GenSigSendType" SG_ 1216 SldrlMsgTxt_D2_Rq 3;
BA_ "WakeupSignal" SG_ 1216 SldrlMsgTxt_D2_Rq 1;
BA_ "GenSigSendType" SG_ 1216 SldrlChime_D_Rq 3;
BA_ "WakeupSignal" SG_ 1216 SldrlChime_D_Rq 1;
BA_ "GenSigSendType" SG_ 1216 SldrlStat_B_Actl 3;
BA_ "U_U55X_MY2022_Rx" SG_ 1216 PwStepLeft_D_Rq 1;
BA_ "GenSigSendType" SG_ 1216 PwStepLeft_D_Rq 3;
BA_ "GenSigSendType" SG_ 1216 SldrlUnlckSwtch_D_Stat 3;
BA_ "GenSigSendType" SG_ 1216 SldrlUnlckRollCd_No_Cnt 3;
BA_ "GenSigSendType" SG_ 1216 SldrlUnlck_No_Cnt 3;
BA_ "WakeupSignal" SG_ 1216 SldrlUnlck_No_Cnt 1;
BA_ "GenSigSendType" SG_ 1216 SldrlChildLck_No_Cnt 3;
BA_ "WakeupSignal" SG_ 1216 SldrlChildLck_No_Cnt 1;
BA_ "GenSigSendType" SG_ 1216 Sldrl_D_Stat 3;
BA_ "WakeupSignal" SG_ 1216 Sldrl_D_Stat 1;
BA_ "ECGUsedRxSignal" SG_ 877 CabnAmb_Te_ActlAft 1;
BA_ "GenSigStartValue" SG_ 877 CabnAmb_Te_ActlAft 255;
BA_ "ECGUsedRxSignal" SG_ 877 RstrtClimtSet_B_Actv 1;
BA_ "GenSigSendType" SG_ 877 RstrtClimtSet_B_Actv 3;
BA_ "U_CD764_MY2022_Tx" SG_ 877 Rr_Third_Power_Btn_Stt 1;
BA_ "U_U55X_MY2022_Tx" SG_ 877 Rr_Third_Power_Btn_Stt 1;
BA_ "U_CD542_MY2021_Tx" SG_ 877 Rr_Third_Power_Btn_Stt 1;
BA_ "U_T6_MCA_MY2020_Tx" SG_ 877 Rr_Third_Power_Btn_Stt 1;
BA_ "U_CX727_MY2021_Tx" SG_ 877 Rr_Third_Power_Btn_Stt 1;
BA_ "U_T6_MCA_MY2020_Rx" SG_ 877 Rr_Third_Power_Btn_Stt 1;
BA_ "GenSigSendType" SG_ 877 Rr_Third_Power_Btn_Stt 3;
BA_ "GenSigStartValue" SG_ 877 Rr_Third_Power_Btn_Stt 2;
BA_ "GenSigStartValueInteger" SG_ 877 Rr_Third_Power_Btn_Stt 2;
BA_ "U_CD764_MY2022_Tx" SG_ 877 Rr_Third_Floor_Btn_Stt 1;
BA_ "U_U55X_MY2022_Tx" SG_ 877 Rr_Third_Floor_Btn_Stt 1;
BA_ "U_CD542_MY2021_Tx" SG_ 877 Rr_Third_Floor_Btn_Stt 1;
BA_ "U_T6_MCA_MY2020_Tx" SG_ 877 Rr_Third_Floor_Btn_Stt 1;
BA_ "U_CX727_MY2021_Tx" SG_ 877 Rr_Third_Floor_Btn_Stt 1;
BA_ "U_T6_MCA_MY2020_Rx" SG_ 877 Rr_Third_Floor_Btn_Stt 1;
BA_ "GenSigSendType" SG_ 877 Rr_Third_Floor_Btn_Stt 3;
BA_ "GenSigStartValue" SG_ 877 Rr_Third_Floor_Btn_Stt 2;
BA_ "GenSigStartValueInteger" SG_ 877 Rr_Third_Floor_Btn_Stt 2;
BA_ "U_CD764_MY2022_Tx" SG_ 877 Rr_Third_Auto_Btn_Stt 1;
BA_ "U_U55X_MY2022_Tx" SG_ 877 Rr_Third_Auto_Btn_Stt 1;
BA_ "U_CD542_MY2021_Tx" SG_ 877 Rr_Third_Auto_Btn_Stt 1;
BA_ "U_T6_MCA_MY2020_Tx" SG_ 877 Rr_Third_Auto_Btn_Stt 1;
BA_ "U_CX727_MY2021_Tx" SG_ 877 Rr_Third_Auto_Btn_Stt 1;
BA_ "U_T6_MCA_MY2020_Rx" SG_ 877 Rr_Third_Auto_Btn_Stt 1;
BA_ "GenSigSendType" SG_ 877 Rr_Third_Auto_Btn_Stt 3;
BA_ "GenSigStartValue" SG_ 877 Rr_Third_Auto_Btn_Stt 2;
BA_ "GenSigStartValueInteger" SG_ 877 Rr_Third_Auto_Btn_Stt 2;
BA_ "U_CD764_MY2022_Tx" SG_ 877 Rr_Lock_Btn_Stt 1;
BA_ "U_U55X_MY2022_Tx" SG_ 877 Rr_Lock_Btn_Stt 1;
BA_ "U_CD542_MY2021_Tx" SG_ 877 Rr_Lock_Btn_Stt 1;
BA_ "U_T6_MCA_MY2020_Tx" SG_ 877 Rr_Lock_Btn_Stt 1;
BA_ "U_CX727_MY2021_Tx" SG_ 877 Rr_Lock_Btn_Stt 1;
BA_ "U_T6_MCA_MY2020_Rx" SG_ 877 Rr_Lock_Btn_Stt 1;
BA_ "GenSigSendType" SG_ 877 Rr_Lock_Btn_Stt 3;
BA_ "GenSigStartValue" SG_ 877 Rr_Lock_Btn_Stt 2;
BA_ "GenSigStartValueInteger" SG_ 877 Rr_Lock_Btn_Stt 2;
BA_ "U_CD764_MY2022_Tx" SG_ 877 Rr_RHS_Blower_Indicate 1;
BA_ "U_U55X_MY2022_Tx" SG_ 877 Rr_RHS_Blower_Indicate 1;
BA_ "U_CD542_MY2021_Tx" SG_ 877 Rr_RHS_Blower_Indicate 1;
BA_ "U_T6_MCA_MY2020_Tx" SG_ 877 Rr_RHS_Blower_Indicate 1;
BA_ "U_CX727_MY2021_Tx" SG_ 877 Rr_RHS_Blower_Indicate 1;
BA_ "U_T6_MCA_MY2020_Rx" SG_ 877 Rr_RHS_Blower_Indicate 1;
BA_ "GenSigSendType" SG_ 877 Rr_RHS_Blower_Indicate 3;
BA_ "GenSigStartValue" SG_ 877 Rr_RHS_Blower_Indicate 15;
BA_ "GenSigStartValueInteger" SG_ 877 Rr_RHS_Blower_Indicate 15;
BA_ "U_CD764_MY2022_Tx" SG_ 877 Rr_Third_Panel_Btn_Stt 1;
BA_ "U_U55X_MY2022_Tx" SG_ 877 Rr_Third_Panel_Btn_Stt 1;
BA_ "U_CD542_MY2021_Tx" SG_ 877 Rr_Third_Panel_Btn_Stt 1;
BA_ "U_T6_MCA_MY2020_Tx" SG_ 877 Rr_Third_Panel_Btn_Stt 1;
BA_ "U_CX727_MY2021_Tx" SG_ 877 Rr_Third_Panel_Btn_Stt 1;
BA_ "U_T6_MCA_MY2020_Rx" SG_ 877 Rr_Third_Panel_Btn_Stt 1;
BA_ "GenSigSendType" SG_ 877 Rr_Third_Panel_Btn_Stt 3;
BA_ "GenSigStartValue" SG_ 877 Rr_Third_Panel_Btn_Stt 2;
BA_ "GenSigStartValueInteger" SG_ 877 Rr_Third_Panel_Btn_Stt 2;
BA_ "U_CD764_MY2022_Tx" SG_ 877 Rr_Synch_Btn_Stt 1;
BA_ "U_U55X_MY2022_Tx" SG_ 877 Rr_Synch_Btn_Stt 1;
BA_ "U_CD542_MY2021_Tx" SG_ 877 Rr_Synch_Btn_Stt 1;
BA_ "U_T6_MCA_MY2020_Tx" SG_ 877 Rr_Synch_Btn_Stt 1;
BA_ "U_CX727_MY2021_Tx" SG_ 877 Rr_Synch_Btn_Stt 1;
BA_ "U_T6_MCA_MY2020_Rx" SG_ 877 Rr_Synch_Btn_Stt 1;
BA_ "GenSigSendType" SG_ 877 Rr_Synch_Btn_Stt 3;
BA_ "GenSigStartValue" SG_ 877 Rr_Synch_Btn_Stt 2;
BA_ "GenSigStartValueInteger" SG_ 877 Rr_Synch_Btn_Stt 2;
BA_ "U_CD764_MY2022_Tx" SG_ 877 AAR_Btn_Stt 1;
BA_ "U_U55X_MY2022_Tx" SG_ 877 AAR_Btn_Stt 1;
BA_ "U_CD542_MY2021_Tx" SG_ 877 AAR_Btn_Stt 1;
BA_ "U_T6_MCA_MY2020_Tx" SG_ 877 AAR_Btn_Stt 1;
BA_ "U_P702_MY2021_Tx" SG_ 877 AAR_Btn_Stt 1;
BA_ "U_CX727_MY2021_Tx" SG_ 877 AAR_Btn_Stt 1;
BA_ "GenSigSendType" SG_ 877 AAR_Btn_Stt 3;
BA_ "GenSigStartValue" SG_ 877 AAR_Btn_Stt 2;
BA_ "GenSigStartValueInteger" SG_ 877 AAR_Btn_Stt 2;
BA_ "U_CD764_MY2022_Tx" SG_ 877 Heat_Btn_Stt 1;
BA_ "U_U55X_MY2022_Tx" SG_ 877 Heat_Btn_Stt 1;
BA_ "U_CD542_MY2021_Tx" SG_ 877 Heat_Btn_Stt 1;
BA_ "U_T6_MCA_MY2020_Tx" SG_ 877 Heat_Btn_Stt 1;
BA_ "U_P702_MY2021_Tx" SG_ 877 Heat_Btn_Stt 1;
BA_ "U_CX727_MY2021_Tx" SG_ 877 Heat_Btn_Stt 1;
BA_ "GenSigSendType" SG_ 877 Heat_Btn_Stt 3;
BA_ "GenSigStartValue" SG_ 877 Heat_Btn_Stt 2;
BA_ "GenSigStartValueInteger" SG_ 877 Heat_Btn_Stt 2;
BA_ "GenSigStartValueInteger" SG_ 918 ApaVehPosY_L_Actl 512;
BA_ "GenSigStartValueInteger" SG_ 918 ApaVehPosX_L_Actl 512;
BA_ "GenSigStartValueInteger" SG_ 918 ApaVehPos_An_Actl 512;
BA_ "GenSigStartValueInteger" SG_ 917 ApaVehToSlotY_L_Actl 512;
BA_ "GenSigStartValueInteger" SG_ 917 ApaVehToSlotX_L_Actl 512;
BA_ "GenSigStartValueInteger" SG_ 917 ApaVehToSlot_An_Actl 127.447131321717;
BA_ "GenSigSendType" SG_ 773 StmsScrnPsngrOn_B_Rq 3;
BA_ "U_U55X_MY2022_Tx" SG_ 773 SeatScrnPsngrOn_B_Rq 1;
BA_ "GenSigSendType" SG_ 773 SeatScrnPsngrOn_B_Rq 3;
BA_ "U_U55X_MY2022_Tx" SG_ 773 SeatPsngrMem_D_Cmd 1;
BA_ "U_U55X_MY2022_Rx" SG_ 773 SeatPsngrMem_D_Cmd 1;
BA_ "GenSigSendType" SG_ 773 SeatPsngrMem_D_Cmd 3;
BA_ "U_U55X_MY2022_Tx" SG_ 773 MemSwtchPsngrFdbck_B_Rq 1;
BA_ "U_CX727_MY2021_Rx" SG_ 773 MemSwtchPsngrFdbck_B_Rq 1;
BA_ "GenSigSendType" SG_ 773 MemSwtchPsngrFdbck_B_Rq 3;
BA_ "U_T6_MCA_MY2020_Rx" SG_ 878 ClimtSyncRear2_B_Stat 1;
BA_ "GenSigSendType" SG_ 878 ClimtSyncRear2_B_Stat 3;
BA_ "U_T6_MCA_MY2020_Rx" SG_ 878 ClimtStHeatRr2_B_Stat 1;
BA_ "GenSigSendType" SG_ 878 ClimtStHeatRr2_B_Stat 3;
BA_ "U_T6_MCA_MY2020_Rx" SG_ 878 ClimtStHeatRl2_B_Stat 1;
BA_ "GenSigSendType" SG_ 878 ClimtStHeatRl2_B_Stat 3;
BA_ "U_T6_MCA_MY2020_Rx" SG_ 878 ClimtStCoolRr2_B_Stat 1;
BA_ "GenSigSendType" SG_ 878 ClimtStCoolRr2_B_Stat 3;
BA_ "U_T6_MCA_MY2020_Rx" SG_ 878 ClimtStCoolRl2_B_Stat 1;
BA_ "GenSigSendType" SG_ 878 ClimtStCoolRl2_B_Stat 3;
BA_ "U_T6_MCA_MY2020_Rx" SG_ 878 ClimtSeatRr2_D_Rq 1;
BA_ "GenSigSendType" SG_ 878 ClimtSeatRr2_D_Rq 3;
BA_ "U_T6_MCA_MY2020_Rx" SG_ 878 ClimtSeatRl2_D_Rq 1;
BA_ "GenSigSendType" SG_ 878 ClimtSeatRl2_D_Rq 3;
BA_ "U_T6_MCA_MY2020_Rx" SG_ 878 ClimtRrTe3rd2_D_Stat 1;
BA_ "GenSigSendType" SG_ 878 ClimtRrTe3rd2_D_Stat 3;
BA_ "U_T6_MCA_MY2020_Rx" SG_ 878 ClimtRrPw3rd2_B_Stat 1;
BA_ "GenSigSendType" SG_ 878 ClimtRrPw3rd2_B_Stat 3;
BA_ "U_T6_MCA_MY2020_Rx" SG_ 878 ClimtRrPnl3rd2_B_Stat 1;
BA_ "GenSigSendType" SG_ 878 ClimtRrPnl3rd2_B_Stat 3;
BA_ "U_T6_MCA_MY2020_Rx" SG_ 878 ClimtRrPf3rd2_B_Stat 1;
BA_ "GenSigSendType" SG_ 878 ClimtRrPf3rd2_B_Stat 3;
BA_ "U_T6_MCA_MY2020_Rx" SG_ 878 ClimtRrFlr3rd2_B_Stat 1;
BA_ "GenSigSendType" SG_ 878 ClimtRrFlr3rd2_B_Stat 3;
BA_ "U_T6_MCA_MY2020_Rx" SG_ 878 ClimtRrBlwr3rd2_D_Stat 1;
BA_ "GenSigSendType" SG_ 878 ClimtRrBlwr3rd2_D_Stat 3;
BA_ "U_T6_MCA_MY2020_Rx" SG_ 878 ClimtRrAuto3rd2_B_Stat 1;
BA_ "GenSigSendType" SG_ 878 ClimtRrAuto3rd2_B_Stat 3;
BA_ "U_T6_MCA_MY2020_Rx" SG_ 878 ClimtRearView2_D_Stat 1;
BA_ "GenSigSendType" SG_ 878 ClimtRearView2_D_Stat 3;
BA_ "U_T6_MCA_MY2020_Rx" SG_ 878 ClimtRearTe2_D_Stat 1;
BA_ "GenSigSendType" SG_ 878 ClimtRearTe2_D_Stat 3;
BA_ "U_T6_MCA_MY2020_Rx" SG_ 878 ClimtRearTe2_An_Actl 1;
BA_ "GenSigSendType" SG_ 878 ClimtRearTe2_An_Actl 3;
BA_ "GenSigStartValue" SG_ 878 ClimtRearTe2_An_Actl 511;
BA_ "GenSigStartValueInteger" SG_ 878 ClimtRearTe2_An_Actl 511;
BA_ "U_T6_MCA_MY2020_Rx" SG_ 878 ClimtRearPw2_B_Stat 1;
BA_ "GenSigSendType" SG_ 878 ClimtRearPw2_B_Stat 3;
BA_ "U_T6_MCA_MY2020_Rx" SG_ 878 ClimtRearPnlFlr2_B_Stat 1;
BA_ "GenSigSendType" SG_ 878 ClimtRearPnlFlr2_B_Stat 3;
BA_ "U_T6_MCA_MY2020_Rx" SG_ 878 ClimtRearPnl2_B_Stat 1;
BA_ "GenSigSendType" SG_ 878 ClimtRearPnl2_B_Stat 3;
BA_ "U_T6_MCA_MY2020_Rx" SG_ 878 ClimtRearFlr2_B_Stat 1;
BA_ "GenSigSendType" SG_ 878 ClimtRearFlr2_B_Stat 3;
BA_ "U_T6_MCA_MY2020_Rx" SG_ 878 ClimtRearBlwr2_D_Stat 1;
BA_ "GenSigSendType" SG_ 878 ClimtRearBlwr2_D_Stat 3;
BA_ "U_T6_MCA_MY2020_Rx" SG_ 878 ClimtRearBlwr2_An_Actl 1;
BA_ "GenSigSendType" SG_ 878 ClimtRearBlwr2_An_Actl 3;
BA_ "GenSigStartValue" SG_ 878 ClimtRearBlwr2_An_Actl 511;
BA_ "GenSigStartValueInteger" SG_ 878 ClimtRearBlwr2_An_Actl 511;
BA_ "U_T6_MCA_MY2020_Rx" SG_ 878 ClimtRearAuto2_B_Stat 1;
BA_ "GenSigSendType" SG_ 878 ClimtRearAuto2_B_Stat 3;
BA_ "U_U55X_MY2022_Tx" SG_ 1448 SCMF_GWOnBoardTester 1;
BA_ "GenSigStartValue" SG_ 1448 SCMF_GWOnBoardTester 255;
BA_ "ContentDependant" SG_ 1448 SCMF_GWOnBoardTester 1;
BA_ "GenSigStartValueInteger" SG_ 1448 SCMF_GWOnBoardTester 255;
BA_ "U_U55X_MY2022_Tx" SG_ 1448 SCMF_GWNMProxy 1;
BA_ "GenSigStartValue" SG_ 1448 SCMF_GWNMProxy 255;
BA_ "ContentDependant" SG_ 1448 SCMF_GWNMProxy 1;
BA_ "GenSigStartValueInteger" SG_ 1448 SCMF_GWNMProxy 255;
BA_ "U_U55X_MY2022_Tx" SG_ 1448 SCMF_AutoSarNMReserved4 1;
BA_ "GenSigStartValue" SG_ 1448 SCMF_AutoSarNMReserved4 255;
BA_ "ContentDependant" SG_ 1448 SCMF_AutoSarNMReserved4 1;
BA_ "GenSigStartValueInteger" SG_ 1448 SCMF_AutoSarNMReserved4 255;
BA_ "U_U55X_MY2022_Tx" SG_ 1448 SCMF_AutoSarNMReserved3 1;
BA_ "GenSigStartValue" SG_ 1448 SCMF_AutoSarNMReserved3 255;
BA_ "ContentDependant" SG_ 1448 SCMF_AutoSarNMReserved3 1;
BA_ "GenSigStartValueInteger" SG_ 1448 SCMF_AutoSarNMReserved3 255;
BA_ "U_U55X_MY2022_Tx" SG_ 1448 SCMF_AutoSarNMReserved2 1;
BA_ "GenSigStartValue" SG_ 1448 SCMF_AutoSarNMReserved2 255;
BA_ "ContentDependant" SG_ 1448 SCMF_AutoSarNMReserved2 1;
BA_ "GenSigStartValueInteger" SG_ 1448 SCMF_AutoSarNMReserved2 255;
BA_ "U_U55X_MY2022_Tx" SG_ 1448 SCMF_AutoSarNMReserved1 1;
BA_ "GenSigStartValue" SG_ 1448 SCMF_AutoSarNMReserved1 255;
BA_ "ContentDependant" SG_ 1448 SCMF_AutoSarNMReserved1 1;
BA_ "GenSigStartValueInteger" SG_ 1448 SCMF_AutoSarNMReserved1 255;
BA_ "U_U55X_MY2022_Tx" SG_ 1448 SCMF_AutoSarNMNodeId 1;
BA_ "GenSigStartValue" SG_ 1448 SCMF_AutoSarNMNodeId 168;
BA_ "ContentDependant" SG_ 1448 SCMF_AutoSarNMNodeId 1;
BA_ "GenSigStartValueInteger" SG_ 1448 SCMF_AutoSarNMNodeId 168;
BA_ "U_U55X_MY2022_Tx" SG_ 1448 SCMF_AutoSarNMControl 1;
BA_ "ContentDependant" SG_ 1448 SCMF_AutoSarNMControl 1;
BA_ "U_U55X_MY2022_Tx" SG_ 1447 SCME_GWOnBoardTester 1;
BA_ "U_P702_MY2021_Tx" SG_ 1447 SCME_GWOnBoardTester 1;
BA_ "GenSigStartValue" SG_ 1447 SCME_GWOnBoardTester 255;
BA_ "ContentDependant" SG_ 1447 SCME_GWOnBoardTester 1;
BA_ "GenSigStartValueInteger" SG_ 1447 SCME_GWOnBoardTester 255;
BA_ "U_U55X_MY2022_Tx" SG_ 1447 SCME_GWNMProxy 1;
BA_ "U_P702_MY2021_Tx" SG_ 1447 SCME_GWNMProxy 1;
BA_ "GenSigStartValue" SG_ 1447 SCME_GWNMProxy 255;
BA_ "ContentDependant" SG_ 1447 SCME_GWNMProxy 1;
BA_ "GenSigStartValueInteger" SG_ 1447 SCME_GWNMProxy 255;
BA_ "U_U55X_MY2022_Tx" SG_ 1447 SCME_AutoSarNMReserved4 1;
BA_ "U_P702_MY2021_Tx" SG_ 1447 SCME_AutoSarNMReserved4 1;
BA_ "GenSigStartValue" SG_ 1447 SCME_AutoSarNMReserved4 255;
BA_ "ContentDependant" SG_ 1447 SCME_AutoSarNMReserved4 1;
BA_ "GenSigStartValueInteger" SG_ 1447 SCME_AutoSarNMReserved4 255;
BA_ "U_U55X_MY2022_Tx" SG_ 1447 SCME_AutoSarNMReserved3 1;
BA_ "U_P702_MY2021_Tx" SG_ 1447 SCME_AutoSarNMReserved3 1;
BA_ "GenSigStartValue" SG_ 1447 SCME_AutoSarNMReserved3 255;
BA_ "ContentDependant" SG_ 1447 SCME_AutoSarNMReserved3 1;
BA_ "GenSigStartValueInteger" SG_ 1447 SCME_AutoSarNMReserved3 255;
BA_ "U_U55X_MY2022_Tx" SG_ 1447 SCME_AutoSarNMReserved2 1;
BA_ "U_P702_MY2021_Tx" SG_ 1447 SCME_AutoSarNMReserved2 1;
BA_ "GenSigStartValue" SG_ 1447 SCME_AutoSarNMReserved2 255;
BA_ "ContentDependant" SG_ 1447 SCME_AutoSarNMReserved2 1;
BA_ "GenSigStartValueInteger" SG_ 1447 SCME_AutoSarNMReserved2 255;
BA_ "U_U55X_MY2022_Tx" SG_ 1447 SCME_AutoSarNMReserved1 1;
BA_ "U_P702_MY2021_Tx" SG_ 1447 SCME_AutoSarNMReserved1 1;
BA_ "GenSigStartValue" SG_ 1447 SCME_AutoSarNMReserved1 255;
BA_ "ContentDependant" SG_ 1447 SCME_AutoSarNMReserved1 1;
BA_ "GenSigStartValueInteger" SG_ 1447 SCME_AutoSarNMReserved1 255;
BA_ "U_U55X_MY2022_Tx" SG_ 1447 SCME_AutoSarNMNodeId 1;
BA_ "U_P702_MY2021_Tx" SG_ 1447 SCME_AutoSarNMNodeId 1;
BA_ "GenSigStartValue" SG_ 1447 SCME_AutoSarNMNodeId 167;
BA_ "ContentDependant" SG_ 1447 SCME_AutoSarNMNodeId 1;
BA_ "GenSigStartValueInteger" SG_ 1447 SCME_AutoSarNMNodeId 167;
BA_ "U_U55X_MY2022_Tx" SG_ 1447 SCME_AutoSarNMControl 1;
BA_ "U_P702_MY2021_Tx" SG_ 1447 SCME_AutoSarNMControl 1;
BA_ "ContentDependant" SG_ 1447 SCME_AutoSarNMControl 1;
BA_ "U_CD764_MY2022_Tx" SG_ 1419 DSM_GWOnBoardTester 1;
BA_ "U_U55X_MY2022_Tx" SG_ 1419 DSM_GWOnBoardTester 1;
BA_ "U_CD542_MY2021_Tx" SG_ 1419 DSM_GWOnBoardTester 1;
BA_ "U_T6_MCA_MY2020_Tx" SG_ 1419 DSM_GWOnBoardTester 1;
BA_ "U_P702_MY2021_Tx" SG_ 1419 DSM_GWOnBoardTester 1;
BA_ "GenSigStartValue" SG_ 1419 DSM_GWOnBoardTester 255;
BA_ "ContentDependant" SG_ 1419 DSM_GWOnBoardTester 1;
BA_ "GenSigStartValueInteger" SG_ 1419 DSM_GWOnBoardTester 255;
BA_ "U_CD764_MY2022_Tx" SG_ 1419 DSM_GWNMProxy 1;
BA_ "U_U55X_MY2022_Tx" SG_ 1419 DSM_GWNMProxy 1;
BA_ "U_CD542_MY2021_Tx" SG_ 1419 DSM_GWNMProxy 1;
BA_ "U_T6_MCA_MY2020_Tx" SG_ 1419 DSM_GWNMProxy 1;
BA_ "U_P702_MY2021_Tx" SG_ 1419 DSM_GWNMProxy 1;
BA_ "GenSigStartValue" SG_ 1419 DSM_GWNMProxy 255;
BA_ "ContentDependant" SG_ 1419 DSM_GWNMProxy 1;
BA_ "GenSigStartValueInteger" SG_ 1419 DSM_GWNMProxy 255;
BA_ "U_CD764_MY2022_Tx" SG_ 1419 DSM_AutoSarNMReserved4 1;
BA_ "U_U55X_MY2022_Tx" SG_ 1419 DSM_AutoSarNMReserved4 1;
BA_ "U_CD542_MY2021_Tx" SG_ 1419 DSM_AutoSarNMReserved4 1;
BA_ "U_T6_MCA_MY2020_Tx" SG_ 1419 DSM_AutoSarNMReserved4 1;
BA_ "U_P702_MY2021_Tx" SG_ 1419 DSM_AutoSarNMReserved4 1;
BA_ "GenSigStartValue" SG_ 1419 DSM_AutoSarNMReserved4 255;
BA_ "ContentDependant" SG_ 1419 DSM_AutoSarNMReserved4 1;
BA_ "GenSigStartValueInteger" SG_ 1419 DSM_AutoSarNMReserved4 255;
BA_ "U_CD764_MY2022_Tx" SG_ 1419 DSM_AutoSarNMReserved3 1;
BA_ "U_U55X_MY2022_Tx" SG_ 1419 DSM_AutoSarNMReserved3 1;
BA_ "U_CD542_MY2021_Tx" SG_ 1419 DSM_AutoSarNMReserved3 1;
BA_ "U_T6_MCA_MY2020_Tx" SG_ 1419 DSM_AutoSarNMReserved3 1;
BA_ "U_P702_MY2021_Tx" SG_ 1419 DSM_AutoSarNMReserved3 1;
BA_ "GenSigStartValue" SG_ 1419 DSM_AutoSarNMReserved3 255;
BA_ "ContentDependant" SG_ 1419 DSM_AutoSarNMReserved3 1;
BA_ "GenSigStartValueInteger" SG_ 1419 DSM_AutoSarNMReserved3 255;
BA_ "U_CD764_MY2022_Tx" SG_ 1419 DSM_AutoSarNMReserved2 1;
BA_ "U_U55X_MY2022_Tx" SG_ 1419 DSM_AutoSarNMReserved2 1;
BA_ "U_CD542_MY2021_Tx" SG_ 1419 DSM_AutoSarNMReserved2 1;
BA_ "U_T6_MCA_MY2020_Tx" SG_ 1419 DSM_AutoSarNMReserved2 1;
BA_ "U_P702_MY2021_Tx" SG_ 1419 DSM_AutoSarNMReserved2 1;
BA_ "GenSigStartValue" SG_ 1419 DSM_AutoSarNMReserved2 255;
BA_ "ContentDependant" SG_ 1419 DSM_AutoSarNMReserved2 1;
BA_ "GenSigStartValueInteger" SG_ 1419 DSM_AutoSarNMReserved2 255;
BA_ "U_CD764_MY2022_Tx" SG_ 1419 DSM_AutoSarNMReserved1 1;
BA_ "U_U55X_MY2022_Tx" SG_ 1419 DSM_AutoSarNMReserved1 1;
BA_ "U_CD542_MY2021_Tx" SG_ 1419 DSM_AutoSarNMReserved1 1;
BA_ "U_T6_MCA_MY2020_Tx" SG_ 1419 DSM_AutoSarNMReserved1 1;
BA_ "U_P702_MY2021_Tx" SG_ 1419 DSM_AutoSarNMReserved1 1;
BA_ "GenSigStartValue" SG_ 1419 DSM_AutoSarNMReserved1 255;
BA_ "ContentDependant" SG_ 1419 DSM_AutoSarNMReserved1 1;
BA_ "GenSigStartValueInteger" SG_ 1419 DSM_AutoSarNMReserved1 255;
BA_ "U_CD764_MY2022_Tx" SG_ 1419 DSM_AutoSarNMNodeId 1;
BA_ "U_U55X_MY2022_Tx" SG_ 1419 DSM_AutoSarNMNodeId 1;
BA_ "U_CD542_MY2021_Tx" SG_ 1419 DSM_AutoSarNMNodeId 1;
BA_ "U_T6_MCA_MY2020_Tx" SG_ 1419 DSM_AutoSarNMNodeId 1;
BA_ "U_P702_MY2021_Tx" SG_ 1419 DSM_AutoSarNMNodeId 1;
BA_ "GenSigStartValue" SG_ 1419 DSM_AutoSarNMNodeId 139;
BA_ "ContentDependant" SG_ 1419 DSM_AutoSarNMNodeId 1;
BA_ "GenSigStartValueInteger" SG_ 1419 DSM_AutoSarNMNodeId 139;
BA_ "U_CD764_MY2022_Tx" SG_ 1419 DSM_AutoSarNMControl 1;
BA_ "U_U55X_MY2022_Tx" SG_ 1419 DSM_AutoSarNMControl 1;
BA_ "U_CD542_MY2021_Tx" SG_ 1419 DSM_AutoSarNMControl 1;
BA_ "U_T6_MCA_MY2020_Tx" SG_ 1419 DSM_AutoSarNMControl 1;
BA_ "U_P702_MY2021_Tx" SG_ 1419 DSM_AutoSarNMControl 1;
BA_ "ContentDependant" SG_ 1419 DSM_AutoSarNMControl 1;
BA_ "MetaData" SG_ 1247 StopLampBRqTrlrAft_No_Cs 1;
BA_ "MetaData" SG_ 1247 StopLampBRqTrlrAft_No_Cnt 1;
BA_ "U_CD542_MY2021_Rx" SG_ 1417 SOBDMD_GWOnBoardTester 1;
BA_ "ECGUsedRxSignal" SG_ 1417 SOBDMD_GWOnBoardTester 1;
BA_ "U_T6_MCA_MY2020_Rx" SG_ 1417 SOBDMD_GWOnBoardTester 1;
BA_ "GenSigStartValue" SG_ 1417 SOBDMD_GWOnBoardTester 255;
BA_ "ContentDependant" SG_ 1417 SOBDMD_GWOnBoardTester 1;
BA_ "GenSigStartValueInteger" SG_ 1417 SOBDMD_GWOnBoardTester 255;
BA_ "U_CD542_MY2021_Rx" SG_ 1417 SOBDMD_GWNMProxy 1;
BA_ "ECGUsedRxSignal" SG_ 1417 SOBDMD_GWNMProxy 1;
BA_ "U_T6_MCA_MY2020_Rx" SG_ 1417 SOBDMD_GWNMProxy 1;
BA_ "GenSigStartValue" SG_ 1417 SOBDMD_GWNMProxy 255;
BA_ "ContentDependant" SG_ 1417 SOBDMD_GWNMProxy 1;
BA_ "GenSigStartValueInteger" SG_ 1417 SOBDMD_GWNMProxy 255;
BA_ "U_CD542_MY2021_Rx" SG_ 1417 SOBDMD_AutoSarNMReserved4 1;
BA_ "ECGUsedRxSignal" SG_ 1417 SOBDMD_AutoSarNMReserved4 1;
BA_ "U_T6_MCA_MY2020_Rx" SG_ 1417 SOBDMD_AutoSarNMReserved4 1;
BA_ "GenSigStartValue" SG_ 1417 SOBDMD_AutoSarNMReserved4 255;
BA_ "ContentDependant" SG_ 1417 SOBDMD_AutoSarNMReserved4 1;
BA_ "GenSigStartValueInteger" SG_ 1417 SOBDMD_AutoSarNMReserved4 255;
BA_ "U_CD542_MY2021_Rx" SG_ 1417 SOBDMD_AutoSarNMReserved3 1;
BA_ "ECGUsedRxSignal" SG_ 1417 SOBDMD_AutoSarNMReserved3 1;
BA_ "U_T6_MCA_MY2020_Rx" SG_ 1417 SOBDMD_AutoSarNMReserved3 1;
BA_ "GenSigStartValue" SG_ 1417 SOBDMD_AutoSarNMReserved3 255;
BA_ "ContentDependant" SG_ 1417 SOBDMD_AutoSarNMReserved3 1;
BA_ "GenSigStartValueInteger" SG_ 1417 SOBDMD_AutoSarNMReserved3 255;
BA_ "U_CD542_MY2021_Rx" SG_ 1417 SOBDMD_AutoSarNMReserved2 1;
BA_ "ECGUsedRxSignal" SG_ 1417 SOBDMD_AutoSarNMReserved2 1;
BA_ "U_T6_MCA_MY2020_Rx" SG_ 1417 SOBDMD_AutoSarNMReserved2 1;
BA_ "GenSigStartValue" SG_ 1417 SOBDMD_AutoSarNMReserved2 255;
BA_ "ContentDependant" SG_ 1417 SOBDMD_AutoSarNMReserved2 1;
BA_ "GenSigStartValueInteger" SG_ 1417 SOBDMD_AutoSarNMReserved2 255;
BA_ "U_CD542_MY2021_Rx" SG_ 1417 SOBDMD_AutoSarNMReserved1 1;
BA_ "ECGUsedRxSignal" SG_ 1417 SOBDMD_AutoSarNMReserved1 1;
BA_ "U_T6_MCA_MY2020_Rx" SG_ 1417 SOBDMD_AutoSarNMReserved1 1;
BA_ "GenSigStartValue" SG_ 1417 SOBDMD_AutoSarNMReserved1 255;
BA_ "ContentDependant" SG_ 1417 SOBDMD_AutoSarNMReserved1 1;
BA_ "GenSigStartValueInteger" SG_ 1417 SOBDMD_AutoSarNMReserved1 255;
BA_ "U_CD542_MY2021_Rx" SG_ 1417 SOBDMD_AutoSarNMNodeId 1;
BA_ "ECGUsedRxSignal" SG_ 1417 SOBDMD_AutoSarNMNodeId 1;
BA_ "U_T6_MCA_MY2020_Rx" SG_ 1417 SOBDMD_AutoSarNMNodeId 1;
BA_ "GenSigStartValue" SG_ 1417 SOBDMD_AutoSarNMNodeId 137;
BA_ "ContentDependant" SG_ 1417 SOBDMD_AutoSarNMNodeId 1;
BA_ "GenSigStartValueInteger" SG_ 1417 SOBDMD_AutoSarNMNodeId 185;
BA_ "U_CD542_MY2021_Rx" SG_ 1417 SOBDMD_AutoSarNMControl 1;
BA_ "ECGUsedRxSignal" SG_ 1417 SOBDMD_AutoSarNMControl 1;
BA_ "U_T6_MCA_MY2020_Rx" SG_ 1417 SOBDMD_AutoSarNMControl 1;
BA_ "ContentDependant" SG_ 1417 SOBDMD_AutoSarNMControl 1;
BA_ "U_T6_MCA_MY2020_Tx" SG_ 672 BCP_Audible_Beep_Rq 1;
BA_ "GenSigSendType" SG_ 672 BCP_Audible_Beep_Rq 3;
BA_ "U_T6_MCA_MY2020_Tx" SG_ 672 SetVolume 1;
BA_ "GenSigSendType" SG_ 672 SetVolume 3;
BA_ "GenSigStartValue" SG_ 672 SetVolume 30;
BA_ "GenSigStartValueInteger" SG_ 672 SetVolume 30;
BA_ "WakeupSignal" SG_ 672 SetVolume 1;
BA_ "U_T6_MCA_MY2020_Tx" SG_ 672 SetPointVolume 1;
BA_ "GenSigSendType" SG_ 672 SetPointVolume 3;
BA_ "WakeupSignal" SG_ 672 SetPointVolume 1;
BA_ "U_T6_MCA_MY2020_Tx" SG_ 672 Coding_BtnID_D 1;
BA_ "GenSigSendType" SG_ 672 Coding_BtnID_D 3;
BA_ "WakeupSignal" SG_ 672 Coding_BtnID_D 1;
BA_ "U_T6_MCA_MY2020_Tx" SG_ 672 Coding_BtnID_C 1;
BA_ "GenSigSendType" SG_ 672 Coding_BtnID_C 3;
BA_ "WakeupSignal" SG_ 672 Coding_BtnID_C 1;
BA_ "U_T6_MCA_MY2020_Tx" SG_ 672 Coding_BtnID_B 1;
BA_ "GenSigSendType" SG_ 672 Coding_BtnID_B 3;
BA_ "WakeupSignal" SG_ 672 Coding_BtnID_B 1;
BA_ "U_T6_MCA_MY2020_Tx" SG_ 672 Coding_BtnID_A 1;
BA_ "GenSigSendType" SG_ 672 Coding_BtnID_A 3;
BA_ "WakeupSignal" SG_ 672 Coding_BtnID_A 1;
BA_ "U_T6_MCA_MY2020_Tx" SG_ 672 BtnID_D 1;
BA_ "GenSigStartValue" SG_ 672 BtnID_D 255;
BA_ "GenSigStartValueInteger" SG_ 672 BtnID_D 255;
BA_ "WakeupSignal" SG_ 672 BtnID_D 1;
BA_ "U_T6_MCA_MY2020_Tx" SG_ 672 BtnID_C 1;
BA_ "GenSigStartValue" SG_ 672 BtnID_C 255;
BA_ "GenSigStartValueInteger" SG_ 672 BtnID_C 255;
BA_ "WakeupSignal" SG_ 672 BtnID_C 1;
BA_ "U_T6_MCA_MY2020_Tx" SG_ 672 BtnID_B 1;
BA_ "GenSigStartValue" SG_ 672 BtnID_B 255;
BA_ "GenSigStartValueInteger" SG_ 672 BtnID_B 255;
BA_ "WakeupSignal" SG_ 672 BtnID_B 1;
BA_ "U_T6_MCA_MY2020_Tx" SG_ 672 BtnID_A 1;
BA_ "GenSigStartValue" SG_ 672 BtnID_A 255;
BA_ "GenSigStartValueInteger" SG_ 672 BtnID_A 255;
BA_ "WakeupSignal" SG_ 672 BtnID_A 1;
BA_ "GenSigStartValue" SG_ 796 BattULoChrg_URate_RqMx 5;
BA_ "GenSigStartValueInteger" SG_ 796 BattULoChrg_URate_RqMx 5;
BA_ "GenSigStartValue" SG_ 796 BattULoChrg_U_RqMx 34;
BA_ "GenSigStartValueInteger" SG_ 796 BattULoChrg_U_RqMx 34;
BA_ "U_CD764_MY2022_Rx" SG_ 796 BattULoState_D_Qlty 1;
BA_ "U_U55X_MY2022_Rx" SG_ 796 BattULoState_D_Qlty 1;
BA_ "U_CD542_MY2021_Rx" SG_ 796 BattULoState_D_Qlty 1;
BA_ "U_T6_MCA_MY2020_Rx" SG_ 796 BattULoState_D_Qlty 1;
BA_ "U_P702_MY2021_Rx" SG_ 796 BattULoState_D_Qlty 1;
BA_ "U_CX727_MY2021_Rx" SG_ 796 BattULoState_D_Qlty 1;
BA_ "U_CD764_MY2022_Rx" SG_ 796 BSFault 1;
BA_ "U_U55X_MY2022_Rx" SG_ 796 BSFault 1;
BA_ "U_CD542_MY2021_Rx" SG_ 796 BSFault 1;
BA_ "U_T6_MCA_MY2020_Rx" SG_ 796 BSFault 1;
BA_ "U_P702_MY2021_Rx" SG_ 796 BSFault 1;
BA_ "U_CX727_MY2021_Rx" SG_ 796 BSFault 1;
BA_ "U_CD764_MY2022_Rx" SG_ 796 BattULo2_Te_Actl 1;
BA_ "U_U55X_MY2022_Rx" SG_ 796 BattULo2_Te_Actl 1;
BA_ "U_CD542_MY2021_Rx" SG_ 796 BattULo2_Te_Actl 1;
BA_ "U_T6_MCA_MY2020_Rx" SG_ 796 BattULo2_Te_Actl 1;
BA_ "U_P702_MY2021_Rx" SG_ 796 BattULo2_Te_Actl 1;
BA_ "U_CX727_MY2021_Rx" SG_ 796 BattULo2_Te_Actl 1;
BA_ "GenSigStartValue" SG_ 796 BattULo2_Te_Actl 127;
BA_ "GenSigStartValueInteger" SG_ 796 BattULo2_Te_Actl 127;
BA_ "U_CD764_MY2022_Rx" SG_ 796 BSBattSOC 1;
BA_ "U_U55X_MY2022_Rx" SG_ 796 BSBattSOC 1;
BA_ "U_CD542_MY2021_Rx" SG_ 796 BSBattSOC 1;
BA_ "U_T6_MCA_MY2020_Rx" SG_ 796 BSBattSOC 1;
BA_ "U_P702_MY2021_Rx" SG_ 796 BSBattSOC 1;
BA_ "U_CX727_MY2021_Rx" SG_ 796 BSBattSOC 1;
BA_ "GenSigStartValueInteger" SG_ 796 BSBattQDeltaRideAh 12800;
BA_ "U_U55X_MY2022_Tx" SG_ 2610127023 OTAPhysRGTMtoGWM_ECG 1;
BA_ "U_CD764_MY2022_Rx" SG_ 2610127023 OTAPhysRGTMtoGWM_ECG 1;
BA_ "U_CD542_MY2021_Rx" SG_ 2610127023 OTAPhysRGTMtoGWM_ECG 1;
BA_ "ECGUsedRxSignal" SG_ 2610127023 OTAPhysRGTMtoGWM_ECG 1;
BA_ "GenSigSendType" SG_ 2610127023 OTAPhysRGTMtoGWM_ECG 3;
BA_ "U_CD542_MY2021_Tx" SG_ 2612077784 PARSEDPushFcGWM_ECGtoRSM 1;
BA_ "ECGUsedTxSignal" SG_ 2612077784 PARSEDPushFcGWM_ECGtoRSM 1;
BA_ "U_T6_MCA_MY2020_Tx" SG_ 2612077784 PARSEDPushFcGWM_ECGtoRSM 1;
BA_ "U_U55X_MY2022_Rx" SG_ 2612077784 PARSEDPushFcGWM_ECGtoRSM 1;
BA_ "U_T6_MCA_MY2020_Rx" SG_ 2612077784 PARSEDPushFcGWM_ECGtoRSM 1;
BA_ "GenSigSendType" SG_ 2612077784 PARSEDPushFcGWM_ECGtoRSM 3;
BA_ "U_U55X_MY2022_Tx" SG_ 2611175497 PARSEDPhysRSMtoGWM_ECG 1;
BA_ "U_T6_MCA_MY2020_Tx" SG_ 2611175497 PARSEDPhysRSMtoGWM_ECG 1;
BA_ "U_CD542_MY2021_Rx" SG_ 2611175497 PARSEDPhysRSMtoGWM_ECG 1;
BA_ "ECGUsedRxSignal" SG_ 2611175497 PARSEDPhysRSMtoGWM_ECG 1;
BA_ "U_T6_MCA_MY2020_Rx" SG_ 2611175497 PARSEDPhysRSMtoGWM_ECG 1;
BA_ "GenSigSendType" SG_ 2611175497 PARSEDPhysRSMtoGWM_ECG 3;
BA_ "U_CD542_MY2021_Tx" SG_ 2611029208 PARSEDPhysGWM_ECGtoRSM 1;
BA_ "ECGUsedTxSignal" SG_ 2611029208 PARSEDPhysGWM_ECGtoRSM 1;
BA_ "U_T6_MCA_MY2020_Tx" SG_ 2611029208 PARSEDPhysGWM_ECGtoRSM 1;
BA_ "U_U55X_MY2022_Rx" SG_ 2611029208 PARSEDPhysGWM_ECGtoRSM 1;
BA_ "U_T6_MCA_MY2020_Rx" SG_ 2611029208 PARSEDPhysGWM_ECGtoRSM 1;
BA_ "GenSigSendType" SG_ 2611029208 PARSEDPhysGWM_ECGtoRSM 3;
BA_ "U_CD542_MY2021_Tx" SG_ 1364 TRM_Network_Mgmt 1;
BA_ "U_T6_MCA_MY2020_Tx" SG_ 1364 TRM_Network_Mgmt 1;
BA_ "U_P702_MY2021_Tx" SG_ 1364 TRM_Network_Mgmt 1;
BA_ "U_CD764_MY2022_Rx" SG_ 1364 TRM_Network_Mgmt 1;
BA_ "U_P702_MY2021_Rx" SG_ 1364 TRM_Network_Mgmt 1;
BA_ "GenSigSendType" SG_ 1364 TRM_Network_Mgmt 3;
BA_ "U_U55X_MY2022_Tx" SG_ 2610126921 OTAPhysRSMtoGWM_ECG 1;
BA_ "U_T6_MCA_MY2020_Tx" SG_ 2610126921 OTAPhysRSMtoGWM_ECG 1;
BA_ "U_CD542_MY2021_Rx" SG_ 2610126921 OTAPhysRSMtoGWM_ECG 1;
BA_ "ECGUsedRxSignal" SG_ 2610126921 OTAPhysRSMtoGWM_ECG 1;
BA_ "U_T6_MCA_MY2020_Rx" SG_ 2610126921 OTAPhysRSMtoGWM_ECG 1;
BA_ "GenSigSendType" SG_ 2610126921 OTAPhysRSMtoGWM_ECG 3;
BA_ "U_CD542_MY2021_Tx" SG_ 2609980632 OTAPhysGWM_ECGtoRSM 1;
BA_ "ECGUsedTxSignal" SG_ 2609980632 OTAPhysGWM_ECGtoRSM 1;
BA_ "U_T6_MCA_MY2020_Tx" SG_ 2609980632 OTAPhysGWM_ECGtoRSM 1;
BA_ "U_U55X_MY2022_Rx" SG_ 2609980632 OTAPhysGWM_ECGtoRSM 1;
BA_ "U_T6_MCA_MY2020_Rx" SG_ 2609980632 OTAPhysGWM_ECGtoRSM 1;
BA_ "GenSigSendType" SG_ 2609980632 OTAPhysGWM_ECGtoRSM 3;
BA_ "U_U55X_MY2022_Rx" SG_ 677 SeatFnPsgr_D_Rq3 1;
BA_ "U_U55X_MY2022_Rx" SG_ 677 SeatFnDrv_D_Rq3 1;
BA_ "U_U55X_MY2022_Rx" SG_ 677 SeatMasgPsngrRr_D_Rq2 1;
BA_ "U_U55X_MY2022_Rx" SG_ 677 SeatMasgDrvRr_D_Rq2 1;
BA_ "U_U55X_MY2022_Rx" SG_ 677 SeatFnChngPsgr2_D_Rq3 1;
BA_ "U_U55X_MY2022_Rx" SG_ 677 SeatFnChngDrv2_D_Rq3 1;
BA_ "U_U55X_MY2022_Tx" SG_ 2612224073 PARSEDPushRSMtoGWM_ECG 1;
BA_ "U_T6_MCA_MY2020_Tx" SG_ 2612224073 PARSEDPushRSMtoGWM_ECG 1;
BA_ "U_CD542_MY2021_Rx" SG_ 2612224073 PARSEDPushRSMtoGWM_ECG 1;
BA_ "ECGUsedRxSignal" SG_ 2612224073 PARSEDPushRSMtoGWM_ECG 1;
BA_ "U_T6_MCA_MY2020_Rx" SG_ 2612224073 PARSEDPushRSMtoGWM_ECG 1;
BA_ "GenSigSendType" SG_ 2612224073 PARSEDPushRSMtoGWM_ECG 3;
BA_ "GenSigSendType" SG_ 1320 SCMF_Network_Mgmt 3;
BA_ "GenSigSendType" SG_ 1319 SCME_Network_Mgmt 3;
BA_ "GenSigSendType" SG_ 1368 SCMB_PSM_Network_Mgmt 3;
BA_ "U_P702_MY2021_Tx" SG_ 1339 RTM_Network_Mgmt 1;
BA_ "U_CX727_MY2021_Tx" SG_ 1339 RTM_Network_Mgmt 1;
BA_ "U_T6_MCA_MY2020_Rx" SG_ 1339 RTM_Network_Mgmt 1;
BA_ "GenSigSendType" SG_ 1339 RTM_Network_Mgmt 3;
BA_ "U_U55X_MY2022_Rx" SG_ 486 ACU_ARAudioSource_Rsp 1;
BA_ "U_T6_MCA_MY2020_Rx" SG_ 486 ACU_ARAudioSource_Rsp 1;
BA_ "U_U55X_MY2022_Rx" SG_ 486 ACU_AROperationType_Rsp 1;
BA_ "U_T6_MCA_MY2020_Rx" SG_ 486 ACU_AROperationType_Rsp 1;
BA_ "U_U55X_MY2022_Rx" SG_ 486 ACU_ARReqstrSystem_Rsp 1;
BA_ "U_T6_MCA_MY2020_Rx" SG_ 486 ACU_ARReqstrSystem_Rsp 1;
BA_ "U_U55X_MY2022_Rx" SG_ 486 ACU_ARResponse_Rsp 1;
BA_ "U_T6_MCA_MY2020_Rx" SG_ 486 ACU_ARResponse_Rsp 1;
BA_ "U_U55X_MY2022_Rx" SG_ 486 ACU_ARReqstrPriority_Rp 1;
BA_ "U_T6_MCA_MY2020_Rx" SG_ 486 ACU_ARReqstrPriority_Rp 1;
BA_ "U_U55X_MY2022_Rx" SG_ 486 ACU_RUAudioSource_St 1;
BA_ "U_T6_MCA_MY2020_Rx" SG_ 486 ACU_RUAudioSource_St 1;
BA_ "U_U55X_MY2022_Rx" SG_ 486 ACU_RUReqstrSystem_St 1;
BA_ "U_T6_MCA_MY2020_Rx" SG_ 486 ACU_RUReqstrSystem_St 1;
BA_ "U_U55X_MY2022_Rx" SG_ 486 ACU_RUResReqstStatus_St 1;
BA_ "U_T6_MCA_MY2020_Rx" SG_ 486 ACU_RUResReqstStatus_St 1;
BA_ "U_U55X_MY2022_Rx" SG_ 486 ACU_RUReqstrPriority_St 1;
BA_ "U_T6_MCA_MY2020_Rx" SG_ 486 ACU_RUReqstrPriority_St 1;
BA_ "U_U55X_MY2022_Tx" SG_ 1383 RSM_Network_Mgmt 1;
BA_ "U_T6_MCA_MY2020_Tx" SG_ 1383 RSM_Network_Mgmt 1;
BA_ "U_P702_MY2021_Tx" SG_ 1383 RSM_Network_Mgmt 1;
BA_ "U_CX727_MY2021_Tx" SG_ 1383 RSM_Network_Mgmt 1;
BA_ "U_T6_MCA_MY2020_Rx" SG_ 1383 RSM_Network_Mgmt 1;
BA_ "GenSigSendType" SG_ 1383 RSM_Network_Mgmt 3;
BA_ "U_U55X_MY2022_Tx" SG_ 2611175599 PARSEDPhysRGTMtoGWM_ECG 1;
BA_ "U_CD542_MY2021_Rx" SG_ 2611175599 PARSEDPhysRGTMtoGWM_ECG 1;
BA_ "ECGUsedRxSignal" SG_ 2611175599 PARSEDPhysRGTMtoGWM_ECG 1;
BA_ "GenSigSendType" SG_ 2611175599 PARSEDPhysRGTMtoGWM_ECG 3;
BA_ "U_U55X_MY2022_Tx" SG_ 2612224175 PARSEDPushRGTMtoGWM_ECG 1;
BA_ "U_CD542_MY2021_Rx" SG_ 2612224175 PARSEDPushRGTMtoGWM_ECG 1;
BA_ "ECGUsedRxSignal" SG_ 2612224175 PARSEDPushRGTMtoGWM_ECG 1;
BA_ "GenSigSendType" SG_ 2612224175 PARSEDPushRGTMtoGWM_ECG 3;
BA_ "U_T6_MCA_MY2020_Tx" SG_ 1352 RHVAC_Network_Mgmt 1;
BA_ "GenSigSendType" SG_ 1352 RHVAC_Network_Mgmt 3;
BA_ "U_P702_MY2021_Rx" SG_ 1318 RGTM_Network_Mgmt 1;
BA_ "GenSigSendType" SG_ 1318 RGTM_Network_Mgmt 3;
BA_ "U_CD764_MY2022_Tx" SG_ 2612224164 PARSEDPushPDMtoGWM_ECG 1;
BA_ "U_U55X_MY2022_Tx" SG_ 2612224164 PARSEDPushPDMtoGWM_ECG 1;
BA_ "U_T6_MCA_MY2020_Tx" SG_ 2612224164 PARSEDPushPDMtoGWM_ECG 1;
BA_ "U_CD764_MY2022_Rx" SG_ 2612224164 PARSEDPushPDMtoGWM_ECG 1;
BA_ "U_U55X_MY2022_Rx" SG_ 2612224164 PARSEDPushPDMtoGWM_ECG 1;
BA_ "U_CD542_MY2021_Rx" SG_ 2612224164 PARSEDPushPDMtoGWM_ECG 1;
BA_ "ECGUsedRxSignal" SG_ 2612224164 PARSEDPushPDMtoGWM_ECG 1;
BA_ "U_T6_MCA_MY2020_Rx" SG_ 2612224164 PARSEDPushPDMtoGWM_ECG 1;
BA_ "GenSigSendType" SG_ 2612224164 PARSEDPushPDMtoGWM_ECG 3;
BA_ "U_CD764_MY2022_Tx" SG_ 2612170968 PARSEDPushFcGWM_ECGtoPDM 1;
BA_ "U_U55X_MY2022_Tx" SG_ 2612170968 PARSEDPushFcGWM_ECGtoPDM 1;
BA_ "U_CD542_MY2021_Tx" SG_ 2612170968 PARSEDPushFcGWM_ECGtoPDM 1;
BA_ "ECGUsedTxSignal" SG_ 2612170968 PARSEDPushFcGWM_ECGtoPDM 1;
BA_ "U_T6_MCA_MY2020_Tx" SG_ 2612170968 PARSEDPushFcGWM_ECGtoPDM 1;
BA_ "U_CD764_MY2022_Rx" SG_ 2612170968 PARSEDPushFcGWM_ECGtoPDM 1;
BA_ "U_U55X_MY2022_Rx" SG_ 2612170968 PARSEDPushFcGWM_ECGtoPDM 1;
BA_ "U_T6_MCA_MY2020_Rx" SG_ 2612170968 PARSEDPushFcGWM_ECGtoPDM 1;
BA_ "GenSigSendType" SG_ 2612170968 PARSEDPushFcGWM_ECGtoPDM 3;
BA_ "U_CD764_MY2022_Tx" SG_ 2611122392 PARSEDPhysGWM_ECGtoPDM 1;
BA_ "U_U55X_MY2022_Tx" SG_ 2611122392 PARSEDPhysGWM_ECGtoPDM 1;
BA_ "U_CD542_MY2021_Tx" SG_ 2611122392 PARSEDPhysGWM_ECGtoPDM 1;
BA_ "ECGUsedTxSignal" SG_ 2611122392 PARSEDPhysGWM_ECGtoPDM 1;
BA_ "U_T6_MCA_MY2020_Tx" SG_ 2611122392 PARSEDPhysGWM_ECGtoPDM 1;
BA_ "U_CD764_MY2022_Rx" SG_ 2611122392 PARSEDPhysGWM_ECGtoPDM 1;
BA_ "U_U55X_MY2022_Rx" SG_ 2611122392 PARSEDPhysGWM_ECGtoPDM 1;
BA_ "U_T6_MCA_MY2020_Rx" SG_ 2611122392 PARSEDPhysGWM_ECGtoPDM 1;
BA_ "GenSigSendType" SG_ 2611122392 PARSEDPhysGWM_ECGtoPDM 3;
BA_ "U_CD764_MY2022_Tx" SG_ 2611118296 PARSEDPhysGWM_ECGtoDDM 1;
BA_ "U_U55X_MY2022_Tx" SG_ 2611118296 PARSEDPhysGWM_ECGtoDDM 1;
BA_ "U_CD542_MY2021_Tx" SG_ 2611118296 PARSEDPhysGWM_ECGtoDDM 1;
BA_ "ECGUsedTxSignal" SG_ 2611118296 PARSEDPhysGWM_ECGtoDDM 1;
BA_ "U_T6_MCA_MY2020_Tx" SG_ 2611118296 PARSEDPhysGWM_ECGtoDDM 1;
BA_ "U_CD764_MY2022_Rx" SG_ 2611118296 PARSEDPhysGWM_ECGtoDDM 1;
BA_ "U_U55X_MY2022_Rx" SG_ 2611118296 PARSEDPhysGWM_ECGtoDDM 1;
BA_ "U_T6_MCA_MY2020_Rx" SG_ 2611118296 PARSEDPhysGWM_ECGtoDDM 1;
BA_ "GenSigSendType" SG_ 2611118296 PARSEDPhysGWM_ECGtoDDM 3;
BA_ "U_CD764_MY2022_Tx" SG_ 2611175584 PARSEDPhysDDMtoGWM_ECG 1;
BA_ "U_U55X_MY2022_Tx" SG_ 2611175584 PARSEDPhysDDMtoGWM_ECG 1;
BA_ "U_T6_MCA_MY2020_Tx" SG_ 2611175584 PARSEDPhysDDMtoGWM_ECG 1;
BA_ "U_CD764_MY2022_Rx" SG_ 2611175584 PARSEDPhysDDMtoGWM_ECG 1;
BA_ "U_U55X_MY2022_Rx" SG_ 2611175584 PARSEDPhysDDMtoGWM_ECG 1;
BA_ "U_CD542_MY2021_Rx" SG_ 2611175584 PARSEDPhysDDMtoGWM_ECG 1;
BA_ "ECGUsedRxSignal" SG_ 2611175584 PARSEDPhysDDMtoGWM_ECG 1;
BA_ "U_T6_MCA_MY2020_Rx" SG_ 2611175584 PARSEDPhysDDMtoGWM_ECG 1;
BA_ "GenSigSendType" SG_ 2611175584 PARSEDPhysDDMtoGWM_ECG 3;
BA_ "U_CD764_MY2022_Tx" SG_ 2611175588 PARSEDPhysPDMtoGWM_ECG 1;
BA_ "U_U55X_MY2022_Tx" SG_ 2611175588 PARSEDPhysPDMtoGWM_ECG 1;
BA_ "U_T6_MCA_MY2020_Tx" SG_ 2611175588 PARSEDPhysPDMtoGWM_ECG 1;
BA_ "U_CD764_MY2022_Rx" SG_ 2611175588 PARSEDPhysPDMtoGWM_ECG 1;
BA_ "U_U55X_MY2022_Rx" SG_ 2611175588 PARSEDPhysPDMtoGWM_ECG 1;
BA_ "U_CD542_MY2021_Rx" SG_ 2611175588 PARSEDPhysPDMtoGWM_ECG 1;
BA_ "ECGUsedRxSignal" SG_ 2611175588 PARSEDPhysPDMtoGWM_ECG 1;
BA_ "U_T6_MCA_MY2020_Rx" SG_ 2611175588 PARSEDPhysPDMtoGWM_ECG 1;
BA_ "GenSigSendType" SG_ 2611175588 PARSEDPhysPDMtoGWM_ECG 3;
BA_ "U_CD764_MY2022_Tx" SG_ 2610127012 OTAPhysPDMtoGWM_ECG 1;
BA_ "U_U55X_MY2022_Tx" SG_ 2610127012 OTAPhysPDMtoGWM_ECG 1;
BA_ "U_T6_MCA_MY2020_Tx" SG_ 2610127012 OTAPhysPDMtoGWM_ECG 1;
BA_ "U_CD764_MY2022_Rx" SG_ 2610127012 OTAPhysPDMtoGWM_ECG 1;
BA_ "U_U55X_MY2022_Rx" SG_ 2610127012 OTAPhysPDMtoGWM_ECG 1;
BA_ "U_CD542_MY2021_Rx" SG_ 2610127012 OTAPhysPDMtoGWM_ECG 1;
BA_ "ECGUsedRxSignal" SG_ 2610127012 OTAPhysPDMtoGWM_ECG 1;
BA_ "U_T6_MCA_MY2020_Rx" SG_ 2610127012 OTAPhysPDMtoGWM_ECG 1;
BA_ "GenSigSendType" SG_ 2610127012 OTAPhysPDMtoGWM_ECG 3;
BA_ "U_CD764_MY2022_Tx" SG_ 2610073816 OTAPhysGWM_ECGtoPDM 1;
BA_ "U_U55X_MY2022_Tx" SG_ 2610073816 OTAPhysGWM_ECGtoPDM 1;
BA_ "U_CD542_MY2021_Tx" SG_ 2610073816 OTAPhysGWM_ECGtoPDM 1;
BA_ "ECGUsedTxSignal" SG_ 2610073816 OTAPhysGWM_ECGtoPDM 1;
BA_ "U_T6_MCA_MY2020_Tx" SG_ 2610073816 OTAPhysGWM_ECGtoPDM 1;
BA_ "U_CD764_MY2022_Rx" SG_ 2610073816 OTAPhysGWM_ECGtoPDM 1;
BA_ "U_U55X_MY2022_Rx" SG_ 2610073816 OTAPhysGWM_ECGtoPDM 1;
BA_ "U_T6_MCA_MY2020_Rx" SG_ 2610073816 OTAPhysGWM_ECGtoPDM 1;
BA_ "GenSigSendType" SG_ 2610073816 OTAPhysGWM_ECGtoPDM 3;
BA_ "U_CD764_MY2022_Tx" SG_ 2610069720 OTAPhysGWM_ECGtoDDM 1;
BA_ "U_U55X_MY2022_Tx" SG_ 2610069720 OTAPhysGWM_ECGtoDDM 1;
BA_ "U_CD542_MY2021_Tx" SG_ 2610069720 OTAPhysGWM_ECGtoDDM 1;
BA_ "ECGUsedTxSignal" SG_ 2610069720 OTAPhysGWM_ECGtoDDM 1;
BA_ "U_T6_MCA_MY2020_Tx" SG_ 2610069720 OTAPhysGWM_ECGtoDDM 1;
BA_ "U_CD764_MY2022_Rx" SG_ 2610069720 OTAPhysGWM_ECGtoDDM 1;
BA_ "U_U55X_MY2022_Rx" SG_ 2610069720 OTAPhysGWM_ECGtoDDM 1;
BA_ "U_T6_MCA_MY2020_Rx" SG_ 2610069720 OTAPhysGWM_ECGtoDDM 1;
BA_ "GenSigSendType" SG_ 2610069720 OTAPhysGWM_ECGtoDDM 3;
BA_ "U_CD764_MY2022_Tx" SG_ 2610127008 OTAPhysDDMtoGWM_ECG 1;
BA_ "U_U55X_MY2022_Tx" SG_ 2610127008 OTAPhysDDMtoGWM_ECG 1;
BA_ "U_CD542_MY2021_Tx" SG_ 2610127008 OTAPhysDDMtoGWM_ECG 1;
BA_ "U_T6_MCA_MY2020_Tx" SG_ 2610127008 OTAPhysDDMtoGWM_ECG 1;
BA_ "U_CD764_MY2022_Rx" SG_ 2610127008 OTAPhysDDMtoGWM_ECG 1;
BA_ "U_U55X_MY2022_Rx" SG_ 2610127008 OTAPhysDDMtoGWM_ECG 1;
BA_ "U_CD542_MY2021_Rx" SG_ 2610127008 OTAPhysDDMtoGWM_ECG 1;
BA_ "ECGUsedRxSignal" SG_ 2610127008 OTAPhysDDMtoGWM_ECG 1;
BA_ "U_T6_MCA_MY2020_Rx" SG_ 2610127008 OTAPhysDDMtoGWM_ECG 1;
BA_ "GenSigSendType" SG_ 2610127008 OTAPhysDDMtoGWM_ECG 3;
BA_ "U_CD764_MY2022_Tx" SG_ 2612224160 PARSEDPushDDMtoGWM_ECG 1;
BA_ "U_U55X_MY2022_Tx" SG_ 2612224160 PARSEDPushDDMtoGWM_ECG 1;
BA_ "U_T6_MCA_MY2020_Tx" SG_ 2612224160 PARSEDPushDDMtoGWM_ECG 1;
BA_ "U_CD764_MY2022_Rx" SG_ 2612224160 PARSEDPushDDMtoGWM_ECG 1;
BA_ "U_U55X_MY2022_Rx" SG_ 2612224160 PARSEDPushDDMtoGWM_ECG 1;
BA_ "U_CD542_MY2021_Rx" SG_ 2612224160 PARSEDPushDDMtoGWM_ECG 1;
BA_ "ECGUsedRxSignal" SG_ 2612224160 PARSEDPushDDMtoGWM_ECG 1;
BA_ "U_T6_MCA_MY2020_Rx" SG_ 2612224160 PARSEDPushDDMtoGWM_ECG 1;
BA_ "GenSigSendType" SG_ 2612224160 PARSEDPushDDMtoGWM_ECG 3;
BA_ "U_CD764_MY2022_Tx" SG_ 2612166872 PARSEDPushFcGWM_ECGtoDDM 1;
BA_ "U_U55X_MY2022_Tx" SG_ 2612166872 PARSEDPushFcGWM_ECGtoDDM 1;
BA_ "U_CD542_MY2021_Tx" SG_ 2612166872 PARSEDPushFcGWM_ECGtoDDM 1;
BA_ "ECGUsedTxSignal" SG_ 2612166872 PARSEDPushFcGWM_ECGtoDDM 1;
BA_ "U_T6_MCA_MY2020_Tx" SG_ 2612166872 PARSEDPushFcGWM_ECGtoDDM 1;
BA_ "U_CD764_MY2022_Rx" SG_ 2612166872 PARSEDPushFcGWM_ECGtoDDM 1;
BA_ "U_U55X_MY2022_Rx" SG_ 2612166872 PARSEDPushFcGWM_ECGtoDDM 1;
BA_ "U_T6_MCA_MY2020_Rx" SG_ 2612166872 PARSEDPushFcGWM_ECGtoDDM 1;
BA_ "GenSigSendType" SG_ 2612166872 PARSEDPushFcGWM_ECGtoDDM 3;
BA_ "GenSigStartValue" SG_ 1508 GFM_GWOnBoardTester 255;
BA_ "ContentDependant" SG_ 1508 GFM_GWOnBoardTester 1;
BA_ "GenSigStartValueInteger" SG_ 1508 GFM_GWOnBoardTester 255;
BA_ "GenSigStartValue" SG_ 1508 GFM_GWNMProxy 255;
BA_ "ContentDependant" SG_ 1508 GFM_GWNMProxy 1;
BA_ "GenSigStartValueInteger" SG_ 1508 GFM_GWNMProxy 255;
BA_ "GenSigStartValue" SG_ 1508 GFM_AutoSarNMReserved4 255;
BA_ "ContentDependant" SG_ 1508 GFM_AutoSarNMReserved4 1;
BA_ "GenSigStartValueInteger" SG_ 1508 GFM_AutoSarNMReserved4 255;
BA_ "GenSigStartValue" SG_ 1508 GFM_AutoSarNMReserved3 255;
BA_ "ContentDependant" SG_ 1508 GFM_AutoSarNMReserved3 1;
BA_ "GenSigStartValueInteger" SG_ 1508 GFM_AutoSarNMReserved3 255;
BA_ "GenSigStartValue" SG_ 1508 GFM_AutoSarNMReserved2 255;
BA_ "ContentDependant" SG_ 1508 GFM_AutoSarNMReserved2 1;
BA_ "GenSigStartValueInteger" SG_ 1508 GFM_AutoSarNMReserved2 255;
BA_ "GenSigStartValue" SG_ 1508 GFM_AutoSarNMReserved1 255;
BA_ "ContentDependant" SG_ 1508 GFM_AutoSarNMReserved1 1;
BA_ "GenSigStartValueInteger" SG_ 1508 GFM_AutoSarNMReserved1 255;
BA_ "GenSigStartValue" SG_ 1508 GFM_AutoSarNMNodeId 228;
BA_ "ContentDependant" SG_ 1508 GFM_AutoSarNMNodeId 1;
BA_ "GenSigStartValueInteger" SG_ 1508 GFM_AutoSarNMNodeId 228;
BA_ "ContentDependant" SG_ 1508 GFM_AutoSarNMControl 1;
BA_ "GenSigSendType" SG_ 930 BalrWndwRight_D_Confg 3;
BA_ "GenSigStartValue" SG_ 930 BalrWndwRight_D_Confg 2;
BA_ "GenSigStartValueInteger" SG_ 930 BalrWndwRight_D_Confg 2;
BA_ "GenSigSendType" SG_ 930 BalrWndwRight_B_Stat 3;
BA_ "GenSigSendType" SG_ 930 BalrSnsRight_D_Falt 3;
BA_ "GenSigSendType" SG_ 930 WndwPsngrRear_D_RqBalrr 3;
BA_ "GenSigSendType" SG_ 930 WndwPsngr_D_RqBalrr 3;
BA_ "GenSigSendType" SG_ 930 WndwDrvRear_D_RqBalrr 3;
BA_ "GenSigSendType" SG_ 930 WndwDrv_D_RqBalrr 3;
BA_ "GenSigSendType" SG_ 930 BalrRight_D_Stat 3;
BA_ "GenSigStartValue" SG_ 930 BalrRight_D_Stat 2;
BA_ "GenSigStartValueInteger" SG_ 930 BalrRight_D_Stat 2;
BA_ "GenSigSendType" SG_ 930 BalrMdeSelRight_B_Stat 3;
BA_ "GenSigSendType" SG_ 930 BalrMdeRight_D_Stat 3;
BA_ "GenSigStartValue" SG_ 930 BalrMdeRight_D_Stat 1;
BA_ "GenSigStartValueInteger" SG_ 930 BalrMdeRight_D_Stat 1;
BA_ "GenSigSendType" SG_ 930 BalrLckRight_B_Stat 3;
BA_ "GenSigSendType" SG_ 930 BalrLckRight_B_Confg 3;
BA_ "GenSigSendType" SG_ 930 BalrInnrRight_D_Stat 3;
BA_ "GenSigSendType" SG_ 930 BalrDfaltRight_D_Stat 3;
BA_ "GenSigStartValue" SG_ 930 BalrDfaltRight_D_Stat 1;
BA_ "GenSigStartValueInteger" SG_ 930 BalrDfaltRight_D_Stat 1;
BA_ "GenSigSendType" SG_ 930 BalrChimeRight_D_Rq 3;
BA_ "GenSigSendType" SG_ 930 CamraRearOn_B_RqBalrr 3;
BA_ "GenSigSendType" SG_ 930 DrLckCnt_No_ActlBalrr 3;
BA_ "GenSigSendType" SG_ 930 DrLckActv_B_RqBalrr 3;
BA_ "GenSigSendType" SG_ 929 BalrChimeLeft_D_Rq 3;
BA_ "GenSigSendType" SG_ 929 BalrLeft_D_Stat 3;
BA_ "GenSigStartValue" SG_ 929 BalrLeft_D_Stat 2;
BA_ "GenSigStartValueInteger" SG_ 929 BalrLeft_D_Stat 2;
BA_ "GenSigSendType" SG_ 929 BalrWndwLeft_B_Stat 3;
BA_ "GenSigSendType" SG_ 929 WndwPsngrRear_D_RqBalrl 3;
BA_ "GenSigSendType" SG_ 929 WndwPsngr_D_RqBalrl 3;
BA_ "GenSigSendType" SG_ 929 WndwDrvRear_D_RqBalrl 3;
BA_ "GenSigSendType" SG_ 929 WndwDrv_D_RqBalrl 3;
BA_ "GenSigSendType" SG_ 929 BalrSnsLeft_D_Falt 3;
BA_ "GenSigSendType" SG_ 929 BalrMdeSelLeft_B_Stat 3;
BA_ "GenSigSendType" SG_ 929 BalrMdeLeft_D_Stat 3;
BA_ "GenSigStartValue" SG_ 929 BalrMdeLeft_D_Stat 1;
BA_ "GenSigStartValueInteger" SG_ 929 BalrMdeLeft_D_Stat 1;
BA_ "GenSigSendType" SG_ 929 BalrLckLeft_B_Stat 3;
BA_ "GenSigSendType" SG_ 929 CamraRearOn_B_RqBalrl 3;
BA_ "GenSigSendType" SG_ 929 DrLckCnt_No_ActlBalrl 3;
BA_ "GenSigSendType" SG_ 929 DrLckActv_B_RqBalrl 3;
BA_ "U_U55X_MY2022_Tx" SG_ 1496 SCMB_GWOnBoardTester 1;
BA_ "GenSigStartValue" SG_ 1496 SCMB_GWOnBoardTester 255;
BA_ "ContentDependant" SG_ 1496 SCMB_GWOnBoardTester 1;
BA_ "GenSigStartValueInteger" SG_ 1496 SCMB_GWOnBoardTester 255;
BA_ "U_U55X_MY2022_Tx" SG_ 1496 SCMB_GWNMProxy 1;
BA_ "GenSigStartValue" SG_ 1496 SCMB_GWNMProxy 255;
BA_ "ContentDependant" SG_ 1496 SCMB_GWNMProxy 1;
BA_ "GenSigStartValueInteger" SG_ 1496 SCMB_GWNMProxy 255;
BA_ "U_U55X_MY2022_Tx" SG_ 1496 SCMB_AutoSarNMReserved4 1;
BA_ "GenSigStartValue" SG_ 1496 SCMB_AutoSarNMReserved4 255;
BA_ "ContentDependant" SG_ 1496 SCMB_AutoSarNMReserved4 1;
BA_ "GenSigStartValueInteger" SG_ 1496 SCMB_AutoSarNMReserved4 255;
BA_ "U_U55X_MY2022_Tx" SG_ 1496 SCMB_AutoSarNMReserved3 1;
BA_ "GenSigStartValue" SG_ 1496 SCMB_AutoSarNMReserved3 255;
BA_ "ContentDependant" SG_ 1496 SCMB_AutoSarNMReserved3 1;
BA_ "GenSigStartValueInteger" SG_ 1496 SCMB_AutoSarNMReserved3 255;
BA_ "U_U55X_MY2022_Tx" SG_ 1496 SCMB_AutoSarNMReserved2 1;
BA_ "GenSigStartValue" SG_ 1496 SCMB_AutoSarNMReserved2 255;
BA_ "ContentDependant" SG_ 1496 SCMB_AutoSarNMReserved2 1;
BA_ "GenSigStartValueInteger" SG_ 1496 SCMB_AutoSarNMReserved2 255;
BA_ "U_U55X_MY2022_Tx" SG_ 1496 SCMB_AutoSarNMReserved1 1;
BA_ "GenSigStartValue" SG_ 1496 SCMB_AutoSarNMReserved1 255;
BA_ "ContentDependant" SG_ 1496 SCMB_AutoSarNMReserved1 1;
BA_ "GenSigStartValueInteger" SG_ 1496 SCMB_AutoSarNMReserved1 255;
BA_ "U_U55X_MY2022_Tx" SG_ 1496 SCMB_AutoSarNMNodeId 1;
BA_ "GenSigStartValue" SG_ 1496 SCMB_AutoSarNMNodeId 216;
BA_ "ContentDependant" SG_ 1496 SCMB_AutoSarNMNodeId 1;
BA_ "GenSigStartValueInteger" SG_ 1496 SCMB_AutoSarNMNodeId 216;
BA_ "U_U55X_MY2022_Tx" SG_ 1496 SCMB_AutoSarNMControl 1;
BA_ "ContentDependant" SG_ 1496 SCMB_AutoSarNMControl 1;
BA_ "U_U55X_MY2022_Rx" SG_ 718 BEZEL_RDISP_WORD_Rx 1;
BA_ "U_T6_MCA_MY2020_Rx" SG_ 718 BEZEL_RDISP_WORD_Rx 1;
BA_ "U_CD542_MY2021_Rx" SG_ 718 BEZEL_RDISP_WORD_Rx 1;
BA_ "U_T6_MCA_MY2020_Tx" SG_ 1491 MRCMA_GWOnBoardTester 1;
BA_ "GenSigStartValue" SG_ 1491 MRCMA_GWOnBoardTester 255;
BA_ "ContentDependant" SG_ 1491 MRCMA_GWOnBoardTester 1;
BA_ "GenSigStartValueInteger" SG_ 1491 MRCMA_GWOnBoardTester 255;
BA_ "U_T6_MCA_MY2020_Tx" SG_ 1491 MRCMA_GWNMProxy 1;
BA_ "GenSigStartValue" SG_ 1491 MRCMA_GWNMProxy 255;
BA_ "ContentDependant" SG_ 1491 MRCMA_GWNMProxy 1;
BA_ "GenSigStartValueInteger" SG_ 1491 MRCMA_GWNMProxy 255;
BA_ "U_T6_MCA_MY2020_Tx" SG_ 1491 MRCMA_AutoSarNMReserved4 1;
BA_ "GenSigStartValue" SG_ 1491 MRCMA_AutoSarNMReserved4 255;
BA_ "ContentDependant" SG_ 1491 MRCMA_AutoSarNMReserved4 1;
BA_ "GenSigStartValueInteger" SG_ 1491 MRCMA_AutoSarNMReserved4 255;
BA_ "U_T6_MCA_MY2020_Tx" SG_ 1491 MRCMA_AutoSarNMReserved3 1;
BA_ "GenSigStartValue" SG_ 1491 MRCMA_AutoSarNMReserved3 255;
BA_ "ContentDependant" SG_ 1491 MRCMA_AutoSarNMReserved3 1;
BA_ "GenSigStartValueInteger" SG_ 1491 MRCMA_AutoSarNMReserved3 255;
BA_ "U_T6_MCA_MY2020_Tx" SG_ 1491 MRCMA_AutoSarNMReserved2 1;
BA_ "GenSigStartValue" SG_ 1491 MRCMA_AutoSarNMReserved2 255;
BA_ "ContentDependant" SG_ 1491 MRCMA_AutoSarNMReserved2 1;
BA_ "GenSigStartValueInteger" SG_ 1491 MRCMA_AutoSarNMReserved2 255;
BA_ "U_T6_MCA_MY2020_Tx" SG_ 1491 MRCMA_AutoSarNMReserved1 1;
BA_ "GenSigStartValue" SG_ 1491 MRCMA_AutoSarNMReserved1 255;
BA_ "ContentDependant" SG_ 1491 MRCMA_AutoSarNMReserved1 1;
BA_ "GenSigStartValueInteger" SG_ 1491 MRCMA_AutoSarNMReserved1 255;
BA_ "U_T6_MCA_MY2020_Tx" SG_ 1491 MRCMA_AutoSarNMNodeId 1;
BA_ "GenSigStartValue" SG_ 1491 MRCMA_AutoSarNMNodeId 181;
BA_ "ContentDependant" SG_ 1491 MRCMA_AutoSarNMNodeId 1;
BA_ "GenSigStartValueInteger" SG_ 1491 MRCMA_AutoSarNMNodeId 181;
BA_ "U_T6_MCA_MY2020_Tx" SG_ 1491 MRCMA_AutoSarNMControl 1;
BA_ "ContentDependant" SG_ 1491 MRCMA_AutoSarNMControl 1;
BA_ "U_U55X_MY2022_Tx" SG_ 847 FldngSeatPwOffOk_B_Stat 1;
BA_ "U_T6_MCA_MY2020_Tx" SG_ 847 FldngSeatPwOffOk_B_Stat 1;
BA_ "GenSigSendType" SG_ 847 FldngSeatPwOffOk_B_Stat 3;
BA_ "WakeupSignal" SG_ 847 FldngSeatPwOffOk_B_Stat 1;
BA_ "ECGUsedTxSignal" SG_ 2609972440 OTAPhysGWM_ECGtoSCMJ 1;
BA_ "GenSigSendType" SG_ 2609972440 OTAPhysGWM_ECGtoSCMJ 3;
BA_ "U_CD764_MY2022_Tx" SG_ 2612158680 PARSEDPushFcGWM_ECGtoHVAC 1;
BA_ "U_U55X_MY2022_Tx" SG_ 2612158680 PARSEDPushFcGWM_ECGtoHVAC 1;
BA_ "U_CD542_MY2021_Tx" SG_ 2612158680 PARSEDPushFcGWM_ECGtoHVAC 1;
BA_ "ECGUsedTxSignal" SG_ 2612158680 PARSEDPushFcGWM_ECGtoHVAC 1;
BA_ "U_T6_MCA_MY2020_Tx" SG_ 2612158680 PARSEDPushFcGWM_ECGtoHVAC 1;
BA_ "U_CD764_MY2022_Rx" SG_ 2612158680 PARSEDPushFcGWM_ECGtoHVAC 1;
BA_ "U_U55X_MY2022_Rx" SG_ 2612158680 PARSEDPushFcGWM_ECGtoHVAC 1;
BA_ "U_CD542_MY2021_Rx" SG_ 2612158680 PARSEDPushFcGWM_ECGtoHVAC 1;
BA_ "U_T6_MCA_MY2020_Rx" SG_ 2612158680 PARSEDPushFcGWM_ECGtoHVAC 1;
BA_ "GenSigSendType" SG_ 2612158680 PARSEDPushFcGWM_ECGtoHVAC 3;
BA_ "U_U55X_MY2022_Tx" SG_ 2612226264 PARSEDPushFcGWM_ECGtoRTM 1;
BA_ "U_CD542_MY2021_Tx" SG_ 2612226264 PARSEDPushFcGWM_ECGtoRTM 1;
BA_ "ECGUsedTxSignal" SG_ 2612226264 PARSEDPushFcGWM_ECGtoRTM 1;
BA_ "GenSigSendType" SG_ 2612226264 PARSEDPushFcGWM_ECGtoRTM 3;
BA_ "U_CD764_MY2022_Tx" SG_ 2612168920 PARSEDPushFcGWM_ECGtoDSM 1;
BA_ "U_U55X_MY2022_Tx" SG_ 2612168920 PARSEDPushFcGWM_ECGtoDSM 1;
BA_ "U_CD542_MY2021_Tx" SG_ 2612168920 PARSEDPushFcGWM_ECGtoDSM 1;
BA_ "ECGUsedTxSignal" SG_ 2612168920 PARSEDPushFcGWM_ECGtoDSM 1;
BA_ "U_T6_MCA_MY2020_Tx" SG_ 2612168920 PARSEDPushFcGWM_ECGtoDSM 1;
BA_ "U_U55X_MY2022_Rx" SG_ 2612168920 PARSEDPushFcGWM_ECGtoDSM 1;
BA_ "U_CD542_MY2021_Rx" SG_ 2612168920 PARSEDPushFcGWM_ECGtoDSM 1;
BA_ "U_T6_MCA_MY2020_Rx" SG_ 2612168920 PARSEDPushFcGWM_ECGtoDSM 1;
BA_ "GenSigSendType" SG_ 2612168920 PARSEDPushFcGWM_ECGtoDSM 3;
BA_ "WakeupSignal" SG_ 966 TrunkFrontOpen_No_Actl 1;
BA_ "WakeupSignal" SG_ 966 TrunkFrontRolCd_No_Actl 1;
BA_ "GenSigSendType" SG_ 965 PtWakeupActv4_B_Rq 3;
BA_ "WakeupSignal" SG_ 965 PtWakeupActv4_B_Rq 1;
BA_ "GenSigSendType" SG_ 965 TrunkFrontRolCd_No_Locl 3;
BA_ "WakeupSignal" SG_ 965 TrunkFrontRolCd_No_Locl 1;
BA_ "GenSigSendType" SG_ 965 TrnkFrontPrim_B_Falt 3;
BA_ "GenSigSendType" SG_ 965 TrnkFrontEmgcy_D_Stat 3;
BA_ "WakeupSignal" SG_ 965 TrnkFrontEmgcy_D_Stat 1;
BA_ "GenSigSendType" SG_ 965 TrunkFrontOpen_D_Stat 3;
BA_ "GenSigStartValue" SG_ 965 TrunkFrontOpen_D_Stat 2;
BA_ "WakeupSignal" SG_ 965 TrunkFrontOpen_D_Stat 1;
BA_ "U_U55X_MY2022_Tx" SG_ 1467 RTM_AutoSarNMControl 1;
BA_ "U_T6_MCA_MY2020_Tx" SG_ 1467 RTM_AutoSarNMControl 1;
BA_ "ContentDependant" SG_ 1467 RTM_AutoSarNMControl 1;
BA_ "U_U55X_MY2022_Tx" SG_ 1467 RTM_GWOnBoardTester 1;
BA_ "U_T6_MCA_MY2020_Tx" SG_ 1467 RTM_GWOnBoardTester 1;
BA_ "GenSigStartValue" SG_ 1467 RTM_GWOnBoardTester 255;
BA_ "ContentDependant" SG_ 1467 RTM_GWOnBoardTester 1;
BA_ "GenSigStartValueInteger" SG_ 1467 RTM_GWOnBoardTester 255;
BA_ "U_U55X_MY2022_Tx" SG_ 1467 RTM_GWNMProxy 1;
BA_ "U_T6_MCA_MY2020_Tx" SG_ 1467 RTM_GWNMProxy 1;
BA_ "GenSigStartValue" SG_ 1467 RTM_GWNMProxy 255;
BA_ "ContentDependant" SG_ 1467 RTM_GWNMProxy 1;
BA_ "GenSigStartValueInteger" SG_ 1467 RTM_GWNMProxy 255;
BA_ "U_U55X_MY2022_Tx" SG_ 1467 RTM_AutoSarNMReserved4 1;
BA_ "U_T6_MCA_MY2020_Tx" SG_ 1467 RTM_AutoSarNMReserved4 1;
BA_ "GenSigStartValue" SG_ 1467 RTM_AutoSarNMReserved4 255;
BA_ "ContentDependant" SG_ 1467 RTM_AutoSarNMReserved4 1;
BA_ "GenSigStartValueInteger" SG_ 1467 RTM_AutoSarNMReserved4 255;
BA_ "U_U55X_MY2022_Tx" SG_ 1467 RTM_AutoSarNMReserved3 1;
BA_ "U_T6_MCA_MY2020_Tx" SG_ 1467 RTM_AutoSarNMReserved3 1;
BA_ "GenSigStartValue" SG_ 1467 RTM_AutoSarNMReserved3 255;
BA_ "ContentDependant" SG_ 1467 RTM_AutoSarNMReserved3 1;
BA_ "GenSigStartValueInteger" SG_ 1467 RTM_AutoSarNMReserved3 255;
BA_ "U_U55X_MY2022_Tx" SG_ 1467 RTM_AutoSarNMReserved2 1;
BA_ "U_T6_MCA_MY2020_Tx" SG_ 1467 RTM_AutoSarNMReserved2 1;
BA_ "GenSigStartValue" SG_ 1467 RTM_AutoSarNMReserved2 255;
BA_ "ContentDependant" SG_ 1467 RTM_AutoSarNMReserved2 1;
BA_ "GenSigStartValueInteger" SG_ 1467 RTM_AutoSarNMReserved2 255;
BA_ "U_U55X_MY2022_Tx" SG_ 1467 RTM_AutoSarNMReserved1 1;
BA_ "U_T6_MCA_MY2020_Tx" SG_ 1467 RTM_AutoSarNMReserved1 1;
BA_ "GenSigStartValue" SG_ 1467 RTM_AutoSarNMReserved1 255;
BA_ "ContentDependant" SG_ 1467 RTM_AutoSarNMReserved1 1;
BA_ "GenSigStartValueInteger" SG_ 1467 RTM_AutoSarNMReserved1 255;
BA_ "U_U55X_MY2022_Tx" SG_ 1467 RTM_AutoSarNMNodeId 1;
BA_ "U_T6_MCA_MY2020_Tx" SG_ 1467 RTM_AutoSarNMNodeId 1;
BA_ "GenSigStartValue" SG_ 1467 RTM_AutoSarNMNodeId 187;
BA_ "ContentDependant" SG_ 1467 RTM_AutoSarNMNodeId 1;
BA_ "GenSigStartValueInteger" SG_ 1467 RTM_AutoSarNMNodeId 187;
BA_ "GenSigSendType" SG_ 1869 TesterPhysicalResDASM 3;
VAL_ 612 SelDrvMdeSwtch_D_Stat6 3 "Faulty" 2 "SwitchState2" 1 "SwitchState1" 0 "NotPressed" ;
VAL_ 1017 SteWhlHeat_D_RqRmt 3 "NotUsed" 2 "On" 1 "Off" 0 "Null" ;
VAL_ 1017 WndwRearDfrst_D_RqRmt 3 "Auto" 2 "On" 1 "Off" 0 "Null" ;
VAL_ 1017 WndwFrontHeat_D_RqRmt 3 "Auto" 2 "On" 1 "Off" 0 "Null" ;
VAL_ 1017 RstrtHvacOvrrd_B_RqRmt 1 "Yes" 0 "No" ;
VAL_ 1017 SeatTeRr_D_RqRmt 15 "NotUsed_7" 14 "NotUsed_6" 13 "NotUsed_5" 12 "NotUsed_4" 11 "NotUsed_3" 10 "NotUsed_2" 9 "NotUsed_1" 8 "Auto" 7 "Cooled3" 6 "Cooled2" 5 "Cooled1" 4 "Heated3" 3 "Heated2" 2 "Heated1" 1 "Off" 0 "Null" ;
VAL_ 1017 SeatTeRl_D_RqRmt 15 "NotUsed_7" 14 "NotUsed_6" 13 "NotUsed_5" 12 "NotUsed_4" 11 "NotUsed_3" 10 "NotUsed_2" 9 "NotUsed_1" 8 "Auto" 7 "Cooled3" 6 "Cooled2" 5 "Cooled1" 4 "Heated3" 3 "Heated2" 2 "Heated1" 1 "Off" 0 "Null" ;
VAL_ 1017 SeatTeFr_D_RqRmt 15 "NotUsed_7" 14 "NotUsed_6" 13 "NotUsed_5" 12 "NotUsed_4" 11 "NotUsed_3" 10 "NotUsed_2" 9 "NotUsed_1" 8 "Auto" 7 "Cooled3" 6 "Cooled2" 5 "Cooled1" 4 "Heated3" 3 "Heated2" 2 "Heated1" 1 "Off" 0 "Null" ;
VAL_ 1017 SeatTeFl_D_RqRmt 15 "NotUsed_7" 14 "NotUsed_6" 13 "NotUsed_5" 12 "NotUsed_4" 11 "NotUsed_3" 10 "NotUsed_2" 9 "NotUsed_1" 8 "Auto" 7 "Cooled3" 6 "Cooled2" 5 "Cooled1" 4 "Heated3" 3 "Heated2" 2 "Heated1" 1 "Off" 0 "Null" ;
VAL_ 1017 CabnTeOn_B_RqRmt 1 "Request" 0 "NoRequest" ;
VAL_ 1017 HvacMde_D_RqRmt 7 "NotUsed_4" 6 "NotUsed_3" 5 "NotUsed_2" 4 "NotUsed_1" 3 "Auto" 2 "MaxDefrost" 1 "MaxAc" 0 "Null" ;
VAL_ 303 DrStatHood_D2_Actl 5 "NotUsed_2" 4 "NotUsed_1" 3 "Disabled" 2 "Ajar" 1 "Closed" 0 "NotDetermined" 7 "Faulty" 6 "NotUsed_3" ;
VAL_ 1015 E_Frt_Btn_Status_2nd 63 "NotUsed_10" 62 "NotUsed_9" 61 "NotUsed_8" 60 "NotUsed_7" 59 "NotUsed_6" 58 "NotUsed_5" 57 "NotUsed_4" 56 "NotUsed_3" 55 "NotUsed_2" 54 "NotUsed_1" 53 "RHS_Cld_Seat3_Pressed" 52 "RHS_Cld_Seat2_Pressed" 51 "RHS_Cld_Seat1_Pressed" 50 "LHS_Cld_Seat3_Pressed" 49 "LHS_Cld_Seat2_Pressed" 48 "LHS_Cld_Seat1_Pressed" 47 "RHS_Auto_Seat_Pressed" 46 "RHS_Htd_Seat3_Pressed" 45 "RHS_Htd_Seat2_Pressed" 44 "RHS_Htd_Seat1_Pressed" 43 "RHS_Seat_Off_Pressed" 42 "LHS_Auto_Seat_Pressed" 41 "LHS_Htd_Seat3_Pressed" 40 "LHS_Htd_Seat2_Pressed" 39 "LHS_Htd_Seat1_Pressed" 38 "LHS_Seat_Off_Pressed" 37 "DrvrFcsdMde_Pressed" 36 "MdeMnu_Pressed" 35 "AAR_Pressed" 34 "Heat_Pressed" 33 "RearMnu_Pressed" 32 "FrontMnu_Pressed" 31 "Defrost_Pressed" 30 "Htg_Strg_Whl_Pressed" 29 "RHS_Cld_Seat_Pressed" 28 "LHS_Cld_Seat_Pressed" 27 "RHS_Htd_Seat_Pressed" 26 "LHS_Htd_Seat_Pressed" 25 "Max_Defrost_Pressed" 24 "My_Temp_Pressed" 23 "Front_Power_Pressed" 22 "Rear_Defrost_Pressed" 21 "Pnl_Flr_Ws_Pressed" 20 "Pnl_Ws_Pressed" 19 "Windscreen_Pressed" 18 "Htd_Frt_Wsh_Pressed" 17 "Auto_Recirc_Pressed" 16 "Outside_Pressed" 15 "Recirc_Pressed" 14 "Max_AC_Pressed" 13 "Auto_Pressed" 12 "Blwr_Dec_Pressed" 11 "Blwr_Inc_Pressed" 10 "RHS_Temp_Dec_Pressed" 9 "RHS_Temp_Inc_Pressed" 8 "LHS_Temp_Dec_Pressed" 7 "LHS_Temp_Inc_Pressed" 6 "Dual_Pressed" 5 "AC_Pressed" 4 "Floor_Ws_Pressed" 3 "Floor_Pressed" 2 "Panel_Floor_Pressed" 1 "Panel_Pressed" 0 "None_Pressed" ;
VAL_ 1015 E_Frt_Btn_Status_1st 63 "NotUsed_10" 62 "NotUsed_9" 61 "NotUsed_8" 60 "NotUsed_7" 59 "NotUsed_6" 58 "NotUsed_5" 57 "NotUsed_4" 56 "NotUsed_3" 55 "NotUsed_2" 54 "NotUsed_1" 53 "RHS_Cld_Seat3_Pressed" 52 "RHS_Cld_Seat2_Pressed" 51 "RHS_Cld_Seat1_Pressed" 50 "LHS_Cld_Seat3_Pressed" 49 "LHS_Cld_Seat2_Pressed" 48 "LHS_Cld_Seat1_Pressed" 47 "RHS_Auto_Seat_Pressed" 46 "RHS_Htd_Seat3_Pressed" 45 "RHS_Htd_Seat2_Pressed" 44 "RHS_Htd_Seat1_Pressed" 43 "RHS_Seat_Off_Pressed" 42 "LHS_Auto_Seat_Pressed" 41 "LHS_Htd_Seat3_Pressed" 40 "LHS_Htd_Seat2_Pressed" 39 "LHS_Htd_Seat1_Pressed" 38 "LHS_Seat_Off_Pressed" 37 "DrvrFcsdMde_Pressed" 36 "MdeMnu_Pressed" 35 "AAR_Pressed" 34 "Heat_Pressed" 33 "RearMnu_Pressed" 32 "FrontMnu_Pressed" 31 "Defrost_Pressed" 30 "Htg_Strg_Whl_Pressed" 29 "RHS_Cld_Seat_Pressed" 28 "LHS_Cld_Seat_Pressed" 27 "RHS_Htd_Seat_Pressed" 26 "LHS_Htd_Seat_Pressed" 25 "Max_Defrost_Pressed" 24 "My_Temp_Pressed" 23 "Front_Power_Pressed" 22 "Rear_Defrost_Pressed" 21 "Pnl_Flr_Ws_Pressed" 20 "Pnl_Ws_Pressed" 19 "Windscreen_Pressed" 18 "Htd_Frt_Wsh_Pressed" 17 "Auto_Recirc_Pressed" 16 "Outside_Pressed" 15 "Recirc_Pressed" 14 "Max_AC_Pressed" 13 "Auto_Pressed" 12 "Blwr_Dec_Pressed" 11 "Blwr_Inc_Pressed" 10 "RHS_Temp_Dec_Pressed" 9 "RHS_Temp_Inc_Pressed" 8 "LHS_Temp_Dec_Pressed" 7 "LHS_Temp_Inc_Pressed" 6 "Dual_Pressed" 5 "AC_Pressed" 4 "Floor_Ws_Pressed" 3 "Floor_Pressed" 2 "Panel_Floor_Pressed" 1 "Panel_Pressed" 0 "None_Pressed" ;
VAL_ 1015 SelDrvMdeSwtch_D_Stat7 3 "Faulty" 2 "SwitchState2" 1 "SwitchState1" 0 "NotPressed" ;
VAL_ 1067 ElCmprEnbl_B_Rq_UB 1 "Fresh_data" 0 "Unchanged_data" ;
VAL_ 1067 ElCmpr_N_Rq_UB 1 "Fresh_data" 0 "Unchanged_data" ;
VAL_ 1067 ElCmprEnbl_B_Rq 1 "Enable" 0 "Disable" ;
VAL_ 1067 VehStrtInhbt_D_Stat_UB 1 "Fresh_data" 0 "Unchanged_data" ;
VAL_ 1067 VehOnSrc2_D_Stat_UB 1 "Fresh_data" 0 "Unchanged_data" ;
VAL_ 1067 VehStrtInhbt_D_Stat 1 "Inhibit" 0 "NoInhibit" ;
VAL_ 1067 VehOnSrc2_D_Stat 15 "NotUsed_11" 14 "NotUsed_10" 13 "NotUsed_9" 12 "NotUsed_8" 11 "NotUsed_7" 10 "NotUsed_6" 9 "EsclRssd" 8 "AutonomousVehicle" 7 "SecureIdle" 6 "FleetVehicleInhibit" 5 "StolenVehicleInhibit" 4 "OverTheAir" 3 "RemoteParkAssist" 2 "RemoteStart" 1 "Manual" 0 "Off" ;
VAL_ 1067 ElCmpr_N_Actl_UB 1 "Fresh_data" 0 "Unchanged_data" ;
VAL_ 1067 ElCmpr_D_Stat_UB 1 "Fresh_data" 0 "Unchanged_data" ;
VAL_ 1067 ElCmpr_N_Actl 255 "Invalid" ;
VAL_ 1067 ElCmpr_D_Stat 7 "Signal_Invalid" 6 "Comp_Off_ActlSpd_Abnormal" 5 "Comp_Off_TrgtSpd_OutRange" 4 "Comp_Shutdown" 3 "Comp_Stopped_Self_Protect" 2 "Comp_Degraded" 1 "Comp_On" 0 "Comp_Off" ;
VAL_ 1080 Btt_L_Actl2_UB 1 "Fresh_data" 0 "Unchanged_data" ;
VAL_ 1080 Btt_L_Actl2 127 "Faulty" 126 "NoDataExists" ;
VAL_ 1080 TrlrRvrseMsgTxt_D2_Rq_UB 1 "Fresh_data" 0 "Unchanged_data" ;
VAL_ 1080 TrlrRvrseMsgTxt_D2_Rq 31 "Message31" 30 "Message30" 29 "Message29" 28 "Message28" 27 "Message27" 26 "Message26" 25 "Message25" 24 "Message24" 23 "Message23" 22 "Message22" 21 "Message21" 20 "Message20" 19 "Message19" 18 "Message18" 17 "Message17" 16 "Message16" 15 "Message15" 14 "Message14" 13 "Message13" 12 "Message12" 11 "Message11" 10 "Message10" 9 "Message9" 8 "Message8" 7 "Message7" 6 "Message6" 5 "Message5" 4 "Message4" 3 "Message3" 2 "Message2" 1 "Message1" 0 "NoMessage" 63 "Message63" 47 "Message47" ;
VAL_ 1080 TrlrRvrseEnbl_D2_Stat_UB 1 "Fresh_data" 0 "Unchanged_data" ;
VAL_ 1080 TrlrRvrseEnbl_D2_Stat 7 "NotUsed" 6 "TbaActiveExpertActive" 5 "TbaActiveExpertAvail" 4 "TbaOffTrgActive" 3 "TbaOffTrgSetup" 2 "TbaSetup" 1 "TbaActive" 0 "Inactive" ;
VAL_ 1080 PwRnngBoardT_D_Rq_UB 1 "Fresh_data" 0 "Unchanged_data" ;
VAL_ 1080 PwRnngBoardSwtch_D_Rq_UB 1 "Fresh_data" 0 "Unchanged_data" ;
VAL_ 1080 PwRnngBoardMde_D_Rq_UB 1 "Fresh_data" 0 "Unchanged_data" ;
VAL_ 1080 PwRnngBoardT_D_Rq 3 "NotUsed" 2 "Timer2" 1 "Timer1" 0 "Inactive" ;
VAL_ 1080 PwRnngBoardSwtch_D_Rq 3 "NotUsed" 2 "DeployUnlocked" 1 "AlwaysActive" 0 "Inactive" ;
VAL_ 1080 PwRnngBoardMde_D_Rq 0 "Inactive" 1 "Off" 2 "Out" 3 "Auto" ;
VAL_ 1080 StopStrtDrvMde_B_RqBtn3_UB 1 "Fresh_data" 0 "Unchanged_data" ;
VAL_ 1080 StopStrtDrvMde_B_RqBtn3 1 "Pressed" 0 "Not_Pressed" ;
VAL_ 1080 Cntr_Plg_Mode_Cmd_UB 1 "Fresh_data" 0 "Unchanged_data" ;
VAL_ 1080 Cntr_Plg_Mode_Cmd 1 "Enable" 0 "Disable" ;
VAL_ 914 SodSlotRight_D_Stat 7 "Faulty" 6 "Slot6" 5 "Slot5" 4 "Slot4" 3 "Slot3" 2 "Slot2" 1 "Slot1" 0 "NoSlotFound" ;
VAL_ 913 SodSlotLeft_D_Stat 7 "Faulty" 6 "Slot6" 5 "Slot5" 4 "Slot4" 3 "Slot3" 2 "Slot2" 1 "Slot1" 0 "NoSlotFound" ;
VAL_ 1217 SldrrStat_B_Actl 1 "Ajar" 0 "Closed" ;
VAL_ 1217 SldrrMsgTxt_D2_Rq 7 "NotUsed_3" 6 "NotUsed_2" 5 "NotUsed_1" 4 "SlidingDrCalibNeeded2" 3 "SlidingDrOpenCltchReleased" 2 "SlidingDrCalibNeeded" 1 "SlidingDrClutchReleased" 0 "Null" ;
VAL_ 1217 SldrrChime_D_Rq 7 "NotUsed3" 6 "NotUsed2" 5 "NotUsed1" 4 "Warning" 3 "WarningRepeated" 2 "Programming" 1 "Operation" 0 "Off" ;
VAL_ 1217 PwStepRight_D_Rq 1 "Deploy" 0 "Null" 3 "NotUsed" 2 "Stow" ;
VAL_ 1217 SldrrUnlckSwtch_D_Stat 3 "InnerHandle" 2 "RearInteriorSwitch" 1 "IpSwitch" 0 "Null" ;
VAL_ 1217 Sldrr_D_Stat 3 "NotCalibrated" 2 "Closing" 1 "Opening" 0 "NotMoving" ;
VAL_ 1216 SldrlMsgTxt_D2_Rq 7 "NotUsed_3" 6 "NotUsed_2" 5 "NotUsed_1" 4 "SlidingDrCalibNeeded2" 3 "SlidingDrOpenCltchReleased" 2 "SlidingDrCalibNeeded" 1 "SlidingDrClutchReleased" 0 "Null" ;
VAL_ 1216 SldrlChime_D_Rq 7 "NotUsed3" 6 "NotUsed2" 5 "NotUsed1" 4 "Warning" 3 "WarningRepeated" 2 "Programming" 1 "Operation" 0 "Off" ;
VAL_ 1216 SldrlStat_B_Actl 1 "Ajar" 0 "Closed" ;
VAL_ 1216 PwStepLeft_D_Rq 1 "Deploy" 0 "Null" 3 "NotUsed" 2 "Stow" ;
VAL_ 1216 SldrlUnlckSwtch_D_Stat 3 "InnerHandle" 2 "RearInteriorSwitch" 1 "IpSwitch" 0 "Null" ;
VAL_ 1216 Sldrl_D_Stat 3 "NotCalibrated" 2 "Closing" 1 "Opening" 0 "NotMoving" ;
VAL_ 877 CabnAmb_Te_ActlAft 255 "Faulty" ;
VAL_ 877 RstrtClimtSet_B_Actv 1 "Active" 0 "Inactive" ;
VAL_ 877 Rr_Third_Power_Btn_Stt 3 "Unused" 2 "Disabled" 1 "Active" 0 "Enabled_Inactive" ;
VAL_ 877 Rr_Third_Floor_Btn_Stt 3 "Unused" 2 "Disabled" 1 "Active" 0 "Enabled_Inactive" ;
VAL_ 877 Rr_Third_Auto_Btn_Stt 3 "Unused" 2 "Disabled" 1 "Active" 0 "Enabled_Inactive" ;
VAL_ 877 Rr_Lock_Btn_Stt 3 "Unused" 2 "Disabled" 1 "Active" 0 "Enabled_Inactive" ;
VAL_ 877 Rr_RHS_Blower_Indicate 15 "Display_Blank" 14 "14_Indicators_On" 13 "13_Indicators_On" 12 "12_Indicators_On" 11 "11_Indicators_On" 10 "10_Indicators_On" 9 "9_Indicators_On" 8 "8_Indicators_On" 7 "7_Indicators_On" 6 "6_Indicators_On" 5 "5_Indicators_On" 4 "4_Indicators_On" 3 "3_Indicators_On" 2 "2_Indicators_On" 1 "1_Indicator_On" 0 "Indicators_Off" ;
VAL_ 877 Rr_Third_Panel_Btn_Stt 3 "Unused" 2 "Disabled" 1 "Active" 0 "Enabled_Inactive" ;
VAL_ 877 Rr_Synch_Btn_Stt 3 "Unused" 2 "Disabled" 1 "Active" 0 "Enabled_Inactive" ;
VAL_ 877 AAR_Btn_Stt 3 "Unused" 2 "Disabled" 1 "Active" 0 "Enabled_Inactive" ;
VAL_ 877 Heat_Btn_Stt 3 "Unused" 2 "Disabled" 1 "Active" 0 "Enabled_Inactive" ;
VAL_ 917 PrkAsstSlotId_D_Stat 7 "Faulty" 6 "Slot6" 5 "Slot5" 4 "Slot4" 3 "Slot3" 2 "Slot2" 1 "Slot1" 0 "NoSlotFound" ;
VAL_ 773 StmsScrnPsngrOn_B_Rq 1 "On" 0 "Off" ;
VAL_ 773 SeatScrnPsngrOn_B_Rq 1 "On" 0 "Off" ;
VAL_ 773 SeatPsngrMem_D_Cmd 15 "NotUsed_7" 14 "NotUsed_6" 13 "NotUsed_5" 12 "NotUsed_4" 11 "NotUsed_3" 10 "NotUsed_2" 9 "NotUsed_1" 8 "RECALL_4" 7 "RECALL_3" 6 "RECALL_2" 5 "RECALL_1" 4 "STORE_4" 3 "STORE_3" 2 "STORE_2" 1 "STORE_1" 0 "Null" ;
VAL_ 773 MemSwtchPsngrFdbck_B_Rq 1 "Yes" 0 "No" ;
VAL_ 878 ClimtSyncRear2_B_Stat 1 "Pressed" 0 "Not_Pressed" ;
VAL_ 878 ClimtStHeatRr2_B_Stat 1 "Pressed" 0 "Not_Pressed" ;
VAL_ 878 ClimtStHeatRl2_B_Stat 1 "Pressed" 0 "Not_Pressed" ;
VAL_ 878 ClimtStCoolRr2_B_Stat 1 "Pressed" 0 "Not_Pressed" ;
VAL_ 878 ClimtStCoolRl2_B_Stat 1 "Pressed" 0 "Not_Pressed" ;
VAL_ 878 ClimtSeatRr2_D_Rq 128 "H3_High_Heat_MAX" 64 "H2_Medium_Heat" 32 "H1_Low_Heat" 16 "C3_High_Cool_MAX" 8 "C2_Medium_Cool" 4 "C1_Low_Cool" 2 "Off" ;
VAL_ 878 ClimtSeatRl2_D_Rq 128 "H3_High_Heat_MAX" 64 "H2_Medium_Heat" 32 "H1_Low_Heat" 16 "C3_High_Cool_MAX" 8 "C2_Medium_Cool" 4 "C1_Low_Cool" 2 "Off" ;
VAL_ 878 ClimtRrTe3rd2_D_Stat 3 "NotUsed" 2 "Decrement" 1 "Increment" 0 "Inactive" ;
VAL_ 878 ClimtRrPw3rd2_B_Stat 1 "Pressed" 0 "Not_Pressed" ;
VAL_ 878 ClimtRrPnl3rd2_B_Stat 1 "Pressed" 0 "Not_Pressed" ;
VAL_ 878 ClimtRrPf3rd2_B_Stat 1 "Pressed" 0 "Not_Pressed" ;
VAL_ 878 ClimtRrFlr3rd2_B_Stat 1 "Pressed" 0 "Not_Pressed" ;
VAL_ 878 ClimtRrBlwr3rd2_D_Stat 3 "NotUsed" 2 "Decrement" 1 "Increment" 0 "Inactive" ;
VAL_ 878 ClimtRrAuto3rd2_B_Stat 1 "Pressed" 0 "Not_Pressed" ;
VAL_ 878 ClimtRearView2_D_Stat 3 "ThirdRow" 2 "SecondRow" 1 "Both" 0 "NotDisplayed" ;
VAL_ 878 ClimtRearTe2_D_Stat 3 "NotUsed" 2 "Decrement" 1 "Increment" 0 "Inactive" ;
VAL_ 878 ClimtRearTe2_An_Actl 511 "Faulty" ;
VAL_ 878 ClimtRearPw2_B_Stat 1 "Pressed" 0 "Not_Pressed" ;
VAL_ 878 ClimtRearPnlFlr2_B_Stat 1 "Pressed" 0 "Not_Pressed" ;
VAL_ 878 ClimtRearPnl2_B_Stat 1 "Pressed" 0 "Not_Pressed" ;
VAL_ 878 ClimtRearFlr2_B_Stat 1 "Pressed" 0 "Not_Pressed" ;
VAL_ 878 ClimtRearBlwr2_D_Stat 3 "NotUsed" 2 "Decrement" 1 "Increment" 0 "Inactive" ;
VAL_ 878 ClimtRearBlwr2_An_Actl 511 "Faulty" ;
VAL_ 878 ClimtRearAuto2_B_Stat 1 "Pressed" 0 "Not_Pressed" ;
VAL_ 1247 TrlrBrkCtl3_B_Falt 1 "True" 0 "False" ;
VAL_ 1247 StopLamp_B_RqTrlrAft 1 "True" 0 "False" ;
VAL_ 672 BCP_Audible_Beep_Rq 1 "Active" 0 "Inactive" ;
VAL_ 672 Coding_BtnID_D 1 "Pressed" 0 "Not_Pressed" ;
VAL_ 672 Coding_BtnID_C 1 "Pressed" 0 "Not_Pressed" ;
VAL_ 672 Coding_BtnID_B 1 "Pressed" 0 "Not_Pressed" ;
VAL_ 672 Coding_BtnID_A 1 "Pressed" 0 "Not_Pressed" ;
VAL_ 796 BattULoState_D_Qlty 3 "OK" 2 "Not_Within_Specifications" 1 "Eval_In_Progress" 0 "Fault" ;
VAL_ 796 BSFault 1 "Fault" 0 "No_Fault" ;
VAL_ 796 BattULo2_Te_Actl 127 "Fault" ;
VAL_ 677 SeatFnPsgr_D_Rq3 7 "CushionMassage" 6 "LumbarMassage" 5 "UpperBolster" 4 "LowerBolster" 3 "UpperLumbar" 2 "MiddleLumbar" 1 "LowerLumbar" 0 "Null" ;
VAL_ 677 SeatFnDrv_D_Rq3 7 "CushionMassage" 6 "LumbarMassage" 5 "UpperBolster" 4 "LowerBolster" 3 "UpperLumbar" 2 "MiddleLumbar" 1 "LowerLumbar" 0 "Null" ;
VAL_ 677 SeatMasgPsngrRr_D_Rq2 15 "NotUsed_10" 14 "NotUsed_9" 13 "NotUsed_8" 12 "NotUsed_7" 11 "NotUsed_6" 10 "Pattern10" 9 "Pattern9" 8 "Pattern8" 7 "Pattern7" 6 "Pattern6" 5 "Pattern5" 4 "Pattern4" 3 "Pattern3" 2 "Pattern2" 1 "Pattern1" 0 "Null" ;
VAL_ 677 SeatMasgDrvRr_D_Rq2 15 "NotUsed_10" 14 "NotUsed_9" 13 "NotUsed_8" 12 "NotUsed_7" 11 "NotUsed_6" 10 "Pattern10" 9 "Pattern9" 8 "Pattern8" 7 "Pattern7" 6 "Pattern6" 5 "Pattern5" 4 "Pattern4" 3 "Pattern3" 2 "Pattern2" 1 "Pattern1" 0 "Null" ;
VAL_ 677 SeatFnChngPsgr2_D_Rq3 15 "Faulty" 14 "NotUsed9" 13 "NotUsed8" 12 "NotUsed7" 11 "NotUsed6" 10 "High_2" 9 "Med_2" 8 "Low_2" 7 "Off_2" 6 "High" 5 "Low" 4 "Off" 3 "Decrease" 2 "Increase" 1 "NotUsed1" 0 "Inactive" ;
VAL_ 677 SeatFnChngDrv2_D_Rq3 15 "Faulty" 14 "NotUsed9" 13 "NotUsed8" 12 "NotUsed7" 11 "NotUsed6" 10 "High_2" 9 "Med_2" 8 "Low_2" 7 "Off_2" 6 "High" 5 "Low" 4 "Off" 3 "Decrease" 2 "Increase" 1 "NotUsed1" 0 "Inactive" ;
VAL_ 486 ResponseCode_No_Res 3 "NotUsed" 2 "Accepted" 1 "NotAccepted" 0 "Null" ;
VAL_ 486 ACU_ARAudioSource_Rsp 15 "iPod" 14 "USB" 13 "BTAudio" 0 "AmfmRadio" 1 "FrontDisc" 2 "SDARS_DAB" 3 "InDashCdChanger" 4 "VoiceRecogniser" 5 "TelematicUnit" 6 "BluetoothPhone" 7 "RearDisc" 8 "APIM" 9 "FrontAuxInput" 10 "Navigation" 11 "RearAux" 12 "NotReq" ;
VAL_ 486 ACU_AROperationType_Rsp 0 "Inactive" 1 "Requestaudioresource" 2 "Releaseaudioresource" 3 "Releaseallaudioresouces" 4 "Getresourceupdate" 5 "Getallresourceupdates" ;
VAL_ 486 ACU_ARReqstrSystem_Rsp 0 "FrontRequester" 1 "RearRequester" ;
VAL_ 486 ACU_ARResponse_Rsp 0 "Inactive" 1 "RequestAccepted" 2 "RequestAcceptedWoCtrl" 3 "RequestDenied" 4 "RessourceUpdateStatus" ;
VAL_ 486 ACU_ARReqstrPriority_Rp 0 "EmergencyServ" 1 "TelService" 2 "AutoAnswer" 3 "Ta" 4 "PttMutevoice" 5 "NavUserVoiceCmd" 6 "NavSysVoiceCmd" 7 "Radio" 8 "Disc" 9 "Alarm" 10 "Ptynews" 11 "Aux_ExtSource" 12 "MobileNavAndTelMute" 13 "ManualAudioMute" 14 "NotReq" ;
VAL_ 486 ACU_RUAudioSource_St 15 "iPod" 14 "USB" 13 "BTAudio" 0 "AmfmRadio" 1 "FrontDisc" 2 "SDARS_DAB" 3 "InDashCdChanger" 4 "VoiceRecogniser" 5 "TelematicUnit" 6 "BluetoothPhone" 7 "RearDisc" 8 "APIM" 9 "FrontAuxInput" 10 "Navigation" 11 "RearAux" 12 "NotReq" ;
VAL_ 486 ACU_RUReqstrSystem_St 0 "FrontRequester" 1 "RearRequester" ;
VAL_ 486 ACU_RUResReqstStatus_St 0 "NoResourceupdate" 1 "Deallocated" 2 "Allocated" 3 "Stacked" 4 "Granted" 5 "GrantedNoControlOfAudioSrc" ;
VAL_ 486 ACU_RUReqstrPriority_St 0 "EmergencyServ" 1 "TelService" 2 "AutoAnswer" 3 "Ta" 4 "PttMutevoice" 5 "NavUserVoiceCmd" 6 "NavSysVoiceCmd" 7 "Radio" 8 "Disc" 9 "Alarm" 10 "Ptynews" 11 "Aux_ExtSource" 12 "MobileNavAndTelMute" 13 "ManualAudioMute" 14 "NotReq" ;
VAL_ 930 BalrWndwRight_D_Confg 3 "Four" 2 "Two" 1 "One" 0 "Zero" ;
VAL_ 930 BalrWndwRight_B_Stat 1 "Enable" 0 "Disable" ;
VAL_ 930 BalrSnsRight_D_Falt 3 "Invalid" 2 "SystemFailure" 1 "Blocked" 0 "Clear" ;
VAL_ 930 WndwPsngrRear_D_RqBalrr 3 "NotUsed" 2 "Stop" 1 "AutoUp" 0 "NoRequest" ;
VAL_ 930 WndwPsngr_D_RqBalrr 3 "NotUsed" 2 "Stop" 1 "AutoUp" 0 "NoRequest" ;
VAL_ 930 WndwDrvRear_D_RqBalrr 3 "NotUsed" 2 "Stop" 1 "AutoUp" 0 "NoRequest" ;
VAL_ 930 WndwDrv_D_RqBalrr 3 "NotUsed" 2 "Stop" 1 "AutoUp" 0 "NoRequest" ;
VAL_ 930 BalrRight_D_Stat 3 "Inhibited" 2 "Disabled" 1 "On" 0 "Off" ;
VAL_ 930 BalrMdeSelRight_B_Stat 1 "Enable" 0 "Disable" ;
VAL_ 930 BalrMdeRight_D_Stat 3 "NotUsed" 2 "High" 1 "Medium" 0 "Low" ;
VAL_ 930 BalrLckRight_B_Stat 1 "Enable" 0 "Disable" ;
VAL_ 930 BalrLckRight_B_Confg 1 "Enable" 0 "Disable" ;
VAL_ 930 BalrInnrRight_D_Stat 3 "Reporting" 2 "NotReporting" 1 "SystemStandby" 0 "Initialization" ;
VAL_ 930 BalrDfaltRight_D_Stat 3 "NotUsed" 2 "High" 1 "Medium" 0 "Low" ;
VAL_ 930 BalrChimeRight_D_Rq 3 "NotUsed" 2 "Soft" 1 "Normal" 0 "Off" ;
VAL_ 930 CamraRearOn_B_RqBalrr 1 "Active" 0 "Inactive" ;
VAL_ 930 DrLckActv_B_RqBalrr 1 "Active" 0 "Null" ;
VAL_ 929 BalrChimeLeft_D_Rq 3 "NotUsed" 2 "Soft" 1 "Normal" 0 "Off" ;
VAL_ 929 BalrLeft_D_Stat 3 "Inhibited" 2 "Disabled" 1 "On" 0 "Off" ;
VAL_ 929 BalrWndwLeft_B_Stat 1 "Enable" 0 "Disable" ;
VAL_ 929 WndwPsngrRear_D_RqBalrl 3 "NotUsed" 2 "Stop" 1 "AutoUp" 0 "NoRequest" ;
VAL_ 929 WndwPsngr_D_RqBalrl 3 "NotUsed" 2 "Stop" 1 "AutoUp" 0 "NoRequest" ;
VAL_ 929 WndwDrvRear_D_RqBalrl 3 "NotUsed" 2 "Stop" 1 "AutoUp" 0 "NoRequest" ;
VAL_ 929 WndwDrv_D_RqBalrl 3 "NotUsed" 2 "Stop" 1 "AutoUp" 0 "NoRequest" ;
VAL_ 929 BalrSnsLeft_D_Falt 3 "Invalid" 2 "SystemFailure" 1 "Blocked" 0 "Clear" ;
VAL_ 929 BalrMdeSelLeft_B_Stat 1 "Enable" 0 "Disable" ;
VAL_ 929 BalrMdeLeft_D_Stat 3 "NotUsed" 2 "High" 1 "Medium" 0 "Low" ;
VAL_ 929 BalrLckLeft_B_Stat 1 "Enable" 0 "Disable" ;
VAL_ 929 CamraRearOn_B_RqBalrl 1 "Active" 0 "Inactive" ;
VAL_ 929 DrLckActv_B_RqBalrl 1 "Active" 0 "Null" ;
VAL_ 847 FldngSeatPwOffOk_B_Stat 1 "Yes" 0 "No" ;
VAL_ 966 TrnkFrontInhbt_B_Stat 1 "Inhibit" 0 "NoInhibit" ;
VAL_ 966 TrnkFrontScnd_B_Falt 1 "Fault" 0 "No_Fault" ;
VAL_ 966 ExtLghtRear_D_RqBody 3 "NotUsed" 2 "On" 1 "Off" 0 "Null" ;
VAL_ 966 TrnkFrontRleas_D_Src 7 "NotUsed_3" 6 "NotUsed_2" 5 "NotUsed_1" 4 "Cpp" 3 "Sync" 2 "Keypad" 1 "Remote" 0 "Null" ;
VAL_ 965 PtWakeupActv4_B_Rq 1 "On" 0 "Off" ;
VAL_ 965 TrnkFrontPrim_B_Falt 1 "Fault" 0 "No_Fault" ;
VAL_ 965 TrnkFrontEmgcy_D_Stat 3 "NotDetermined" 2 "SwitchState2" 1 "SwitchState1" 0 "NotPressed" ;
VAL_ 965 TrunkFrontOpen_D_Stat 3 "NotUsed" 2 "NotRestricted" 1 "Restricted" 0 "Null" ;
